VERSION ""

NS_ :

BS_:

BU_: SCCM RF_HUB PTS ORC OCM IC HCP HALF ETM ESM ESC EPS ECM EBCM DIAGNOST DASM CBC AirSusp TCM DTCM ELSDM

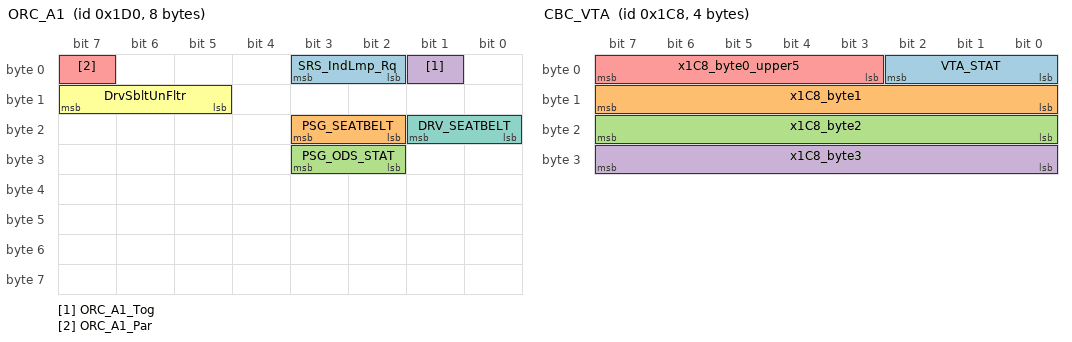
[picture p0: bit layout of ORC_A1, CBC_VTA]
BO_ 464 ORC_A1: 8 ORC
 SG_ SRS_IndLmp_Rq : 2|2@1+ (1,0) [0|0] ""  IC,ETM
 SG_ PSG_SEATBELT : 18|2@1+ (1,0) [0|0] ""  IC,ETM
 SG_ PSG_ODS_STAT : 26|2@1+ (1,0) [0|0] ""  IC
 SG_ ORC_A1_Tog : 1|1@1+ (1,0) [0|0] ""  DASM
 SG_ ORC_A1_Par : 7|1@1+ (1,0) [0|0] ""  DASM
 SG_ DrvSbltUnFltr : 13|3@1+ (1,0) [0|0] ""  ECM
 SG_ DRV_SEATBELT : 16|2@1+ (1,0) [0|0] ""  IC,ETM,ESC,DASM

BO_ 456 CBC_VTA: 4 CBC
 SG_ VTA_STAT : 0|3@1+ (1,0) [0|0] ""  ETM,RF_HUB
 SG_ x1C8_byte1 : 8|8@1+ (1,0) [0|255] "" Vector__XXX
 SG_ x1C8_byte2 : 16|8@1+ (1,0) [0|255] "" Vector__XXX
 SG_ x1C8_byte3 : 24|8@1+ (1,0) [0|255] "" Vector__XXX
 SG_ x1C8_byte0_upper5 : 3|5@1+ (1,0) [0|31] "" Vector__XXX

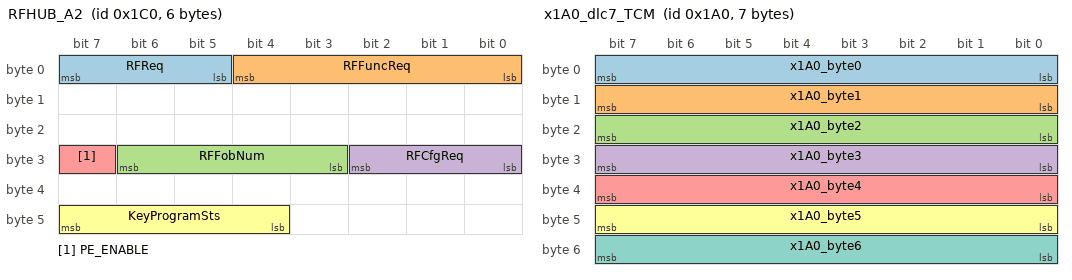
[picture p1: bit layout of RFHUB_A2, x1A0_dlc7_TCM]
BO_ 448 RFHUB_A2: 6 RF_HUB
 SG_ RFReq : 5|3@1+ (1,0) [0|0] ""  IC,CBC
 SG_ RFFuncReq : 0|5@1+ (1,0) [0|0] ""  IC,CBC
 SG_ RFFobNum : 27|4@1+ (1,0) [0|0] ""  CBC
 SG_ RFCfgReq : 24|3@1+ (1,0) [0|0] ""  CBC
 SG_ PE_ENABLE : 31|1@1+ (1,0) [0|0] ""  CBC
 SG_ KeyProgramSts : 44|4@1+ (1,0) [0|0] ""  IC

BO_ 416 x1A0_dlc7_TCM: 7 TCM
 SG_ x1A0_byte0 : 0|8@1+ (1,0) [0|255] "" Vector__XXX
 SG_ x1A0_byte1 : 8|8@1+ (1,0) [0|255] "" Vector__XXX
 SG_ x1A0_byte2 : 16|8@1+ (1,0) [0|255] "" Vector__XXX
 SG_ x1A0_byte3 : 24|8@1+ (1,0) [0|255] "" Vector__XXX
 SG_ x1A0_byte4 : 32|8@1+ (1,0) [0|255] "" Vector__XXX
 SG_ x1A0_byte5 : 40|8@1+ (1,0) [0|255] "" Vector__XXX
 SG_ x1A0_byte6 : 48|8@1+ (1,0) [0|255] "" Vector__XXX

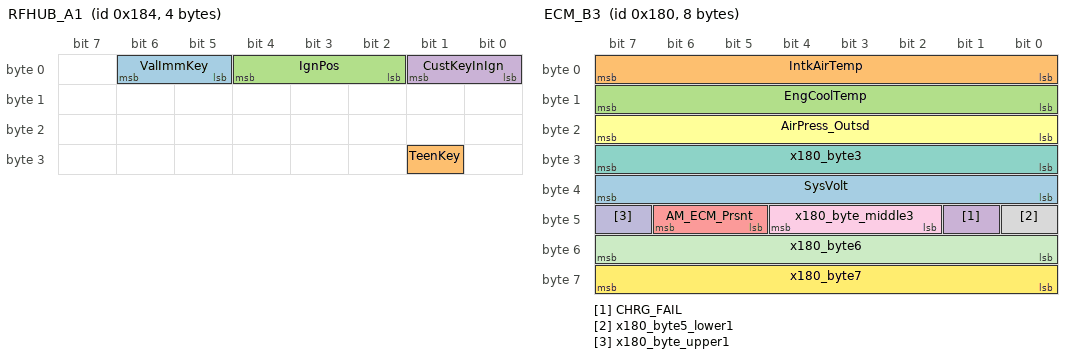
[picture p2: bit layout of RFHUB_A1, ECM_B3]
BO_ 388 RFHUB_A1: 4 RF_HUB
 SG_ ValImmKey : 5|2@1+ (1,0) [0|0] ""  CBC
 SG_ TeenKey : 25|1@1+ (1,0) [0|0] ""  CBC
 SG_ IgnPos : 2|3@1+ (1,0) [0|0] ""  CBC
 SG_ CustKeyInIgn : 0|2@1+ (1,0) [0|0] ""  CBC

BO_ 384 ECM_B3: 8 ECM
 SG_ SysVolt : 32|8@1+ (0.0618,0) [0|15.6972] "Volts"  HCP
 SG_ IntkAirTemp : 0|8@1+ (1,-40) [-40|214] "°C" Vector__XXX
 SG_ EngCoolTemp : 8|8@1+ (1,-40) [-40|214] "°C"  IC,ETM,ESC,CBC
 SG_ CHRG_FAIL : 41|1@1+ (1,0) [0|0] ""  IC,ETM
 SG_ AM_ECM_Prsnt : 45|2@1+ (1,0) [0|0] ""  CBC
 SG_ AirPress_Outsd : 16|8@1+ (1,0) [0|254] "kPaA"  RF_HUB,DASM
 SG_ x180_byte3 : 24|8@1+ (1,0) [0|0] "" Vector__XXX
 SG_ x180_byte5_lower1 : 40|1@1+ (1,0) [0|0] "" Vector__XXX
 SG_ x180_byte_middle3 : 42|3@1+ (1,0) [0|0] "" Vector__XXX
 SG_ x180_byte_upper1 : 47|1@1+ (1,0) [0|0] "" Vector__XXX
 SG_ x180_byte6 : 48|8@1+ (1,0) [0|0] "" Vector__XXX
 SG_ x180_byte7 : 56|8@1+ (1,0) [0|0] "" Vector__XXX

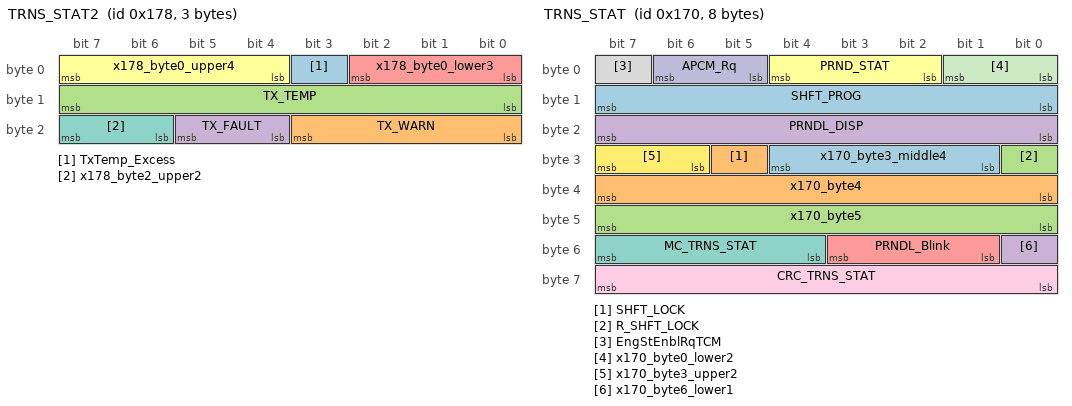
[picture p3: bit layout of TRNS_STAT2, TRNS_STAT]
BO_ 376 TRNS_STAT2: 3 TCM
 SG_ TxTemp_Excess : 3|1@1+ (1,0) [0|0] ""  IC,ETM
 SG_ TX_WARN : 16|4@1+ (1,0) [0|0] ""  IC
 SG_ TX_TEMP : 8|8@1+ (1,-50) [-50|204] "°C"  IC,HCP
 SG_ TX_FAULT : 20|2@1+ (1,0) [0|0] ""  RF_HUB,ECM
 SG_ x178_byte0_lower3 : 0|3@1+ (1,0) [0|7] "" Vector__XXX
 SG_ x178_byte0_upper4 : 4|4@1+ (1,0) [0|15] "" Vector__XXX
 SG_ x178_byte2_upper2 : 22|2@1+ (1,0) [0|3] "" Vector__XXX

BO_ 368 TRNS_STAT: 8 TCM
 SG_ SHFT_PROG : 8|8@1+ (1,0) [0|0] ""  ESC,ECM
 SG_ SHFT_LOCK : 29|1@1+ (1,0) [0|0] ""  ESM
 SG_ R_SHFT_LOCK : 24|1@1+ (1,0) [0|0] ""  ESM
 SG_ PRNDL_DISP : 16|8@1+ (1,0) [0|0] ""  ORC,IC,ESM,ESC,ECM,CBC
 SG_ PRNDL_Blink : 49|3@1+ (1,0) [0|0] ""  IC,ESM
 SG_ PRND_STAT : 2|3@1+ (1,0) [0|0] ""  PTS,ORC,IC,ESC,EPS,ECM,DASM,CBC
 SG_ MC_TRNS_STAT : 52|4@1+ (1,0) [0|15] ""  PTS,ESM,ESC,ECM,DASM
 SG_ EngStEnblRqTCM : 7|1@1+ (1,0) [0|0] "" Vector__XXX
 SG_ CRC_TRNS_STAT : 56|8@1+ (1,0) [0|0] ""  PTS,ESM,ESC,ECM,DASM
 SG_ APCM_Rq : 5|2@1+ (1,0) [0|0] ""  ESM
 SG_ x170_byte0_lower2 : 0|2@1+ (1,0) [0|0] "" Vector__XXX
 SG_ x170_byte3_upper2 : 30|2@1+ (1,0) [0|3] "" Vector__XXX
 SG_ x170_byte3_middle4 : 25|4@1+ (1,0) [0|15] "" Vector__XXX
 SG_ x170_byte4 : 32|8@1+ (1,0) [0|255] "" Vector__XXX
 SG_ x170_byte5 : 40|8@1+ (1,0) [0|255] "" Vector__XXX
 SG_ x170_byte6_lower1 : 48|1@1+ (1,0) [0|1] "" Vector__XXX

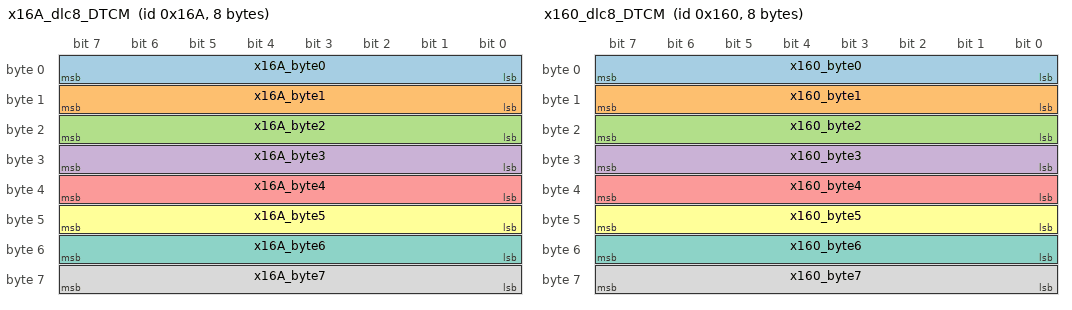
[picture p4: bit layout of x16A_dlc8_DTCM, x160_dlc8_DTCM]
BO_ 362 x16A_dlc8_DTCM: 8 DTCM
 SG_ x16A_byte0 : 0|8@1+ (1,0) [0|255] "" Vector__XXX
 SG_ x16A_byte1 : 8|8@1+ (1,0) [0|255] "" Vector__XXX
 SG_ x16A_byte2 : 16|8@1+ (1,0) [0|255] "" Vector__XXX
 SG_ x16A_byte3 : 24|8@1+ (1,0) [0|255] "" Vector__XXX
 SG_ x16A_byte4 : 32|8@1+ (1,0) [0|255] "" Vector__XXX
 SG_ x16A_byte5 : 40|8@1+ (1,0) [0|255] "" Vector__XXX
 SG_ x16A_byte6 : 48|8@1+ (1,0) [0|255] "" Vector__XXX
 SG_ x16A_byte7 : 56|8@1+ (1,0) [0|255] "" Vector__XXX

BO_ 352 x160_dlc8_DTCM: 8 DTCM
 SG_ x160_byte0 : 0|8@1+ (1,0) [0|255] "" Vector__XXX
 SG_ x160_byte1 : 8|8@1+ (1,0) [0|255] "" Vector__XXX
 SG_ x160_byte2 : 16|8@1+ (1,0) [0|255] "" Vector__XXX
 SG_ x160_byte3 : 24|8@1+ (1,0) [0|255] "" Vector__XXX
 SG_ x160_byte4 : 32|8@1+ (1,0) [0|255] "" Vector__XXX
 SG_ x160_byte5 : 40|8@1+ (1,0) [0|255] "" Vector__XXX
 SG_ x160_byte6 : 48|8@1+ (1,0) [0|255] "" Vector__XXX
 SG_ x160_byte7 : 56|8@1+ (1,0) [0|255] "" Vector__XXX

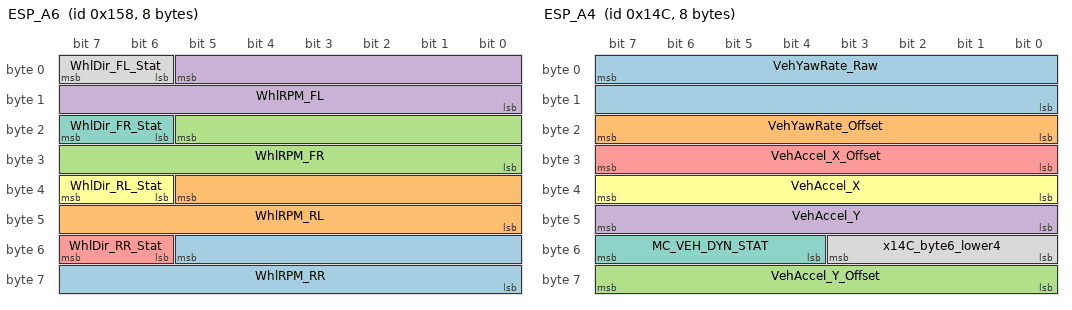
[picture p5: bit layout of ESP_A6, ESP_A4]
BO_ 344 ESP_A6: 8 ESC
 SG_ WhlRPM_RR : 53|14@0+ (0.5,0) [0|8191] "rpm"  PTS,ORC,HCP,DASM
 SG_ WhlRPM_RL : 37|14@0+ (0.5,0) [0|8191] "rpm"  PTS,ORC,HCP,DASM
 SG_ WhlRPM_FR : 21|14@0+ (0.5,0) [0|8191] "rpm"  PTS,ORC,HCP,DASM
 SG_ WhlRPM_FL : 5|14@0+ (0.5,0) [0|8191] "rpm"  PTS,ORC,HCP,DASM
 SG_ WhlDir_RR_Stat : 54|2@1+ (1,0) [0|0] ""  PTS,ORC,HCP,EPS,DASM
 SG_ WhlDir_RL_Stat : 38|2@1+ (1,0) [0|0] ""  PTS,ORC,HCP,EPS,DASM
 SG_ WhlDir_FR_Stat : 22|2@1+ (1,0) [0|0] ""  HCP,DASM
 SG_ WhlDir_FL_Stat : 6|2@1+ (1,0) [0|0] ""  HCP,DASM

BO_ 332 ESP_A4: 8 ESC
 SG_ VehYawRate_Raw : 7|16@0+ (0.01,-327.68) [-327.68|327.66] "°/s"  PTS,HALF,ETM,DASM,CBC
 SG_ VehYawRate_Offset : 16|8@1+ (0.08,-10.24) [-6.96|6.96] ""  ORC,HALF,DASM
 SG_ VehAccel_Y_Offset : 56|8@1+ (0.02,-2.56) [-2.56|2.52] "m/s²"  HALF,ETM,ECM,DASM
 SG_ VehAccel_Y : 40|8@1+ (0.08,-10.24) [-10.24|10.08] "m/s²"  HALF,EPS,ECM,DASM
 SG_ VehAccel_X_Offset : 24|8@1+ (0.02,-2.56) [-2.56|2.52] "m/s²"  PTS,HCP,HALF,ETM,ECM,DASM
 SG_ VehAccel_X : 32|8@1+ (0.08,-10.24) [-10.24|10.08] "m/s²"  PTS,HCP,HALF,EPS,ECM,DASM,CBC
 SG_ MC_VEH_DYN_STAT : 52|4@1+ (1,0) [0|15] ""  PTS,ORC,HALF,ETM,ECM,DASM
 SG_ x14C_byte6_lower4 : 48|4@1+ (1,0) [0|15] "" Vector__XXX

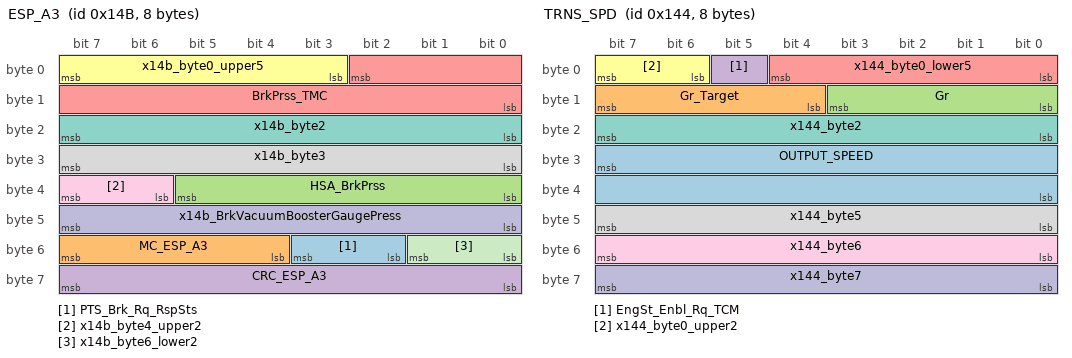
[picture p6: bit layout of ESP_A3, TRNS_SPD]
BO_ 331 ESP_A3: 8 ESC
 SG_ PTS_Brk_Rq_RspSts : 50|2@1+ (1,0) [0|0] ""  PTS,IC
 SG_ MC_ESP_A3 : 52|4@1+ (1,0) [0|15] ""  PTS,ORC,HCP,ECM
 SG_ HSA_BrkPrss : 32|6@1+ (1,0) [0|50] "bar"  ORC,ETM,ECM
 SG_ CRC_ESP_A3 : 56|8@1+ (1,0) [0|0] ""  PTS,ORC,HCP,ECM
 SG_ BrkPrss_TMC : 2|11@0+ (0.1,0) [0|200] "bar"  ORC,HCP,HALF,ETM,ECM
 SG_ x14b_byte0_upper5 : 3|5@1+ (1,0) [0|31] "" Vector__XXX
 SG_ x14b_byte2 : 16|8@1+ (1,0) [0|255] "" Vector__XXX
 SG_ x14b_byte3 : 24|8@1+ (1,0) [0|255] "" Vector__XXX
 SG_ x14b_byte4_upper2 : 38|2@1+ (1,0) [0|3] "" Vector__XXX
 SG_ x14b_BrkVacuumBoosterGaugePress : 40|8@1+ (-0.8,20.8) [-100|0] "kPa_gauge" Vector__XXX
 SG_ x14b_byte6_lower2 : 48|2@1+ (1,0) [0|3] "" Vector__XXX

BO_ 324 TRNS_SPD: 8 TCM
 SG_ OUTPUT_SPEED : 31|16@0+ (1,0) [0|65534] "rpm"  ECM
 SG_ Gr_Target : 12|4@1+ (1,0) [0|0] ""  ESC,ECM,CBC
 SG_ Gr : 8|4@1+ (1,0) [0|0] ""  RF_HUB,ORC,IC,HALF,ESC,EPS,ECM,CBC
 SG_ EngSt_Enbl_Rq_TCM : 5|1@1+ (1,0) [0|0] ""  RF_HUB,ECM
 SG_ x144_byte0_lower5 : 0|5@1+ (1,0) [0|31] "" Vector__XXX
 SG_ x144_byte0_upper2 : 6|2@1+ (1,0) [0|3] "" Vector__XXX
 SG_ x144_byte2 : 16|8@1+ (1,0) [0|255] "" Vector__XXX
 SG_ x144_byte5 : 40|8@1+ (1,0) [0|255] "" Vector__XXX
 SG_ x144_byte6 : 48|8@1+ (1,0) [0|255] "" Vector__XXX
 SG_ x144_byte7 : 56|8@1+ (1,0) [0|255] "" Vector__XXX

BO_ 320 ESP_A1: 8 ESC
 SG_ SPCR_AS_Off_Rq : 38|2@1+ (1,0) [0|0] ""  ECM,DASM
 SG_ RollTestMd_Actv : 30|2@1+ (1,0) [0|0] ""  DASM
 SG_ REF_VEH_SPEED : 33|10@0+ (0.5,0) [0|511] "km/h"  ORC,HCP
 SG_ MC_Brk_Stat : 52|4@1+ (1,0) [0|15] ""  PTS,ORC,IC,HCP,HALF,ECM,DASM
 SG_ FullBrk_Actv : 9|1@1+ (1,0) [0|0] ""  ORC
 SG_ ESP_Sys_Stat : 10|2@1+ (1,0) [0|0] ""  PTS,HALF,ETM,ECM,DASM
 SG_ EmgBrk_Actv : 8|1@1+ (1,0) [0|0] ""  ORC
 SG_ DTR_CC_Engaged : 15|1@1+ (1,0) [0|0] ""  HCP,ECM,CBC
 SG_ DTR_CC_Enabled : 23|1@1+ (1,0) [0|0] ""  ECM
 SG_ CRC_Brk_Stat : 56|8@1+ (1,0) [0|0] ""  PTS,ORC,IC,HCP,HALF,ECM,DASM
 SG_ BrkPdl_Stat : 2|2@1+ (1,0) [0|0] ""  RF_HUB,ORC,HCP,HALF,ECM,DASM,CBC
 SG_ BrkPdl_Flt : 4|1@1+ (1,0) [0|0] ""  HALF,ECM,DASM
 SG_ BrkIntrvntn_Enbl : 7|1@1+ (1,0) [0|0] ""  ORC,ECM
 SG_ BrkIntrvntn_Actv_ESP : 5|1@1+ (1,0) [0|0] ""  PTS,ORC,HALF,ETM
 SG_ BrkIntrvntn_Actv_AS : 6|1@1+ (1,0) [0|0] ""  ETM,DASM
 SG_ Brk_Thermdl : 25|1@1+ (1,0) [0|0] ""  DASM
 SG_ Brk_Stat : 0|2@1+ (1,0) [0|0] ""  PTS,HALF,ECM,DASM,CBC
 SG_ ABS_BrkEvt : 14|1@1+ (1,0) [0|0] ""  PTS,ORC,HALF,DASM
 SG_ x140_byte1_middle2 : 12|2@1+ (1,0) [0|3] "" Vector__XXX
 SG_ x140_byte2_lower7 : 16|7@1+ (1,0) [0|127] "" Vector__XXX
 SG_ x140_byte3_lower1 : 24|1@1+ (1,0) [0|1] "" Vector__XXX
 SG_ x140_byte3_middle4 : 26|4@1+ (1,0) [0|15] "" Vector__XXX
 SG_ x140_byte4_middle4 : 34|4@1+ (1,0) [0|15] "" Vector__XXX
 SG_ x140_byte6_lower4 : 48|4@1+ (1,0) [0|15] "" Vector__XXX

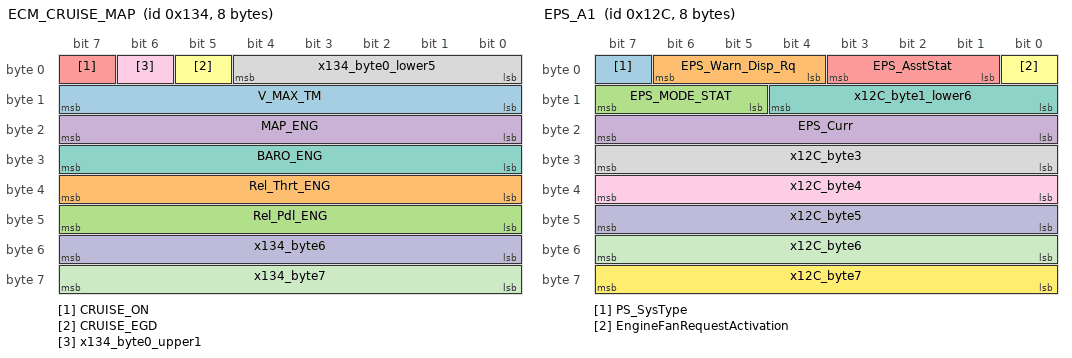
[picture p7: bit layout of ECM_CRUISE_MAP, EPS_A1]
BO_ 308 ECM_CRUISE_MAP: 8 ECM
 SG_ V_MAX_TM : 8|8@1+ (1,0) [0|250] "km/h(mph)"  HCP
 SG_ Rel_Thrt_ENG : 32|8@1+ (0.019607843,0) [0|4.98] "Volts"  ESC
 SG_ Rel_Pdl_ENG : 40|8@1+ (0.019607843,0) [0|4.98] "Volts"  ESC
 SG_ MAP_ENG : 16|8@1+ (0.8,0) [0|203.2] "kPa"  ETM,ESC
 SG_ CRUISE_ON : 7|1@1+ (1,0) [0|0] ""  ORC,IC,ESC
 SG_ CRUISE_EGD : 5|1@1+ (1,0) [0|0] ""  ORC,IC,HCP,ESC,CBC
 SG_ BARO_ENG : 24|8@1+ (1,0) [0|254] "kPaA"  ESC
 SG_ x134_byte0_lower5 : 0|5@1+ (1,0) [0|0] "" Vector__XXX
 SG_ x134_byte0_upper1 : 6|1@1+ (1,0) [0|0] "" Vector__XXX
 SG_ x134_byte6 : 48|8@1+ (1,0) [0|0] "" Vector__XXX
 SG_ x134_byte7 : 56|8@1+ (1,0) [0|0] "" Vector__XXX

BO_ 300 EPS_A1: 8 EPS
 SG_ PS_SysType : 7|1@1+ (1,0) [0|0] ""  ESC,CBC
 SG_ EPS_Warn_Disp_Rq : 4|3@1+ (1,0) [0|0] ""  ORC,IC,ETM,CBC
 SG_ EPS_MODE_STAT : 13|3@1+ (1,0) [0|0] ""  ORC,HALF,CBC
 SG_ EPS_Curr : 16|8@1+ (1,-50) [-50|204] "Amp" Vector__XXX
 SG_ EPS_AsstStat : 1|3@1+ (1,0) [0|0] ""  ESC
 SG_ EngineFanRequestActivation : 0|1@1+ (1,0) [0|0] ""  ECM
 SG_ x12C_byte1_lower6 : 8|5@1+ (1,0) [0|31] "" Vector__XXX
 SG_ x12C_byte3 : 24|8@1+ (1,0) [0|255] "" Vector__XXX
 SG_ x12C_byte4 : 32|8@1+ (1,0) [0|255] "" Vector__XXX
 SG_ x12C_byte5 : 40|8@1+ (1,0) [0|255] "" Vector__XXX
 SG_ x12C_byte6 : 48|8@1+ (1,0) [0|255] "" Vector__XXX
 SG_ x12C_byte7 : 56|8@1+ (1,0) [0|255] "" Vector__XXX

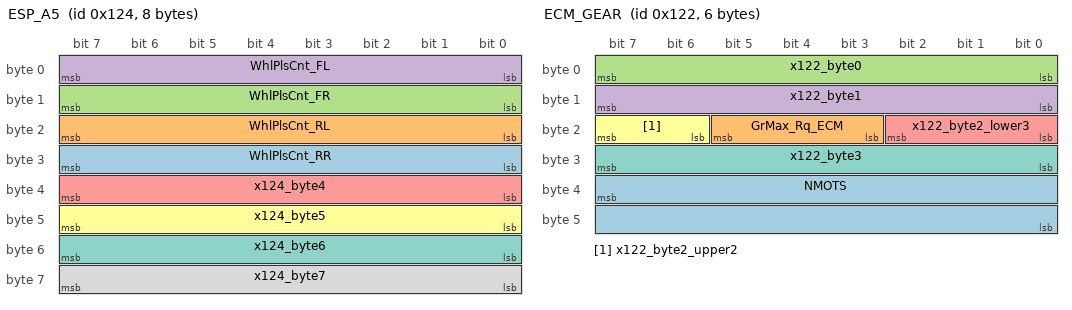
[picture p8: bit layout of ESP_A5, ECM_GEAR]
BO_ 292 ESP_A5: 8 ESC
 SG_ WhlPlsCnt_RR : 24|8@1+ (1,0) [0|254] "Impulse"  RF_HUB,PTS,EPS,DASM,CBC
 SG_ WhlPlsCnt_RL : 16|8@1+ (1,0) [0|254] "Impulse"  RF_HUB,PTS,EPS,DASM,CBC
 SG_ WhlPlsCnt_FR : 8|8@1+ (1,0) [0|254] "Impulse"  RF_HUB,PTS,DASM,CBC
 SG_ WhlPlsCnt_FL : 0|8@1+ (1,0) [0|254] "Impulse"  RF_HUB,PTS,DASM,CBC
 SG_ x124_byte4 : 32|8@1+ (1,0) [0|255] "" Vector__XXX
 SG_ x124_byte5 : 40|8@1+ (1,0) [0|255] "" Vector__XXX
 SG_ x124_byte6 : 48|8@1+ (1,0) [0|255] "" Vector__XXX
 SG_ x124_byte7 : 56|8@1+ (1,0) [0|255] "" Vector__XXX

BO_ 290 ECM_GEAR: 6 ECM
 SG_ NMOTS : 39|16@0+ (1,0) [0|65534] "rpm"  ESC
 SG_ GrMax_Rq_ECM : 19|3@1+ (1,0) [0|0] "" Vector__XXX
 SG_ x122_byte0 : 0|8@1+ (1,0) [0|0] "" Vector__XXX
 SG_ x122_byte1 : 8|8@1+ (1,0) [0|0] "" Vector__XXX
 SG_ x122_byte2_lower3 : 16|3@1+ (1,0) [0|0] "" Vector__XXX
 SG_ x122_byte2_upper2 : 22|2@1+ (1,0) [0|0] "" Vector__XXX
 SG_ x122_byte3 : 24|8@1+ (1,0) [0|0] "" Vector__XXX

BO_ 288 ECM_A2: 7 ECM
 SG_ RPMOverRev : 42|1@1+ (1,0) [0|0] "" Vector__XXX
 SG_ MC_ECM_A2 : 44|4@1+ (1,0) [0|15] ""  HALF,DASM,ESC
 SG_ LV12PwrFreeRq : 43|1@1+ (1,0) [0|0] ""  DASM,ESC
 SG_ ESS_RqShftPark : 41|1@1+ (1,0) [0|0] ""  ORC
 SG_ EngTrq_Enbl_Rq_ESC : 6|1@1+ (1,0) [0|0] ""  DASM,ESC
 SG_ EngTrq_Enbl_Rq_AS : 5|1@1+ (1,0) [0|0] ""  ESC,DASM
 SG_ ECM_LHOM : 29|1@1+ (1,0) [0|0] ""  DASM
 SG_ CRUISE_OVERRIDE : 31|1@1+ (1,0) [0|0] ""  ORC,HCP,ESC,DASM
 SG_ CRC_ECM_A2 : 48|8@1+ (1,0) [0|0] ""  HALF,DASM,ESC
 SG_ AccelPdlPosnSens_Flt : 30|1@1+ (1,0) [0|0] ""  HALF,DASM,ESC,CBC
 SG_ AccelPdlPosn : 16|8@1+ (0.4,0) [0|100] "%"  HALF,ESC,CBC
 SG_ x120_byte0_lower5 : 0|5@1+ (1,0) [0|0] "" Vector__XXX
 SG_ x120_byte0_upper1 : 7|1@1+ (1,0) [0|0] "" Vector__XXX
 SG_ x120_byte1 : 8|8@1+ (1,0) [0|0] "" Vector__XXX
 SG_ x120_byte3_lower5 : 24|5@1+ (1,0) [0|0] "" Vector__XXX
 SG_ x120_byte4 : 32|8@1+ (1,0) [0|0] "" Vector__XXX
 SG_ x120_byte5_lowre1 : 40|1@1+ (1,0) [0|0] "" Vector__XXX

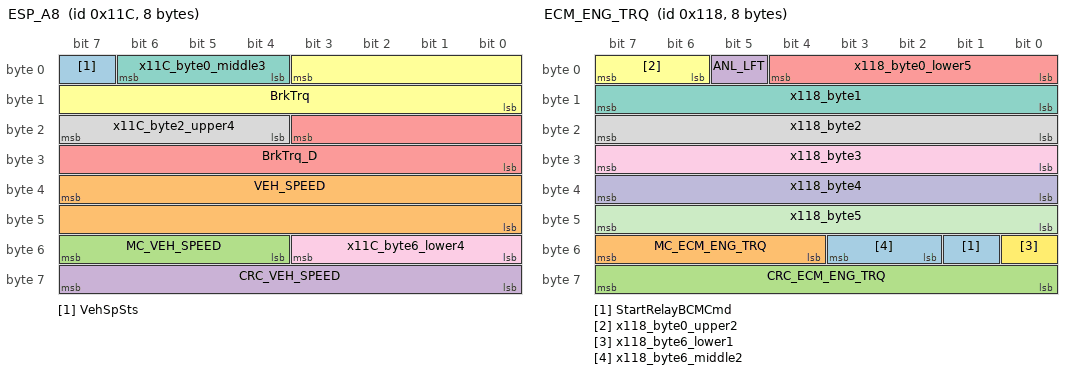
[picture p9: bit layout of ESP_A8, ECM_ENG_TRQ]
BO_ 284 ESP_A8: 8 ESC
 SG_ VehSpSts : 7|1@1+ (1,0) [0|0] ""  DASM
 SG_ VEH_SPEED : 39|16@0+ (0.0078125,0) [0|511.984375] "km/h"  RF_HUB,PTS,ORC,IC,HCP,HALF,EPS,ECM,EBCM,DASM,CBC
 SG_ MC_VEH_SPEED : 52|4@1+ (1,0) [0|15] ""  PTS,ORC,IC,HCP,HALF,ESM,EPS,ECM,DASM
 SG_ CRC_VEH_SPEED : 56|8@1+ (1,0) [0|0] ""  PTS,ORC,IC,HCP,HALF,ESM,EPS,ECM,DASM
 SG_ BrkTrq_D : 19|12@0+ (3,0) [0|12282] "Nm"  DASM
 SG_ BrkTrq : 3|12@0+ (3,0) [0|12282] "Nm"  ORC,DASM
 SG_ x11C_byte0_middle3 : 4|3@1+ (1,0) [0|7] "" Vector__XXX
 SG_ x11C_byte2_upper4 : 20|4@1+ (1,0) [0|15] "" Vector__XXX
 SG_ x11C_byte6_lower4 : 48|4@1+ (1,0) [0|15] "" Vector__XXX

BO_ 280 ECM_ENG_TRQ: 8 ECM
 SG_ StartRelayBCMCmd : 49|1@1+ (1,0) [0|0] ""  CBC
 SG_ MC_ECM_ENG_TRQ : 52|4@1+ (1,0) [0|15] ""  ESC
 SG_ CRC_ECM_ENG_TRQ : 56|8@1+ (1,0) [0|0] ""  DASM,ESC
 SG_ ANL_LFT : 5|1@1+ (1,0) [0|0] ""  CBC
 SG_ x118_byte0_lower5 : 0|5@1+ (1,0) [0|0] "" Vector__XXX
 SG_ x118_byte0_upper2 : 6|2@1+ (1,0) [0|0] "" Vector__XXX
 SG_ x118_byte1 : 8|8@1+ (1,0) [0|0] "" Vector__XXX
 SG_ x118_byte2 : 16|8@1+ (1,0) [0|0] "" Vector__XXX
 SG_ x118_byte3 : 24|8@1+ (1,0) [0|0] "" Vector__XXX
 SG_ x118_byte4 : 32|8@1+ (1,0) [0|0] "" Vector__XXX
 SG_ x118_byte5 : 40|8@1+ (1,0) [0|0] "" Vector__XXX
 SG_ x118_byte6_lower1 : 48|1@1+ (1,0) [0|0] "" Vector__XXX
 SG_ x118_byte6_middle2 : 50|2@1+ (1,0) [0|0] "" Vector__XXX

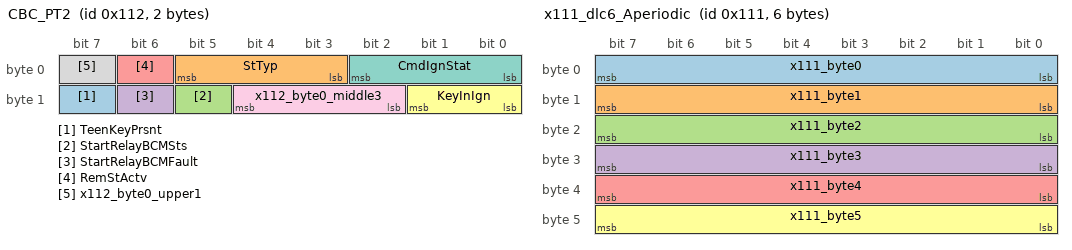
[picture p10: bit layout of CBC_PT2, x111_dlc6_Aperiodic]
BO_ 274 CBC_PT2: 2 CBC
 SG_ TeenKeyPrsnt : 15|1@1+ (1,0) [0|0] ""  PTS,ORC,IC,ECM,DASM
 SG_ StTyp : 3|3@1+ (1,0) [0|0] ""  RF_HUB
 SG_ StartRelayBCMSts : 13|1@1+ (1,0) [0|0] ""  ECM
 SG_ StartRelayBCMFault : 14|1@1+ (1,0) [0|0] ""  ECM
 SG_ RemStActv : 6|1@1+ (1,0) [0|0] ""  RF_HUB,IC,HCP,ESM,ECM
 SG_ KeyInIgn : 8|2@1+ (1,0) [0|0] ""  RF_HUB,IC,HCP,ESM
 SG_ CmdIgnStat : 0|3@1+ (1,0) [0|0] ""  SCCM,RF_HUB,PTS,ORC,OCM,IC,HCP,HALF,ESM,ESC,EPS,ECM,EBCM,DASM
 SG_ x112_byte0_upper1 : 7|1@1+ (1,0) [0|1] "" Vector__XXX
 SG_ x112_byte0_middle3 : 10|3@1+ (1,0) [0|7] "" Vector__XXX

BO_ 273 x111_dlc6_Aperiodic: 6 Vector__XXX
 SG_ x111_byte0 : 0|8@1+ (1,0) [0|255] "" Vector__XXX
 SG_ x111_byte1 : 8|8@1+ (1,0) [0|255] "" Vector__XXX
 SG_ x111_byte2 : 16|8@1+ (1,0) [0|255] "" Vector__XXX
 SG_ x111_byte3 : 24|8@1+ (1,0) [0|255] "" Vector__XXX
 SG_ x111_byte4 : 32|8@1+ (1,0) [0|255] "" Vector__XXX
 SG_ x111_byte5 : 40|8@1+ (1,0) [0|255] "" Vector__XXX

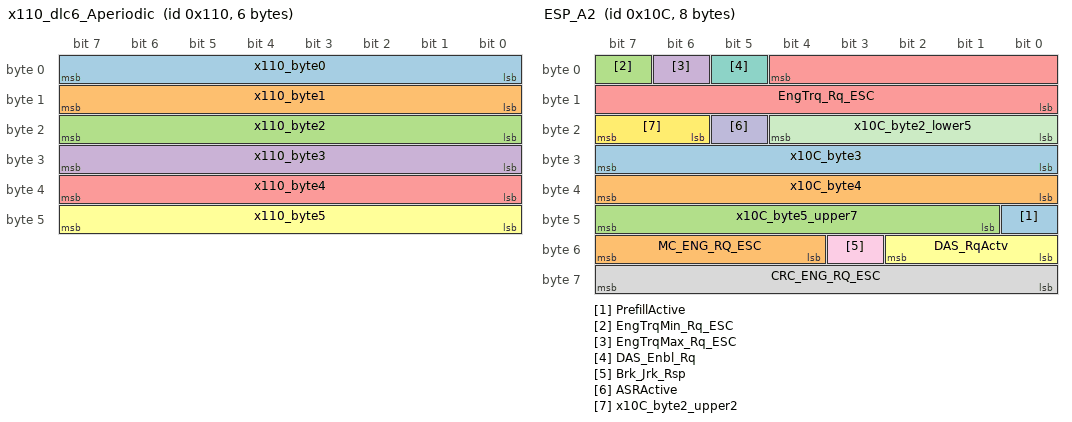
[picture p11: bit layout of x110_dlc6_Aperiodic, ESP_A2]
BO_ 272 x110_dlc6_Aperiodic: 6 Vector__XXX
 SG_ x110_byte0 : 0|8@1+ (1,0) [0|255] "" Vector__XXX
 SG_ x110_byte1 : 8|8@1+ (1,0) [0|255] "" Vector__XXX
 SG_ x110_byte2 : 16|8@1+ (1,0) [0|255] "" Vector__XXX
 SG_ x110_byte3 : 24|8@1+ (1,0) [0|255] "" Vector__XXX
 SG_ x110_byte4 : 32|8@1+ (1,0) [0|255] "" Vector__XXX
 SG_ x110_byte5 : 40|8@1+ (1,0) [0|255] "" Vector__XXX

BO_ 268 ESP_A2: 8 ESC
 SG_ PrefillActive : 40|1@1+ (1,0) [0|0] ""  DASM
 SG_ MC_ENG_RQ_ESC : 52|4@1+ (1,0) [0|15] ""  ECM,DASM
 SG_ EngTrqMin_Rq_ESC : 7|1@1+ (1,0) [0|0] "" Vector__XXX
 SG_ EngTrqMax_Rq_ESC : 6|1@1+ (1,0) [0|0] "" Vector__XXX
 SG_ EngTrq_Rq_ESC : 4|13@0+ (0.25,-500) [-500|1547.5] "Nm"  ETM
 SG_ DAS_RqActv : 48|3@1+ (1,0) [0|0] ""  ORC,HALF,DASM
 SG_ DAS_Enbl_Rq : 5|1@1+ (1,0) [0|0] ""  ECM,DASM
 SG_ CRC_ENG_RQ_ESC : 56|8@1+ (1,0) [0|0] ""  ECM,DASM
 SG_ Brk_Jrk_Rsp : 51|1@1+ (1,0) [0|0] ""  ORC,DASM
 SG_ ASRActive : 21|1@1+ (1,0) [0|0] ""  ORC,DASM
 SG_ x10C_byte2_lower5 : 16|5@1+ (1,0) [0|31] "" Vector__XXX
 SG_ x10C_byte2_upper2 : 22|2@1+ (1,0) [0|3] "" Vector__XXX
 SG_ x10C_byte3 : 24|8@1+ (1,0) [0|255] "" Vector__XXX
 SG_ x10C_byte4 : 32|8@1+ (1,0) [0|255] "" Vector__XXX
 SG_ x10C_byte5_upper7 : 41|7@1+ (1,0) [0|127] "" Vector__XXX

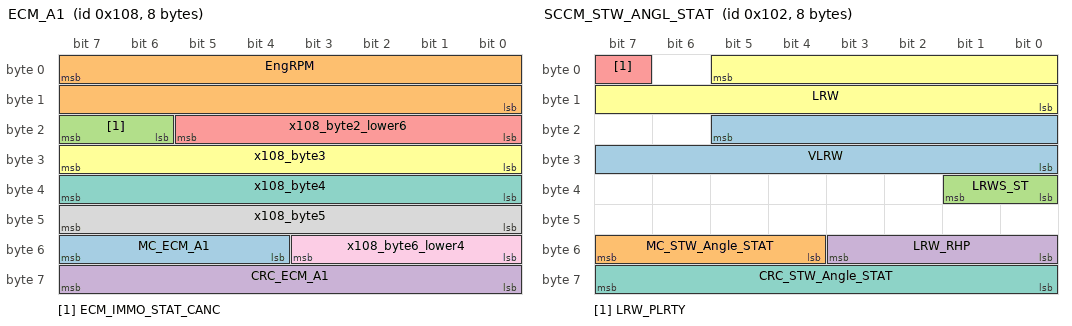
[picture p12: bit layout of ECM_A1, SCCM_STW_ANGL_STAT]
BO_ 264 ECM_A1: 8 ECM
 SG_ MC_ECM_A1 : 52|4@1+ (1,0) [0|15] ""  HALF,DASM,ESC
 SG_ EngRPM : 7|16@0+ (1,0) [0|65534] "rpm"  RF_HUB,ORC,IC,HALF,ESC,EPS,EBCM,CBC
 SG_ ECM_IMMO_STAT_CANC : 22|2@1+ (1,0) [0|0] ""  HCP,CBC
 SG_ CRC_ECM_A1 : 56|8@1+ (1,0) [0|0] ""  HALF,DASM,ESC
 SG_ x108_byte2_lower6 : 16|6@1+ (1,0) [0|63] "" Vector__XXX
 SG_ x108_byte3 : 24|8@1+ (1,0) [0|255] "" Vector__XXX
 SG_ x108_byte4 : 32|8@1+ (1,0) [0|255] "" Vector__XXX
 SG_ x108_byte5 : 40|8@1+ (1,0) [0|255] "" Vector__XXX
 SG_ x108_byte6_lower4 : 48|4@1+ (1,0) [0|15] "" Vector__XXX

BO_ 258 SCCM_STW_ANGL_STAT: 8 SCCM
 SG_ VLRW : 21|14@0+ (0.5,-2048) [-2048|2047] "°/s"  HALF,ESC,EPS,ECM,DASM
 SG_ MC_STW_Angle_STAT : 52|4@1+ (1,0) [0|15] ""  PTS,ORC,ETM,ESC,ECM,DASM
 SG_ LRWS_ST : 32|2@1+ (1,0) [0|0] ""  PTS,ORC,HALF,ESC,EPS,DASM,CBC
 SG_ LRW_RHP : 48|4@1+ (0.1,-0.4) [-0.4|0.4] "Degrees"  PTS,HALF,EPS
 SG_ LRW_PLRTY : 7|1@1+ (1,0) [0|0] ""  PTS,ORC,HALF,ESC,EPS,DASM
 SG_ LRW : 5|14@0+ (0.5,-2048) [-2048|2047] "Degrees"  PTS,ORC,HALF,ESC,EPS,ECM,DASM,CBC
 SG_ CRC_STW_Angle_STAT : 56|8@1+ (1,0) [0|0] ""  PTS,ORC,ETM,ESC,ECM,DASM

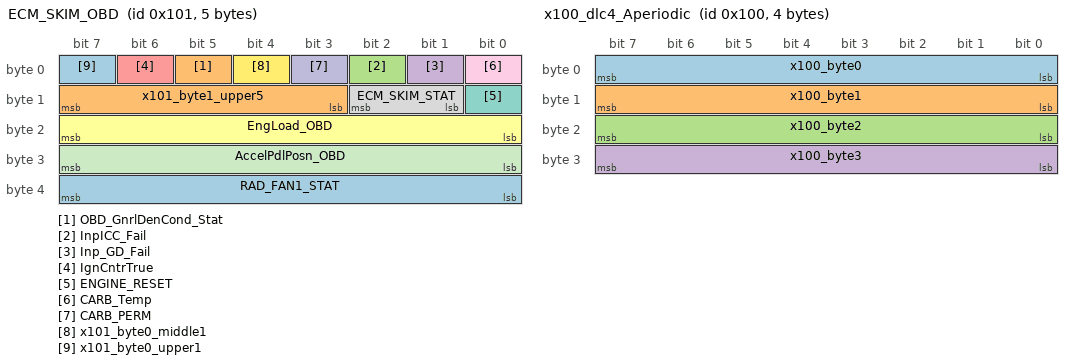
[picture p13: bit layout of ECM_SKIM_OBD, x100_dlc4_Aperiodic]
BO_ 257 ECM_SKIM_OBD: 5 ECM
 SG_ RAD_FAN1_STAT : 32|8@1+ (1,0) [0|100] "%"  ETM
 SG_ OBD_GnrlDenCond_Stat : 5|1@1+ (1,0) [0|0] "" Vector__XXX
 SG_ InpICC_Fail : 2|1@1+ (1,0) [0|0] "" Vector__XXX
 SG_ Inp_GD_Fail : 1|1@1+ (1,0) [0|0] "" Vector__XXX
 SG_ IgnCntrTrue : 6|1@1+ (1,0) [0|0] "" Vector__XXX
 SG_ EngLoad_OBD : 16|8@1+ (0.3922,0) [0|100] "%"  ETM,ESC,EBCM
 SG_ ENGINE_RESET : 8|1@1+ (1,0) [0|0] ""  HCP
 SG_ ECM_SKIM_STAT : 9|2@1+ (1,0) [0|0] "" Vector__XXX
 SG_ CARB_Temp : 0|1@1+ (1,0) [0|0] "" Vector__XXX
 SG_ CARB_PERM : 3|1@1+ (1,0) [0|0] "" Vector__XXX
 SG_ AccelPdlPosn_OBD : 24|8@1+ (0.3922,0) [0|100] "%"  ETM,ESC,EBCM
 SG_ x101_byte0_middle1 : 4|1@1+ (1,0) [0|1] "" Vector__XXX
 SG_ x101_byte0_upper1 : 7|1@1+ (1,0) [0|1] "" Vector__XXX
 SG_ x101_byte1_upper5 : 11|5@1+ (1,0) [0|31] "" Vector__XXX

BO_ 256 x100_dlc4_Aperiodic: 4 Vector__XXX
 SG_ x100_byte0 : 0|8@1+ (1,0) [0|255] "" Vector__XXX
 SG_ x100_byte1 : 8|8@1+ (1,0) [0|255] "" Vector__XXX
 SG_ x100_byte2 : 16|8@1+ (1,0) [0|255] "" Vector__XXX
 SG_ x100_byte3 : 24|8@1+ (1,0) [0|255] "" Vector__XXX

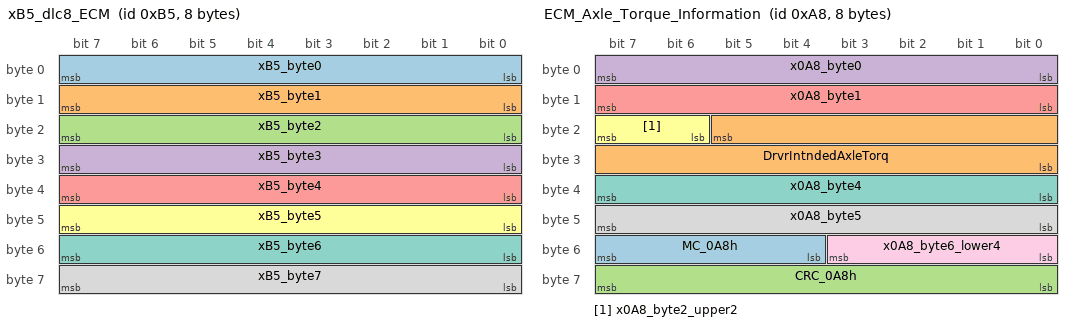
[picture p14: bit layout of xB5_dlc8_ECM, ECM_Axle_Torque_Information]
BO_ 181 xB5_dlc8_ECM: 8 ECM
 SG_ xB5_byte0 : 0|8@1+ (1,0) [0|255] "" Vector__XXX
 SG_ xB5_byte1 : 8|8@1+ (1,0) [0|255] "" Vector__XXX
 SG_ xB5_byte2 : 16|8@1+ (1,0) [0|255] "" Vector__XXX
 SG_ xB5_byte3 : 24|8@1+ (1,0) [0|255] "" Vector__XXX
 SG_ xB5_byte4 : 32|8@1+ (1,0) [0|255] "" Vector__XXX
 SG_ xB5_byte5 : 40|8@1+ (1,0) [0|255] "" Vector__XXX
 SG_ xB5_byte6 : 48|8@1+ (1,0) [0|255] "" Vector__XXX
 SG_ xB5_byte7 : 56|8@1+ (1,0) [0|255] "" Vector__XXX

BO_ 168 ECM_Axle_Torque_Information: 8 ECM
 SG_ MC_0A8h : 52|4@1+ (1,0) [0|15] ""  ESC,DASM
 SG_ DrvrIntndedAxleTorq : 21|14@0+ (1.5625,-4604.688) [-4604.688|20970.3125] "Nm"  ORC,ESC,DASM
 SG_ CRC_0A8h : 56|8@1+ (1,0) [0|0] ""  ESC,DASM
 SG_ x0A8_byte0 : 0|8@1+ (1,0) [0|0] "" Vector__XXX
 SG_ x0A8_byte1 : 8|8@1+ (1,0) [0|0] "" Vector__XXX
 SG_ x0A8_byte2_upper2 : 22|2@1+ (1,0) [0|0] "" Vector__XXX
 SG_ x0A8_byte4 : 32|8@1+ (1,0) [0|0] "" Vector__XXX
 SG_ x0A8_byte5 : 40|8@1+ (1,0) [0|0] "" Vector__XXX
 SG_ x0A8_byte6_lower4 : 48|4@1+ (1,0) [0|0] "" Vector__XXX

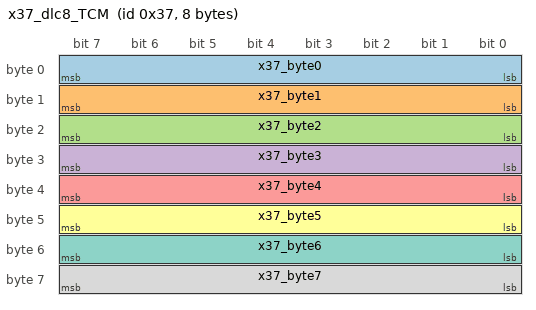
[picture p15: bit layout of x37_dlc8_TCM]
BO_ 55 x37_dlc8_TCM: 8 TCM
 SG_ x37_byte0 : 0|8@1+ (1,0) [0|255] "" Vector__XXX
 SG_ x37_byte1 : 8|8@1+ (1,0) [0|255] "" Vector__XXX
 SG_ x37_byte2 : 16|8@1+ (1,0) [0|255] "" Vector__XXX
 SG_ x37_byte3 : 24|8@1+ (1,0) [0|255] "" Vector__XXX
 SG_ x37_byte4 : 32|8@1+ (1,0) [0|255] "" Vector__XXX
 SG_ x37_byte5 : 40|8@1+ (1,0) [0|255] "" Vector__XXX
 SG_ x37_byte6 : 48|8@1+ (1,0) [0|255] "" Vector__XXX
 SG_ x37_byte7 : 56|8@1+ (1,0) [0|255] "" Vector__XXX

BO_ 2147484177 ESP_A3_NewEagle_A2D_Reads: 8 Vector__XXX
 SG_ NewEagle_BrakePosnSnsrA2d : 0|12@1+ (0.001221001221,0) [0|0] "V" Vector__XXX

BO_ 1083 NM_EBCM: 8 EBCM
 SG_ WakeupRsn_EBCM m2 : 32|8@1+ (1,0) [0|0] "" Vector__XXX
 SG_ WakeupCnt_EBCM m2 : 40|8@1+ (1,0) [0|254] "" Vector__XXX
 SG_ Nw_Id_EBCM : 56|8@1+ (1,0) [0|0] "" Vector__XXX
 SG_ NM_Ud_Srv_EBCM M : 24|8@1+ (1,0) [0|0] "" Vector__XXX
 SG_ NM_Ud_Launch_EBCM : 16|6@1+ (1,0) [0|0] "" Vector__XXX
 SG_ NM_Successor_EBCM : 8|8@1+ (1,0) [0|63] "" Vector__XXX
 SG_ NM_Sleep_Ind_EBCM : 23|1@1+ (1,0) [0|0] "" Vector__XXX
 SG_ NM_Sleep_Ack_EBCM : 22|1@1+ (1,0) [0|0] "" Vector__XXX
 SG_ NM_Mode_EBCM : 0|8@1+ (1,0) [0|0] "" Vector__XXX
 SG_ Awake_NwSt_EBCM m15 : 32|1@1+ (1,0) [0|0] "" Vector__XXX
 SG_ Awake_Diag_Actv_EBCM m15 : 33|1@1+ (1,0) [0|0] "" Vector__XXX

CM_ SG_ 464 SRS_IndLmp_Rq "SRS indication lamp request";
CM_ SG_ 464 PSG_SEATBELT "Passengers seat belt status";
CM_ SG_ 464 PSG_ODS_STAT "Passenger Occupant Detection Sensor Status";
CM_ SG_ 464 ORC_A1_Tog "ORC_A1 toggle bit";
CM_ SG_ 464 ORC_A1_Par "ORC_A1 even parity bit";
CM_ SG_ 464 DrvSbltUnFltr "Drivers seat belt fault status - unfiltered";
CM_ SG_ 464 DRV_SEATBELT "Drivers seat belt status";
CM_ SG_ 456 VTA_STAT "VTA status";
CM_ SG_ 448 RFReq "Who's asking for the request";
CM_ SG_ 448 RFFuncReq "Basic request (RKE, PE, Remstart)";
CM_ SG_ 448 RFFobNum "FOB number making the request";
CM_ SG_ 448 RFCfgReq "Change customer programmable items by RKE";
CM_ SG_ 448 PE_ENABLE "Passive entry feature enabled; [1] = True";
CM_ SG_ 448 KeyProgramSts "Key programming status";
CM_ BO_ 416 "Tx Rate: 20ms, Std Dev: 0.5ms";
CM_ SG_ 388 ValImmKey "Drivers request, immobilizer results";
CM_ SG_ 388 TeenKey "Teen key present; Present = [1]";
CM_ SG_ 388 IgnPos "Drivers request, ignition position";
CM_ SG_ 388 CustKeyInIgn "Driver's request, key-in-ignition";
CM_ SG_ 384 SysVolt "Engine system voltage";
CM_ SG_ 384 IntkAirTemp "Engine Intake Air Temperature";
CM_ SG_ 384 EngCoolTemp "Engine coolant temperature";
CM_ SG_ 384 CHRG_FAIL "Charging system Failure (battery indicator request)";
CM_ SG_ 384 AM_ECM_Prsnt "Aftermarket ECM present";
CM_ SG_ 384 AirPress_Outsd "Ambient air pressure (barometric pressure)";
CM_ SG_ 376 TxTemp_Excess "Excessive transmission temperature";
CM_ SG_ 376 TX_WARN "Transmission warning";
CM_ SG_ 376 TX_TEMP "Transmission fluid temperature";
CM_ SG_ 376 TX_FAULT "Transmission fault";
CM_ SG_ 368 SHFT_PROG "Driving program display code";
CM_ SG_ 368 SHFT_LOCK "Shiftlock state locked; false = [1]";
CM_ SG_ 368 R_SHFT_LOCK "Shiftlock for reverse; locked = [1]";
CM_ SG_ 368 PRNDL_DISP "PRNDL display request";
CM_ SG_ 368 PRNDL_Blink "Request gear shift display indicator blink";
CM_ SG_ 368 PRND_STAT "PRND Status";
CM_ SG_ 368 MC_TRNS_STAT "Message counter";
CM_ SG_ 368 EngStEnblRqTCM "Engine start enable request from the transmission";
CM_ SG_ 368 CRC_TRNS_STAT "CRC-checksum byte 1 to 7 according to SAE J1850";
CM_ SG_ 368 APCM_Rq "Auto position correction mode request";
CM_ SG_ 368 x170_byte0_lower2 "added by New Eagle to ensure checksums arent messed up if FCA adds a new signal";
CM_ SG_ 368 x170_byte3_upper2 "added by New Eagle to ensure checksums arent messed up if FCA adds a new signal";
CM_ SG_ 368 x170_byte3_middle4 "added by New Eagle to ensure checksums arent messed up if FCA adds a new signal";
CM_ SG_ 368 x170_byte4 "added by New Eagle to ensure checksums arent messed up if FCA adds a new signal";
CM_ SG_ 368 x170_byte5 "added by New Eagle to ensure checksums arent messed up if FCA adds a new signal";
CM_ SG_ 368 x170_byte6_lower1 "added by New Eagle to ensure checksums arent messed up if FCA adds a new signal";
CM_ BO_ 362 "Tx Rate: 20ms, Std Dev: 0.5ms";
CM_ BO_ 352 "Tx Rate: 20ms, Std Dev: 0.5ms";
CM_ SG_ 344 WhlRPM_RR "Wheel rpm rear right";
CM_ SG_ 344 WhlRPM_RL "Wheel rpm rear left";
CM_ SG_ 344 WhlRPM_FR "Wheel rpm front right";
CM_ SG_ 344 WhlRPM_FL "Wheel rpm front left";
CM_ SG_ 344 WhlDir_RR_Stat "Direction of rotation of rear right wheel";
CM_ SG_ 344 WhlDir_RL_Stat "Direction of rotation of rear left wheel";
CM_ SG_ 344 WhlDir_FR_Stat "Direction of rotation of front right wheel";
CM_ SG_ 344 WhlDir_FL_Stat "Direction of rotation of front left wheel";
CM_ SG_ 332 VehYawRate_Raw "Vehicle yaw rate unfiltered/unadjusted (+ means left)";
CM_ SG_ 332 VehYawRate_Offset "Offset of vehicle yaw rate unfiltered/unadjusted (+ means left)";
CM_ SG_ 332 VehAccel_Y_Offset "Offset of vehicle lateral acceleration (+ means left)";
CM_ SG_ 332 VehAccel_Y "Vehicle lateral acceleration (+ means left, specific to center of gravity, offset-corrected )";
CM_ SG_ 332 VehAccel_X_Offset "Offset of vehicle longitudinal acceleration (+ means forward)";
CM_ SG_ 332 VehAccel_X "Vehicle longitudinal acceleration (+ means forward)";
CM_ SG_ 332 MC_VEH_DYN_STAT "Message counter";
CM_ SG_ 331 PTS_Brk_Rq_RspSts "Brake request response status by ESC for park stop & release";
CM_ SG_ 331 MC_ESP_A3 "Message counter";
CM_ SG_ 331 HSA_BrkPrss "Hill start assist brake pressure";
CM_ SG_ 331 CRC_ESP_A3 "CRC-checksum byte 1 to 7 according to SAE J1850";
CM_ SG_ 331 BrkPrss_TMC "Master cylinder pressure";
CM_ SG_ 331 x14b_BrkVacuumBoosterGaugePress "Vacuum Sensor reading from brake module. will be negative because its relative to baro. Obviously we disconnected it from the booster but the sensor still reads a value nonetheless. Not sure if the sensor is gauge or absolute pressure (would need to test at altitude) but I would guess gauge.

26dec = 98.4 kPa on MAP Sensor @ 98.4 Baro (0 kPa vacuum)
110dec = 32kPa on MAP Sensor @ 98.4 Baro   (66.4kPa vacuum)
137dec when vacuum pump runs (unknown actual pressure) so its not a signed number
";
CM_ SG_ 324 OUTPUT_SPEED "Output Shaft Speed";
CM_ SG_ 324 Gr_Target "Target Gear";
CM_ SG_ 324 Gr "Current Gear";
CM_ SG_ 324 EngSt_Enbl_Rq_TCM "Enable engine start request";
CM_ SG_ 320 SPCR_AS_Off_Rq "Assistance system off request";
CM_ SG_ 320 RollTestMd_Actv "Roller test bench mode active";
CM_ SG_ 320 REF_VEH_SPEED "Reference vehicle actual speed";
CM_ SG_ 320 MC_Brk_Stat "Message counter";
CM_ SG_ 320 FullBrk_Actv "Maximum (hard) braking (ALS controls all wheels)";
CM_ SG_ 320 ESP_Sys_Stat "ESP system state";
CM_ SG_ 320 EmgBrk_Actv "Emergency braking";
CM_ SG_ 320 DTR_CC_Engaged "ACC is engaged; True = [1]";
CM_ SG_ 320 DTR_CC_Enabled "ACC is enabled; True = [1]";
CM_ SG_ 320 CRC_Brk_Stat "CRC-checksum byte 1 to 7 according to SAE J1850";
CM_ SG_ 320 BrkPdl_Stat "Brake pedal state";
CM_ SG_ 320 BrkPdl_Flt "Brake Pedal Fault is active, 1=Faulted";
CM_ SG_ 320 BrkIntrvntn_Enbl "Brake intervention enabled";
CM_ SG_ 320 BrkIntrvntn_Actv_ESP "Brake intervention by ESP active";
CM_ SG_ 320 BrkIntrvntn_Actv_AS "Brake intervention by assistance system active";
CM_ SG_ 320 Brk_Thermdl "Brake thermal over target";
CM_ SG_ 320 Brk_Stat "Brake state";
CM_ SG_ 320 ABS_BrkEvt "Any ABS brake event";
CM_ SG_ 320 x140_byte1_middle2 "added by New Eagle to ensure checksums arent messed up if FCA adds a new signal";
CM_ SG_ 320 x140_byte2_lower7 "added by New Eagle to ensure checksums arent messed up if FCA adds a new signal";
CM_ SG_ 320 x140_byte3_lower1 "added by New Eagle to ensure checksums arent messed up if FCA adds a new signal";
CM_ SG_ 320 x140_byte3_middle4 "added by New Eagle to ensure checksums arent messed up if FCA adds a new signal";
CM_ SG_ 320 x140_byte4_middle4 "added by New Eagle to ensure checksums arent messed up if FCA adds a new signal";
CM_ SG_ 320 x140_byte6_lower4 "added by New Eagle to ensure checksums arent messed up if FCA adds a new signal";
CM_ SG_ 308 V_MAX_TM "Max. or cruise control set speed";
CM_ SG_ 308 Rel_Thrt_ENG "Relative throttle value";
CM_ SG_ 308 Rel_Pdl_ENG "Relative pedal value";
CM_ SG_ 308 MAP_ENG "Intake manifold pressure, extended rangeEDR ONLY - Intake manifold pressure";
CM_ SG_ 308 CRUISE_ON "Cruise control system 'on'";
CM_ SG_ 308 CRUISE_EGD "Cruise system is controlling speed";
CM_ SG_ 308 BARO_ENG "Ambient air pressure (barometric pressure)";
CM_ SG_ 300 PS_SysType "Power steering system type; EHPS = [0]: EPS = [1]";
CM_ SG_ 300 EPS_Warn_Disp_Rq "Electric power steering warning display request";
CM_ SG_ 300 EPS_MODE_STAT "EPS mode personalization status";
CM_ SG_ 300 EPS_Curr "Electric power steering current";
CM_ SG_ 300 EPS_AsstStat "Electric Power Steering Assistance Status";
CM_ SG_ 300 EngineFanRequestActivation "Engine fan activation request for cooling; True = [1]";
CM_ SG_ 292 WhlPlsCnt_RR "Wheel pulse counter rear right (xx per rotation)";
CM_ SG_ 292 WhlPlsCnt_RL "doesn't work on grand cherokee";
CM_ SG_ 292 WhlPlsCnt_FR "doesn't work on grand cherokee";
CM_ SG_ 292 WhlPlsCnt_FL "doesn't work on grand cherokee";
CM_ SG_ 290 NMOTS "Target idle speed";
CM_ SG_ 290 GrMax_Rq_ECM "Target gear upper limit (ECM requested limit)";
CM_ SG_ 288 RPMOverRev "RPM Overrev condition has occurred";
CM_ SG_ 288 MC_ECM_A2 "Message counter";
CM_ SG_ 288 LV12PwrFreeRq "Level 1 or 2 power free request - engine controller has depowered the throttle body";
CM_ SG_ 288 ESS_RqShftPark "ESS Request shift to Park.  1 = True, 0 = False";
CM_ SG_ 288 EngTrq_Enbl_Rq_ESC "Allow ESC torque request";
CM_ SG_ 288 EngTrq_Enbl_Rq_AS "Allow LCM torque requests";
CM_ SG_ 288 ECM_LHOM "Engine in limp home mode";
CM_ SG_ 288 CRUISE_OVERRIDE "Driver is over-riding cruise set speed";
CM_ SG_ 288 CRC_ECM_A2 "CRC-checksum byte 1 to 6 according to SAE J1850";
CM_ SG_ 288 AccelPdlPosnSens_Flt "Accelerator pedal position sensor fault";
CM_ SG_ 288 AccelPdlPosn "Throttle Pedal Position (Calculated)";
CM_ SG_ 284 VehSpSts "Vehicle is stopped status signal";
CM_ SG_ 284 VEH_SPEED "Vehicle speed";
CM_ SG_ 284 MC_VEH_SPEED "Message counter";
CM_ SG_ 284 CRC_VEH_SPEED "CRC-checksum byte 1 to 7 according to SAE J1850";
CM_ SG_ 284 BrkTrq_D "Brake torque requested by driver";
CM_ SG_ 284 BrkTrq "Actual brake torque";
CM_ SG_ 284 x11C_byte0_middle3 "added by New Eagle to ensure checksums arent messed up if FCA adds a new signal";
CM_ SG_ 284 x11C_byte2_upper4 "added by New Eagle to ensure checksums arent messed up if FCA adds a new signal";
CM_ SG_ 284 x11C_byte6_lower4 "added by New Eagle to ensure checksums arent messed up if FCA adds a new signal";
CM_ SG_ 280 StartRelayBCMCmd "Engine restart request for StopStart function";
CM_ SG_ 280 MC_ECM_ENG_TRQ "Message counter";
CM_ SG_ 280 CRC_ECM_ENG_TRQ "CRC-checksum byte 1 to 7 according to SAE J1850";
CM_ SG_ 280 ANL_LFT "Starter motor running (Cranking)";
CM_ SG_ 274 TeenKeyPrsnt "Teen key present; Present = [1]";
CM_ SG_ 274 StTyp "Type of start being requested";
CM_ SG_ 274 StartRelayBCMSts "CBC starter relay status; [1] = ON";
CM_ SG_ 274 StartRelayBCMFault "CBC starter relay fault detected";
CM_ SG_ 274 RemStActv "Ignition run active for remote start (0=not active, 1=active)";
CM_ SG_ 274 KeyInIgn "Key in ignition status";
CM_ SG_ 274 CmdIgnStat "Commanded ignition switch status";
CM_ BO_ 273 "Tx Rate: NaNms, Std Dev: NaNms";
CM_ BO_ 272 "Tx Rate: NaNms, Std Dev: NaNms";
CM_ SG_ 268 PrefillActive "Brake prefill is active - True = [1]";
CM_ SG_ 268 MC_ENG_RQ_ESC "Message counter";
CM_ SG_ 268 EngTrqMin_Rq_ESC "Engine torque request minimum";
CM_ SG_ 268 EngTrqMax_Rq_ESC "Engine torque request maximum";
CM_ SG_ 268 EngTrq_Rq_ESC "Engine torque request";
CM_ SG_ 268 DAS_RqActv "DAS request active";
CM_ SG_ 268 DAS_Enbl_Rq "Enable DAS request; True = [1]";
CM_ SG_ 268 CRC_ENG_RQ_ESC "CRC-checksum byte 1 to 7 according to SAE J1850";
CM_ SG_ 268 Brk_Jrk_Rsp "Brake jerk response; True = [1]";
CM_ SG_ 268 ASRActive "Traction control is active";
CM_ SG_ 268 x10C_byte2_lower5 "added by New Eagle to ensure checksums arent messed up if FCA adds a new signal";
CM_ SG_ 268 x10C_byte2_upper2 "added by New Eagle to ensure checksums arent messed up if FCA adds a new signal";
CM_ SG_ 268 x10C_byte3 "added by New Eagle to ensure checksums arent messed up if FCA adds a new signal";
CM_ SG_ 268 x10C_byte4 "looks like booster vacuum pressure";
CM_ SG_ 268 x10C_byte5_upper7 "added by New Eagle to ensure checksums arent messed up if FCA adds a new signal";
CM_ SG_ 264 MC_ECM_A1 "Message counter";
CM_ SG_ 264 EngRPM "Engine revolutions per minute";
CM_ SG_ 264 ECM_IMMO_STAT_CANC "ECM immobilizer status";
CM_ SG_ 264 CRC_ECM_A1 "CRC-checksum byte 1 to 7 according to SAE J1850";
CM_ SG_ 258 VLRW "Delta steering wheel angle";
CM_ SG_ 258 MC_STW_Angle_STAT "Message counter";
CM_ SG_ 258 LRWS_ST "Steering wheel angle sensor status";
CM_ SG_ 258 LRW_RHP "Steering wheel angle remainder high precision";
CM_ SG_ 258 LRW_PLRTY "Steering angle polarity (0=ISO 8855 Polarity and CCW = Positive)";
CM_ SG_ 258 LRW "Steering wheel angle";
CM_ SG_ 258 CRC_STW_Angle_STAT "CRC-checksum byte 1 to 7 according to SAE J1850";
CM_ SG_ 257 RAD_FAN1_STAT "Low speed or single radiator fan requested duty cycle";
CM_ SG_ 257 OBD_GnrlDenCond_Stat "General denominator conditions are met [1].";
CM_ SG_ 257 InpICC_Fail "Inputs to the Ign Cycle Cntr are in a Pend or MIL cond.";
CM_ SG_ 257 Inp_GD_Fail "Inputs to the general denominator are in a pend or MIL fault.";
CM_ SG_ 257 IgnCntrTrue "Ignition cycle counter is true [1]";
CM_ SG_ 257 EngLoad_OBD "Load value for OBD (ISO 15031-5.4 PID 4)";
CM_ SG_ 257 ENGINE_RESET "ECM Reset Notification";
CM_ SG_ 257 ECM_SKIM_STAT "ECM Skim Status";
CM_ SG_ 257 CARB_Temp "CARB warmup criteria is true [1]";
CM_ SG_ 257 CARB_PERM "CARB permanent fault code drive cycle";
CM_ SG_ 257 AccelPdlPosn_OBD "Pedal value for OBD (ISO 15031-5.4 PID 49)";
CM_ BO_ 256 "Tx Rate: NaNms, Std Dev: NaNms";
CM_ BO_ 181 "Tx Rate: 20ms, Std Dev: 0.5ms";
CM_ SG_ 181 xB5_byte3 "looks like an LSB of something";
CM_ SG_ 168 MC_0A8h "Message counter   0A8h";
CM_ SG_ 168 DrvrIntndedAxleTorq "Driver Intended Axle Torque";
CM_ SG_ 168 CRC_0A8h "CRC-Checksum Byte 1 - 7 according to SAE J1850";
CM_ BO_ 55 "Tx Rate: 10ms, Std Dev: 0.2ms";
CM_ BO_ 2147484177 "injected by new eagle to get analog voltages into can logs";
CM_ SG_ 1083 WakeupRsn_EBCM "Wakeup reason EBCM";
CM_ SG_ 1083 WakeupCnt_EBCM "Counter for module wakeup states during network sleep";
CM_ SG_ 1083 Nw_Id_EBCM "Network identification no.";
CM_ SG_ 1083 NM_Ud_Srv_EBCM "Network management userdata service no.";
CM_ SG_ 1083 NM_Ud_Launch_EBCM "Network management userdata launch type";
CM_ SG_ 1083 NM_Successor_EBCM "Network management logical successor";
CM_ SG_ 1083 NM_Sleep_Ind_EBCM "Network management sleep indication; True = [1]";
CM_ SG_ 1083 NM_Sleep_Ack_EBCM "Network management sleep acknowledge; True = [1]";
CM_ SG_ 1083 NM_Mode_EBCM "Network management mode";
CM_ SG_ 1083 Awake_NwSt_EBCM "Stay awake for network startup; True = [1]";
CM_ SG_ 1083 Awake_Diag_Actv_EBCM "Stay awake for diagnostics active; True = [1]";
BA_DEF_ SG_  "GenSigTimeout_CBC" INT 0 65535;
BA_DEF_ SG_  "GenSigTimeout_EPS" INT 0 65535;
BA_DEF_ SG_  "GenSigTimeout_ESM" INT 0 65535;
BA_DEF_ SG_  "GenSigTimeout_ETM" INT 0 65535;
BA_DEF_ SG_  "GenSigTimeout_HaLF" INT 0 65535;
BA_DEF_ SG_  "GenSigTimeout_IC" INT 0 65535;
BA_DEF_ SG_  "GenSigTimeout_OCM" INT 0 65535;
BA_DEF_ SG_  "GenSigTimeout_ORC" INT 0 65535;
BA_DEF_ SG_  "GenSigTimeout_PTS" INT 0 65535;
BA_DEF_ SG_  "GenSigTimeout_RF_HUB" INT 0 65535;
BA_DEF_ SG_  "GenSigTimeout_SCCM" INT 0 65535;
BA_DEF_ BO_  "GenMsgStartValue" STRING ;
BA_DEF_ SG_  "GenSigSNA" STRING ;
BA_DEF_ SG_  "RID" STRING ;
BA_DEF_ SG_  "FlexKomIsMotorola" ENUM  "nein","ja";
BA_DEF_ SG_  "FlexKomSigLaenge" INT 0 64;
BA_DEF_ SG_  "FlexKomSigStartPos" INT 0 63;
BA_DEF_ SG_  "FlexKomComment" STRING ;
BA_DEF_ SG_  "FlexKomSigName" STRING ;
BA_DEF_ SG_  "FlexKomSID" INT 0 2147483647;
BA_DEF_ SG_  "GenSigStartValue" HEX 0 -1;
BA_DEF_ SG_  "FlexKomSigStartValue" STRING ;
BA_DEF_ SG_  "GenSigCycleTime" INT 0 65535;
BA_DEF_ SG_  "GenSigSendType" ENUM  "cyclicX","spontanX","cyclicIfActiveX","spontanWithDelay","cyclicAndSpontanX","cyclicAndSpontanWithDelay","spontanWithRepitition","cyclicIfActiveAndSpontanWD","cyclicIfActiveFast","cyclicWithRepeatOnDemand","none";
BA_DEF_ BO_  "GenMsgNrOfRepetitions" INT 0 65535;
BA_DEF_ BO_  "GenMsgDelayTime" INT 0 65535;
BA_DEF_ BO_  "GenMsgStartDelayTime" INT 0 65535;
BA_DEF_ BO_  "GenMsgCycleTime" INT 0 65535;
BA_DEF_ BO_  "GenMsgSendType" ENUM  "cyclicX","spontanX","cyclicIfActiveX","spontanWithDelay","cyclicAndSpontanX","cyclicAndSpontanWithDelay","spontanWithRepitition","cyclicIfActiveAndSpontanWD","cyclicIfActiveFast","cyclicWithRepeatOnDemand","none";
BA_DEF_ BO_  "DiagResponse" ENUM  "nein","ja";
BA_DEF_ BO_  "DiagRequest" ENUM  "nein","ja";
BA_DEF_ BO_  "DiagState" ENUM  "nein","ja";
BA_DEF_ BO_  "App-Botschaft" ENUM  "nein","ja";
BA_DEF_ BO_  "NWM-Botschaft" ENUM  "nein","ja";
BA_DEF_DEF_  "GenSigTimeout_CBC" 0;
BA_DEF_DEF_  "GenSigTimeout_EPS" 0;
BA_DEF_DEF_  "GenSigTimeout_ESM" 0;
BA_DEF_DEF_  "GenSigTimeout_ETM" 0;
BA_DEF_DEF_  "GenSigTimeout_HaLF" 0;
BA_DEF_DEF_  "GenSigTimeout_IC" 0;
BA_DEF_DEF_  "GenSigTimeout_OCM" 0;
BA_DEF_DEF_  "GenSigTimeout_ORC" 0;
BA_DEF_DEF_  "GenSigTimeout_PTS" 0;
BA_DEF_DEF_  "GenSigTimeout_RF_HUB" 0;
BA_DEF_DEF_  "GenSigTimeout_SCCM" 0;
BA_DEF_DEF_  "GenMsgStartValue" "";
BA_DEF_DEF_  "GenSigSNA" "";
BA_DEF_DEF_  "RID" "";
BA_DEF_DEF_  "FlexKomIsMotorola" "nein";
BA_DEF_DEF_  "FlexKomSigLaenge" 0;
BA_DEF_DEF_  "FlexKomSigStartPos" 0;
BA_DEF_DEF_  "FlexKomComment" "";
BA_DEF_DEF_  "FlexKomSigName" "";
BA_DEF_DEF_  "FlexKomSID" 0;
BA_DEF_DEF_  "GenSigStartValue" 0;
BA_DEF_DEF_  "FlexKomSigStartValue" "";
BA_DEF_DEF_  "GenSigCycleTime" 0;
BA_DEF_DEF_  "GenSigSendType" "cyclicX";
BA_DEF_DEF_  "GenMsgNrOfRepetitions" 0;
BA_DEF_DEF_  "GenMsgDelayTime" 0;
BA_DEF_DEF_  "GenMsgStartDelayTime" 0;
BA_DEF_DEF_  "GenMsgCycleTime" 0;
BA_DEF_DEF_  "GenMsgSendType" "cyclicX";
BA_DEF_DEF_  "DiagResponse" "nein";
BA_DEF_DEF_  "DiagRequest" "nein";
BA_DEF_DEF_  "DiagState" "nein";
BA_DEF_DEF_  "App-Botschaft" "nein";
BA_DEF_DEF_  "NWM-Botschaft" "nein";
BA_ "GenMsgStartValue" BO_ 464 "48E70F0F00070000h";
BA_ "GenMsgNrOfRepetitions" BO_ 464 2;
BA_ "GenMsgDelayTime" BO_ 464 20;
BA_ "GenMsgCycleTime" BO_ 464 1000;
BA_ "GenMsgSendType" BO_ 464 5;
BA_ "GenSigSNA" SG_ 464 SRS_IndLmp_Rq "3h";
BA_ "FlexKomIsMotorola" SG_ 464 SRS_IndLmp_Rq 1;
BA_ "FlexKomComment" SG_ 464 SRS_IndLmp_Rq "SRS indication lamp request";
BA_ "FlexKomSigName" SG_ 464 SRS_IndLmp_Rq "SRS_IndLmp_Rq";
BA_ "FlexKomSigLaenge" SG_ 464 SRS_IndLmp_Rq 2;
BA_ "FlexKomSigStartPos" SG_ 464 SRS_IndLmp_Rq 3;
BA_ "FlexKomSID" SG_ 464 SRS_IndLmp_Rq 329;
BA_ "GenSigTimeout_ETM" SG_ 464 SRS_IndLmp_Rq 10500;
BA_ "GenSigTimeout_IC" SG_ 464 SRS_IndLmp_Rq 10500;
BA_ "GenSigTimeout_CBC" SG_ 464 SRS_IndLmp_Rq 5500;
BA_ "GenSigStartValue" SG_ 464 SRS_IndLmp_Rq 2;
BA_ "FlexKomSigStartValue" SG_ 464 SRS_IndLmp_Rq "02h";
BA_ "GenSigCycleTime" SG_ 464 SRS_IndLmp_Rq 1000;
BA_ "GenSigSendType" SG_ 464 SRS_IndLmp_Rq 5;
BA_ "GenSigSNA" SG_ 464 PSG_SEATBELT "3h";
BA_ "FlexKomIsMotorola" SG_ 464 PSG_SEATBELT 1;
BA_ "FlexKomComment" SG_ 464 PSG_SEATBELT "Passengers seat belt status";
BA_ "FlexKomSigName" SG_ 464 PSG_SEATBELT "PSG_SEATBELT";
BA_ "FlexKomSigLaenge" SG_ 464 PSG_SEATBELT 2;
BA_ "FlexKomSigStartPos" SG_ 464 PSG_SEATBELT 19;
BA_ "FlexKomSID" SG_ 464 PSG_SEATBELT 331;
BA_ "GenSigTimeout_ETM" SG_ 464 PSG_SEATBELT 10500;
BA_ "GenSigTimeout_IC" SG_ 464 PSG_SEATBELT 10500;
BA_ "GenSigTimeout_CBC" SG_ 464 PSG_SEATBELT 10500;
BA_ "GenSigStartValue" SG_ 464 PSG_SEATBELT 3;
BA_ "FlexKomSigStartValue" SG_ 464 PSG_SEATBELT "03h";
BA_ "GenSigCycleTime" SG_ 464 PSG_SEATBELT 1000;
BA_ "GenSigSendType" SG_ 464 PSG_SEATBELT 5;
BA_ "GenSigSNA" SG_ 464 PSG_ODS_STAT "3h";
BA_ "FlexKomIsMotorola" SG_ 464 PSG_ODS_STAT 1;
BA_ "FlexKomComment" SG_ 464 PSG_ODS_STAT "Passenger Occupant Detection Sensor Status";
BA_ "FlexKomSigName" SG_ 464 PSG_ODS_STAT "PSG_ODS_STAT";
BA_ "FlexKomSigLaenge" SG_ 464 PSG_ODS_STAT 2;
BA_ "FlexKomSigStartPos" SG_ 464 PSG_ODS_STAT 27;
BA_ "FlexKomSID" SG_ 464 PSG_ODS_STAT 426;
BA_ "GenSigTimeout_ETM" SG_ 464 PSG_ODS_STAT 10500;
BA_ "GenSigTimeout_IC" SG_ 464 PSG_ODS_STAT 10500;
BA_ "GenSigTimeout_CBC" SG_ 464 PSG_ODS_STAT 10500;
BA_ "GenSigStartValue" SG_ 464 PSG_ODS_STAT 3;
BA_ "FlexKomSigStartValue" SG_ 464 PSG_ODS_STAT "03h";
BA_ "GenSigCycleTime" SG_ 464 PSG_ODS_STAT 1000;
BA_ "GenSigSendType" SG_ 464 PSG_ODS_STAT 5;
BA_ "GenSigSNA" SG_ 464 ORC_A1_Tog "0h";
BA_ "FlexKomIsMotorola" SG_ 464 ORC_A1_Tog 1;
BA_ "FlexKomComment" SG_ 464 ORC_A1_Tog "ORC_A1 toggle bit";
BA_ "FlexKomSigName" SG_ 464 ORC_A1_Tog "ORC_A1_Tog";
BA_ "FlexKomSigLaenge" SG_ 464 ORC_A1_Tog 1;
BA_ "FlexKomSigStartPos" SG_ 464 ORC_A1_Tog 1;
BA_ "FlexKomSID" SG_ 464 ORC_A1_Tog 1902;
BA_ "FlexKomSigStartValue" SG_ 464 ORC_A1_Tog "00h";
BA_ "GenSigCycleTime" SG_ 464 ORC_A1_Tog 1000;
BA_ "GenSigSendType" SG_ 464 ORC_A1_Tog 5;
BA_ "GenSigSNA" SG_ 464 ORC_A1_Par "0h";
BA_ "FlexKomIsMotorola" SG_ 464 ORC_A1_Par 1;
BA_ "FlexKomComment" SG_ 464 ORC_A1_Par "ORC_A1 even parity bit";
BA_ "FlexKomSigName" SG_ 464 ORC_A1_Par "ORC_A1_Par";
BA_ "FlexKomSigLaenge" SG_ 464 ORC_A1_Par 1;
BA_ "FlexKomSigStartPos" SG_ 464 ORC_A1_Par 7;
BA_ "FlexKomSID" SG_ 464 ORC_A1_Par 1903;
BA_ "FlexKomSigStartValue" SG_ 464 ORC_A1_Par "00h";
BA_ "GenSigCycleTime" SG_ 464 ORC_A1_Par 1000;
BA_ "GenSigSendType" SG_ 464 ORC_A1_Par 5;
BA_ "GenSigSNA" SG_ 464 DrvSbltUnFltr "7h";
BA_ "FlexKomIsMotorola" SG_ 464 DrvSbltUnFltr 1;
BA_ "FlexKomComment" SG_ 464 DrvSbltUnFltr "Drivers seat belt fault status - unfiltered";
BA_ "FlexKomSigName" SG_ 464 DrvSbltUnFltr "DrvSbltUnFltr";
BA_ "FlexKomSigLaenge" SG_ 464 DrvSbltUnFltr 3;
BA_ "FlexKomSigStartPos" SG_ 464 DrvSbltUnFltr 15;
BA_ "FlexKomSID" SG_ 464 DrvSbltUnFltr 1814;
BA_ "GenSigStartValue" SG_ 464 DrvSbltUnFltr 7;
BA_ "FlexKomSigStartValue" SG_ 464 DrvSbltUnFltr "07h";
BA_ "GenSigCycleTime" SG_ 464 DrvSbltUnFltr 1000;
BA_ "GenSigSendType" SG_ 464 DrvSbltUnFltr 5;
BA_ "GenSigSNA" SG_ 464 DRV_SEATBELT "3h";
BA_ "FlexKomIsMotorola" SG_ 464 DRV_SEATBELT 1;
BA_ "FlexKomComment" SG_ 464 DRV_SEATBELT "Drivers seat belt status";
BA_ "FlexKomSigName" SG_ 464 DRV_SEATBELT "DRV_SEATBELT";
BA_ "FlexKomSigLaenge" SG_ 464 DRV_SEATBELT 2;
BA_ "FlexKomSigStartPos" SG_ 464 DRV_SEATBELT 17;
BA_ "FlexKomSID" SG_ 464 DRV_SEATBELT 330;
BA_ "GenSigTimeout_ETM" SG_ 464 DRV_SEATBELT 10500;
BA_ "GenSigTimeout_PTS" SG_ 464 DRV_SEATBELT 10500;
BA_ "GenSigTimeout_IC" SG_ 464 DRV_SEATBELT 10500;
BA_ "GenSigTimeout_CBC" SG_ 464 DRV_SEATBELT 10500;
BA_ "GenSigStartValue" SG_ 464 DRV_SEATBELT 3;
BA_ "FlexKomSigStartValue" SG_ 464 DRV_SEATBELT "03h";
BA_ "GenSigCycleTime" SG_ 464 DRV_SEATBELT 1000;
BA_ "GenSigSendType" SG_ 464 DRV_SEATBELT 5;
BA_ "GenMsgStartDelayTime" BO_ 456 30;
BA_ "GenMsgStartValue" BO_ 456 "00000000h";
BA_ "GenMsgNrOfRepetitions" BO_ 456 2;
BA_ "GenMsgDelayTime" BO_ 456 20;
BA_ "GenMsgCycleTime" BO_ 456 500;
BA_ "GenMsgSendType" BO_ 456 5;
BA_ "GenSigSNA" SG_ 456 VTA_STAT "7h";
BA_ "FlexKomIsMotorola" SG_ 456 VTA_STAT 1;
BA_ "FlexKomComment" SG_ 456 VTA_STAT "Vehicle theft alarm packet";
BA_ "FlexKomSigName" SG_ 456 VTA_STAT "VTA_PKT";
BA_ "FlexKomSigLaenge" SG_ 456 VTA_STAT 32;
BA_ "FlexKomSigStartPos" SG_ 456 VTA_STAT 7;
BA_ "FlexKomSID" SG_ 456 VTA_STAT 1207;
BA_ "FlexKomSigStartValue" SG_ 456 VTA_STAT "00000000h";
BA_ "GenSigCycleTime" SG_ 456 VTA_STAT 500;
BA_ "GenSigSendType" SG_ 456 VTA_STAT 5;
BA_ "GenMsgStartValue" BO_ 448 "000000000000h";
BA_ "GenMsgNrOfRepetitions" BO_ 448 2;
BA_ "GenMsgDelayTime" BO_ 448 20;
BA_ "GenMsgCycleTime" BO_ 448 200;
BA_ "GenMsgSendType" BO_ 448 5;
BA_ "GenSigSNA" SG_ 448 RFReq "7h";
BA_ "FlexKomIsMotorola" SG_ 448 RFReq 1;
BA_ "FlexKomComment" SG_ 448 RFReq "RFHUB_A2_Pkt";
BA_ "FlexKomSigName" SG_ 448 RFReq "RFHUB_A2_Pkt";
BA_ "FlexKomSigLaenge" SG_ 448 RFReq 48;
BA_ "FlexKomSigStartPos" SG_ 448 RFReq 7;
BA_ "FlexKomSID" SG_ 448 RFReq 1037;
BA_ "FlexKomSigStartValue" SG_ 448 RFReq "000000000000h";
BA_ "GenSigCycleTime" SG_ 448 RFReq 200;
BA_ "GenSigSendType" SG_ 448 RFReq 5;
BA_ "GenSigTimeout_IC" SG_ 448 RFFuncReq 2100;
BA_ "GenSigSNA" SG_ 448 RFFuncReq "1Fh";
BA_ "FlexKomIsMotorola" SG_ 448 RFFuncReq 1;
BA_ "FlexKomComment" SG_ 448 RFFuncReq "RFHUB_A2_Pkt";
BA_ "FlexKomSigName" SG_ 448 RFFuncReq "RFHUB_A2_Pkt";
BA_ "FlexKomSigLaenge" SG_ 448 RFFuncReq 48;
BA_ "FlexKomSigStartPos" SG_ 448 RFFuncReq 7;
BA_ "FlexKomSID" SG_ 448 RFFuncReq 1037;
BA_ "FlexKomSigStartValue" SG_ 448 RFFuncReq "000000000000h";
BA_ "GenSigCycleTime" SG_ 448 RFFuncReq 200;
BA_ "GenSigSendType" SG_ 448 RFFuncReq 5;
BA_ "GenSigSNA" SG_ 448 RFFobNum "Fh";
BA_ "FlexKomIsMotorola" SG_ 448 RFFobNum 1;
BA_ "FlexKomComment" SG_ 448 RFFobNum "RFHUB_A2_Pkt";
BA_ "FlexKomSigName" SG_ 448 RFFobNum "RFHUB_A2_Pkt";
BA_ "FlexKomSigLaenge" SG_ 448 RFFobNum 48;
BA_ "FlexKomSigStartPos" SG_ 448 RFFobNum 7;
BA_ "FlexKomSID" SG_ 448 RFFobNum 1037;
BA_ "FlexKomSigStartValue" SG_ 448 RFFobNum "000000000000h";
BA_ "GenSigCycleTime" SG_ 448 RFFobNum 200;
BA_ "GenSigSendType" SG_ 448 RFFobNum 5;
BA_ "GenSigSNA" SG_ 448 RFCfgReq "7h";
BA_ "FlexKomIsMotorola" SG_ 448 RFCfgReq 1;
BA_ "FlexKomComment" SG_ 448 RFCfgReq "RFHUB_A2_Pkt";
BA_ "FlexKomSigName" SG_ 448 RFCfgReq "RFHUB_A2_Pkt";
BA_ "FlexKomSigLaenge" SG_ 448 RFCfgReq 48;
BA_ "FlexKomSigStartPos" SG_ 448 RFCfgReq 7;
BA_ "FlexKomSID" SG_ 448 RFCfgReq 1037;
BA_ "FlexKomSigStartValue" SG_ 448 RFCfgReq "000000000000h";
BA_ "GenSigCycleTime" SG_ 448 RFCfgReq 200;
BA_ "GenSigSendType" SG_ 448 RFCfgReq 5;
BA_ "GenSigSNA" SG_ 448 PE_ENABLE "0h";
BA_ "FlexKomIsMotorola" SG_ 448 PE_ENABLE 1;
BA_ "FlexKomComment" SG_ 448 PE_ENABLE "RFHUB_A2_Pkt";
BA_ "FlexKomSigName" SG_ 448 PE_ENABLE "RFHUB_A2_Pkt";
BA_ "FlexKomSigLaenge" SG_ 448 PE_ENABLE 48;
BA_ "FlexKomSigStartPos" SG_ 448 PE_ENABLE 7;
BA_ "FlexKomSID" SG_ 448 PE_ENABLE 1037;
BA_ "GenSigTimeout_IC" SG_ 448 PE_ENABLE 2100;
BA_ "FlexKomSigStartValue" SG_ 448 PE_ENABLE "000000000000h";
BA_ "GenSigCycleTime" SG_ 448 PE_ENABLE 200;
BA_ "GenSigSendType" SG_ 448 PE_ENABLE 5;
BA_ "GenSigSNA" SG_ 448 KeyProgramSts "Fh";
BA_ "FlexKomIsMotorola" SG_ 448 KeyProgramSts 1;
BA_ "FlexKomComment" SG_ 448 KeyProgramSts "RFHUB_A2_Pkt";
BA_ "FlexKomSigName" SG_ 448 KeyProgramSts "RFHUB_A2_Pkt";
BA_ "FlexKomSigLaenge" SG_ 448 KeyProgramSts 48;
BA_ "FlexKomSigStartPos" SG_ 448 KeyProgramSts 7;
BA_ "FlexKomSID" SG_ 448 KeyProgramSts 1037;
BA_ "GenSigTimeout_IC" SG_ 448 KeyProgramSts 2100;
BA_ "FlexKomSigStartValue" SG_ 448 KeyProgramSts "000000000000h";
BA_ "GenSigCycleTime" SG_ 448 KeyProgramSts 200;
BA_ "GenSigSendType" SG_ 448 KeyProgramSts 5;
BA_ "GenMsgStartValue" BO_ 388 "1C000000h";
BA_ "GenMsgNrOfRepetitions" BO_ 388 2;
BA_ "GenMsgDelayTime" BO_ 388 20;
BA_ "GenMsgCycleTime" BO_ 388 100;
BA_ "GenMsgSendType" BO_ 388 5;
BA_ "GenSigSNA" SG_ 388 ValImmKey "3h";
BA_ "FlexKomIsMotorola" SG_ 388 ValImmKey 1;
BA_ "FlexKomComment" SG_ 388 ValImmKey "Customer ignition packet";
BA_ "FlexKomSigName" SG_ 388 ValImmKey "CustIgnPkt";
BA_ "FlexKomSigLaenge" SG_ 388 ValImmKey 32;
BA_ "FlexKomSigStartPos" SG_ 388 ValImmKey 7;
BA_ "FlexKomSID" SG_ 388 ValImmKey 1034;
BA_ "FlexKomSigStartValue" SG_ 388 ValImmKey "1C000000h";
BA_ "GenSigCycleTime" SG_ 388 ValImmKey 100;
BA_ "GenSigSendType" SG_ 388 ValImmKey 5;
BA_ "GenSigSNA" SG_ 388 TeenKey "0h";
BA_ "FlexKomIsMotorola" SG_ 388 TeenKey 1;
BA_ "FlexKomComment" SG_ 388 TeenKey "Customer ignition packet";
BA_ "FlexKomSigName" SG_ 388 TeenKey "CustIgnPkt";
BA_ "FlexKomSigLaenge" SG_ 388 TeenKey 32;
BA_ "FlexKomSigStartPos" SG_ 388 TeenKey 7;
BA_ "FlexKomSID" SG_ 388 TeenKey 1034;
BA_ "FlexKomSigStartValue" SG_ 388 TeenKey "1C000000h";
BA_ "GenSigCycleTime" SG_ 388 TeenKey 100;
BA_ "GenSigSendType" SG_ 388 TeenKey 5;
BA_ "GenSigSNA" SG_ 388 IgnPos "7h";
BA_ "FlexKomIsMotorola" SG_ 388 IgnPos 1;
BA_ "FlexKomComment" SG_ 388 IgnPos "Customer ignition packet";
BA_ "FlexKomSigName" SG_ 388 IgnPos "CustIgnPkt";
BA_ "FlexKomSigLaenge" SG_ 388 IgnPos 32;
BA_ "FlexKomSigStartPos" SG_ 388 IgnPos 7;
BA_ "FlexKomSID" SG_ 388 IgnPos 1034;
BA_ "GenSigTimeout_CBC" SG_ 388 IgnPos 1050;
BA_ "GenSigStartValue" SG_ 388 IgnPos 7;
BA_ "FlexKomSigStartValue" SG_ 388 IgnPos "1C000000h";
BA_ "GenSigCycleTime" SG_ 388 IgnPos 100;
BA_ "GenSigSendType" SG_ 388 IgnPos 5;
BA_ "GenSigSNA" SG_ 388 CustKeyInIgn "3h";
BA_ "FlexKomIsMotorola" SG_ 388 CustKeyInIgn 1;
BA_ "FlexKomComment" SG_ 388 CustKeyInIgn "Customer ignition packet";
BA_ "FlexKomSigName" SG_ 388 CustKeyInIgn "CustIgnPkt";
BA_ "FlexKomSigLaenge" SG_ 388 CustKeyInIgn 32;
BA_ "FlexKomSigStartPos" SG_ 388 CustKeyInIgn 7;
BA_ "FlexKomSID" SG_ 388 CustKeyInIgn 1034;
BA_ "FlexKomSigStartValue" SG_ 388 CustKeyInIgn "1C000000h";
BA_ "GenSigCycleTime" SG_ 388 CustKeyInIgn 100;
BA_ "GenSigSendType" SG_ 388 CustKeyInIgn 5;
BA_ "GenMsgStartValue" BO_ 384 "00FFFF000001FFFFh";
BA_ "GenMsgNrOfRepetitions" BO_ 384 2;
BA_ "GenMsgDelayTime" BO_ 384 20;
BA_ "GenMsgCycleTime" BO_ 384 100;
BA_ "GenSigSNA" SG_ 384 SysVolt "FFh";
BA_ "FlexKomIsMotorola" SG_ 384 SysVolt 1;
BA_ "FlexKomComment" SG_ 384 SysVolt "Engine voltage packet";
BA_ "FlexKomSigName" SG_ 384 SysVolt "EngVoltPkt";
BA_ "FlexKomSigLaenge" SG_ 384 SysVolt 16;
BA_ "FlexKomSigStartPos" SG_ 384 SysVolt 31;
BA_ "FlexKomSID" SG_ 384 SysVolt 437;
BA_ "FlexKomSigStartValue" SG_ 384 SysVolt "0000h";
BA_ "GenSigCycleTime" SG_ 384 SysVolt 100;
BA_ "GenSigSNA" SG_ 384 IntkAirTemp "FFh";
BA_ "FlexKomIsMotorola" SG_ 384 IntkAirTemp 1;
BA_ "FlexKomComment" SG_ 384 IntkAirTemp "Engine Intake Air Temperature";
BA_ "FlexKomSigName" SG_ 384 IntkAirTemp "IntkAirTemp";
BA_ "FlexKomSigLaenge" SG_ 384 IntkAirTemp 8;
BA_ "FlexKomSigStartPos" SG_ 384 IntkAirTemp 7;
BA_ "FlexKomSID" SG_ 384 IntkAirTemp 441;
BA_ "GenSigTimeout_ETM" SG_ 384 IntkAirTemp 1050;
BA_ "GenSigTimeout_IC" SG_ 384 IntkAirTemp 1050;
BA_ "FlexKomSigStartValue" SG_ 384 IntkAirTemp "00h";
BA_ "GenSigCycleTime" SG_ 384 IntkAirTemp 100;
BA_ "GenSigSNA" SG_ 384 EngCoolTemp "FFh";
BA_ "FlexKomIsMotorola" SG_ 384 EngCoolTemp 1;
BA_ "FlexKomComment" SG_ 384 EngCoolTemp "Engine coolant temperature";
BA_ "FlexKomSigName" SG_ 384 EngCoolTemp "EngCoolTemp";
BA_ "FlexKomSigLaenge" SG_ 384 EngCoolTemp 8;
BA_ "FlexKomSigStartPos" SG_ 384 EngCoolTemp 15;
BA_ "FlexKomSID" SG_ 384 EngCoolTemp 711;
BA_ "GenSigTimeout_IC" SG_ 384 EngCoolTemp 1050;
BA_ "GenSigTimeout_CBC" SG_ 384 EngCoolTemp 1050;
BA_ "GenSigStartValue" SG_ 384 EngCoolTemp 255;
BA_ "FlexKomSigStartValue" SG_ 384 EngCoolTemp "FFh";
BA_ "GenSigCycleTime" SG_ 384 EngCoolTemp 100;
BA_ "GenSigSNA" SG_ 384 CHRG_FAIL "1h";
BA_ "FlexKomIsMotorola" SG_ 384 CHRG_FAIL 1;
BA_ "FlexKomComment" SG_ 384 CHRG_FAIL "Charging system Failure (battery indicator request";
BA_ "FlexKomSigName" SG_ 384 CHRG_FAIL "CHRG_FAIL";
BA_ "FlexKomSigLaenge" SG_ 384 CHRG_FAIL 1;
BA_ "FlexKomSigStartPos" SG_ 384 CHRG_FAIL 41;
BA_ "FlexKomSID" SG_ 384 CHRG_FAIL 1085;
BA_ "GenSigTimeout_ORC" SG_ 384 CHRG_FAIL 350;
BA_ "GenSigTimeout_IC" SG_ 384 CHRG_FAIL 1050;
BA_ "FlexKomSigStartValue" SG_ 384 CHRG_FAIL "00h";
BA_ "GenSigCycleTime" SG_ 384 CHRG_FAIL 100;
BA_ "GenSigSNA" SG_ 384 AM_ECM_Prsnt "3h";
BA_ "FlexKomIsMotorola" SG_ 384 AM_ECM_Prsnt 1;
BA_ "FlexKomComment" SG_ 384 AM_ECM_Prsnt "Aftermarket ECM present";
BA_ "FlexKomSigName" SG_ 384 AM_ECM_Prsnt "AM_ECM_Prsnt";
BA_ "FlexKomSigLaenge" SG_ 384 AM_ECM_Prsnt 2;
BA_ "FlexKomSigStartPos" SG_ 384 AM_ECM_Prsnt 46;
BA_ "FlexKomSID" SG_ 384 AM_ECM_Prsnt 1941;
BA_ "GenSigTimeout_CBC" SG_ 384 AM_ECM_Prsnt 1050;
BA_ "FlexKomSigStartValue" SG_ 384 AM_ECM_Prsnt "00h";
BA_ "GenSigCycleTime" SG_ 384 AM_ECM_Prsnt 100;
BA_ "GenSigSNA" SG_ 384 AirPress_Outsd "FFh";
BA_ "FlexKomIsMotorola" SG_ 384 AirPress_Outsd 1;
BA_ "FlexKomComment" SG_ 384 AirPress_Outsd "Ambient air pressure (barometric pressure)";
BA_ "FlexKomSigName" SG_ 384 AirPress_Outsd "AirPress_Outsd";
BA_ "FlexKomSigLaenge" SG_ 384 AirPress_Outsd 8;
BA_ "FlexKomSigStartPos" SG_ 384 AirPress_Outsd 23;
BA_ "FlexKomSID" SG_ 384 AirPress_Outsd 1084;
BA_ "GenSigTimeout_ETM" SG_ 384 AirPress_Outsd 1050;
BA_ "GenSigTimeout_IC" SG_ 384 AirPress_Outsd 1050;
BA_ "GenSigTimeout_RF_HUB" SG_ 384 AirPress_Outsd 1050;
BA_ "GenSigStartValue" SG_ 384 AirPress_Outsd 255;
BA_ "FlexKomSigStartValue" SG_ 384 AirPress_Outsd "FFh";
BA_ "GenSigCycleTime" SG_ 384 AirPress_Outsd 100;
BA_ "GenMsgStartValue" BO_ 376 "F0FF80h";
BA_ "GenMsgNrOfRepetitions" BO_ 376 2;
BA_ "GenMsgDelayTime" BO_ 376 20;
BA_ "GenMsgCycleTime" BO_ 376 100;
BA_ "GenSigSNA" SG_ 376 TxTemp_Excess "0h";
BA_ "FlexKomIsMotorola" SG_ 376 TxTemp_Excess 1;
BA_ "FlexKomComment" SG_ 376 TxTemp_Excess "Excessive transmission temperature";
BA_ "FlexKomSigName" SG_ 376 TxTemp_Excess "TxTemp_Excess";
BA_ "FlexKomSigLaenge" SG_ 376 TxTemp_Excess 1;
BA_ "FlexKomSigStartPos" SG_ 376 TxTemp_Excess 3;
BA_ "FlexKomSID" SG_ 376 TxTemp_Excess 1144;
BA_ "GenSigTimeout_ETM" SG_ 376 TxTemp_Excess 1050;
BA_ "GenSigTimeout_IC" SG_ 376 TxTemp_Excess 1050;
BA_ "FlexKomSigStartValue" SG_ 376 TxTemp_Excess "00h";
BA_ "GenSigCycleTime" SG_ 376 TxTemp_Excess 100;
BA_ "GenSigSNA" SG_ 376 TX_WARN "Fh";
BA_ "FlexKomIsMotorola" SG_ 376 TX_WARN 1;
BA_ "FlexKomComment" SG_ 376 TX_WARN "Transmission warning";
BA_ "FlexKomSigName" SG_ 376 TX_WARN "TX_WARN";
BA_ "FlexKomSigLaenge" SG_ 376 TX_WARN 4;
BA_ "FlexKomSigStartPos" SG_ 376 TX_WARN 19;
BA_ "FlexKomSID" SG_ 376 TX_WARN 1365;
BA_ "GenSigTimeout_IC" SG_ 376 TX_WARN 1050;
BA_ "FlexKomSigStartValue" SG_ 376 TX_WARN "00h";
BA_ "GenSigCycleTime" SG_ 376 TX_WARN 100;
BA_ "GenSigSNA" SG_ 376 TX_TEMP "FFh";
BA_ "FlexKomIsMotorola" SG_ 376 TX_TEMP 1;
BA_ "FlexKomComment" SG_ 376 TX_TEMP "Transmission fluid temperature";
BA_ "FlexKomSigName" SG_ 376 TX_TEMP "TX_TEMP";
BA_ "FlexKomSigLaenge" SG_ 376 TX_TEMP 8;
BA_ "FlexKomSigStartPos" SG_ 376 TX_TEMP 15;
BA_ "FlexKomSID" SG_ 376 TX_TEMP 1146;
BA_ "GenSigTimeout_ETM" SG_ 376 TX_TEMP 1050;
BA_ "GenSigTimeout_IC" SG_ 376 TX_TEMP 1050;
BA_ "GenSigTimeout_CBC" SG_ 376 TX_TEMP 1050;
BA_ "GenSigStartValue" SG_ 376 TX_TEMP 255;
BA_ "FlexKomSigStartValue" SG_ 376 TX_TEMP "FFh";
BA_ "GenSigCycleTime" SG_ 376 TX_TEMP 100;
BA_ "GenSigSNA" SG_ 376 TX_FAULT "3h";
BA_ "FlexKomIsMotorola" SG_ 376 TX_FAULT 1;
BA_ "FlexKomComment" SG_ 376 TX_FAULT "Transmission fault";
BA_ "FlexKomSigName" SG_ 376 TX_FAULT "TX_FAULT";
BA_ "FlexKomSigLaenge" SG_ 376 TX_FAULT 2;
BA_ "FlexKomSigStartPos" SG_ 376 TX_FAULT 21;
BA_ "FlexKomSID" SG_ 376 TX_FAULT 1364;
BA_ "GenSigTimeout_ESM" SG_ 376 TX_FAULT 1050;
BA_ "FlexKomSigStartValue" SG_ 376 TX_FAULT "00h";
BA_ "GenSigCycleTime" SG_ 376 TX_FAULT 100;
BA_ "GenMsgStartValue" BO_ 368 "1CFFFF00000000FFh";
BA_ "GenMsgNrOfRepetitions" BO_ 368 2;
BA_ "GenMsgDelayTime" BO_ 368 20;
BA_ "GenMsgCycleTime" BO_ 368 20;
BA_ "GenSigSNA" SG_ 368 SHFT_PROG "FFh";
BA_ "FlexKomIsMotorola" SG_ 368 SHFT_PROG 1;
BA_ "FlexKomComment" SG_ 368 SHFT_PROG "TRNS_STAT message packet";
BA_ "FlexKomSigName" SG_ 368 SHFT_PROG "TRNS_STAT_PKT";
BA_ "FlexKomSigLaenge" SG_ 368 SHFT_PROG 64;
BA_ "FlexKomSigStartPos" SG_ 368 SHFT_PROG 7;
BA_ "FlexKomSID" SG_ 368 SHFT_PROG 1366;
BA_ "GenSigTimeout_IC" SG_ 368 SHFT_PROG 210;
BA_ "GenSigTimeout_CBC" SG_ 368 SHFT_PROG 210;
BA_ "GenSigStartValue" SG_ 368 SHFT_PROG 255;
BA_ "FlexKomSigStartValue" SG_ 368 SHFT_PROG "1CFFFF00000000FFh";
BA_ "GenSigCycleTime" SG_ 368 SHFT_PROG 20;
BA_ "GenSigSNA" SG_ 368 SHFT_LOCK "0h";
BA_ "FlexKomIsMotorola" SG_ 368 SHFT_LOCK 1;
BA_ "FlexKomComment" SG_ 368 SHFT_LOCK "TRNS_STAT message packet";
BA_ "FlexKomSigName" SG_ 368 SHFT_LOCK "TRNS_STAT_PKT";
BA_ "FlexKomSigLaenge" SG_ 368 SHFT_LOCK 64;
BA_ "FlexKomSigStartPos" SG_ 368 SHFT_LOCK 7;
BA_ "FlexKomSID" SG_ 368 SHFT_LOCK 1366;
BA_ "GenSigTimeout_ESM" SG_ 368 SHFT_LOCK 210;
BA_ "FlexKomSigStartValue" SG_ 368 SHFT_LOCK "1CFFFF00000000FFh";
BA_ "GenSigCycleTime" SG_ 368 SHFT_LOCK 20;
BA_ "GenSigSNA" SG_ 368 R_SHFT_LOCK "0h";
BA_ "FlexKomIsMotorola" SG_ 368 R_SHFT_LOCK 1;
BA_ "FlexKomComment" SG_ 368 R_SHFT_LOCK "TRNS_STAT message packet";
BA_ "FlexKomSigName" SG_ 368 R_SHFT_LOCK "TRNS_STAT_PKT";
BA_ "FlexKomSigLaenge" SG_ 368 R_SHFT_LOCK 64;
BA_ "FlexKomSigStartPos" SG_ 368 R_SHFT_LOCK 7;
BA_ "FlexKomSID" SG_ 368 R_SHFT_LOCK 1366;
BA_ "FlexKomSigStartValue" SG_ 368 R_SHFT_LOCK "1CFFFF00000000FFh";
BA_ "GenSigCycleTime" SG_ 368 R_SHFT_LOCK 20;
BA_ "GenSigSNA" SG_ 368 PRNDL_DISP "FFh";
BA_ "FlexKomIsMotorola" SG_ 368 PRNDL_DISP 1;
BA_ "FlexKomComment" SG_ 368 PRNDL_DISP "TRNS_STAT message packet";
BA_ "FlexKomSigName" SG_ 368 PRNDL_DISP "TRNS_STAT_PKT";
BA_ "FlexKomSigLaenge" SG_ 368 PRNDL_DISP 64;
BA_ "FlexKomSigStartPos" SG_ 368 PRNDL_DISP 7;
BA_ "FlexKomSID" SG_ 368 PRNDL_DISP 1366;
BA_ "GenSigTimeout_ESM" SG_ 368 PRNDL_DISP 210;
BA_ "GenSigTimeout_IC" SG_ 368 PRNDL_DISP 210;
BA_ "GenSigTimeout_CBC" SG_ 368 PRNDL_DISP 210;
BA_ "GenSigStartValue" SG_ 368 PRNDL_DISP 255;
BA_ "FlexKomSigStartValue" SG_ 368 PRNDL_DISP "1CFFFF00000000FFh";
BA_ "GenSigCycleTime" SG_ 368 PRNDL_DISP 20;
BA_ "GenSigSNA" SG_ 368 PRNDL_Blink "0h";
BA_ "FlexKomIsMotorola" SG_ 368 PRNDL_Blink 1;
BA_ "FlexKomComment" SG_ 368 PRNDL_Blink "TRNS_STAT message packet";
BA_ "FlexKomSigName" SG_ 368 PRNDL_Blink "TRNS_STAT_PKT";
BA_ "FlexKomSigLaenge" SG_ 368 PRNDL_Blink 64;
BA_ "FlexKomSigStartPos" SG_ 368 PRNDL_Blink 7;
BA_ "FlexKomSID" SG_ 368 PRNDL_Blink 1366;
BA_ "GenSigTimeout_ESM" SG_ 368 PRNDL_Blink 210;
BA_ "GenSigTimeout_IC" SG_ 368 PRNDL_Blink 210;
BA_ "FlexKomSigStartValue" SG_ 368 PRNDL_Blink "1CFFFF00000000FFh";
BA_ "GenSigCycleTime" SG_ 368 PRNDL_Blink 20;
BA_ "GenSigSNA" SG_ 368 PRND_STAT "7h";
BA_ "FlexKomIsMotorola" SG_ 368 PRND_STAT 1;
BA_ "FlexKomComment" SG_ 368 PRND_STAT "TRNS_STAT message packet";
BA_ "FlexKomSigName" SG_ 368 PRND_STAT "TRNS_STAT_PKT";
BA_ "FlexKomSigLaenge" SG_ 368 PRND_STAT 64;
BA_ "FlexKomSigStartPos" SG_ 368 PRND_STAT 7;
BA_ "FlexKomSID" SG_ 368 PRND_STAT 1366;
BA_ "GenSigTimeout_ORC" SG_ 368 PRND_STAT 70;
BA_ "GenSigTimeout_ESM" SG_ 368 PRND_STAT 210;
BA_ "GenSigTimeout_PTS" SG_ 368 PRND_STAT 210;
BA_ "GenSigTimeout_IC" SG_ 368 PRND_STAT 210;
BA_ "GenSigTimeout_CBC" SG_ 368 PRND_STAT 510;
BA_ "GenSigTimeout_RF_HUB" SG_ 368 PRND_STAT 210;
BA_ "GenSigStartValue" SG_ 368 PRND_STAT 7;
BA_ "FlexKomSigStartValue" SG_ 368 PRND_STAT "1CFFFF00000000FFh";
BA_ "GenSigCycleTime" SG_ 368 PRND_STAT 20;
BA_ "GenSigSNA" SG_ 368 MC_TRNS_STAT "0h";
BA_ "FlexKomIsMotorola" SG_ 368 MC_TRNS_STAT 1;
BA_ "FlexKomComment" SG_ 368 MC_TRNS_STAT "TRNS_STAT message packet";
BA_ "FlexKomSigName" SG_ 368 MC_TRNS_STAT "TRNS_STAT_PKT";
BA_ "FlexKomSigLaenge" SG_ 368 MC_TRNS_STAT 64;
BA_ "FlexKomSigStartPos" SG_ 368 MC_TRNS_STAT 7;
BA_ "FlexKomSID" SG_ 368 MC_TRNS_STAT 1366;
BA_ "GenSigTimeout_ORC" SG_ 368 MC_TRNS_STAT 70;
BA_ "GenSigTimeout_ESM" SG_ 368 MC_TRNS_STAT 210;
BA_ "FlexKomSigStartValue" SG_ 368 MC_TRNS_STAT "1CFFFF00000000FFh";
BA_ "GenSigCycleTime" SG_ 368 MC_TRNS_STAT 20;
BA_ "GenSigSNA" SG_ 368 EngStEnblRqTCM "0h";
BA_ "FlexKomIsMotorola" SG_ 368 EngStEnblRqTCM 1;
BA_ "FlexKomComment" SG_ 368 EngStEnblRqTCM "TRNS_STAT message packet";
BA_ "FlexKomSigName" SG_ 368 EngStEnblRqTCM "TRNS_STAT_PKT";
BA_ "FlexKomSigLaenge" SG_ 368 EngStEnblRqTCM 64;
BA_ "FlexKomSigStartPos" SG_ 368 EngStEnblRqTCM 7;
BA_ "FlexKomSID" SG_ 368 EngStEnblRqTCM 1366;
BA_ "FlexKomSigStartValue" SG_ 368 EngStEnblRqTCM "1CFFFF00000000FFh";
BA_ "GenSigCycleTime" SG_ 368 EngStEnblRqTCM 20;
BA_ "GenSigSNA" SG_ 368 CRC_TRNS_STAT "FFh";
BA_ "FlexKomIsMotorola" SG_ 368 CRC_TRNS_STAT 1;
BA_ "FlexKomComment" SG_ 368 CRC_TRNS_STAT "TRNS_STAT message packet";
BA_ "FlexKomSigName" SG_ 368 CRC_TRNS_STAT "TRNS_STAT_PKT";
BA_ "FlexKomSigLaenge" SG_ 368 CRC_TRNS_STAT 64;
BA_ "FlexKomSigStartPos" SG_ 368 CRC_TRNS_STAT 7;
BA_ "FlexKomSID" SG_ 368 CRC_TRNS_STAT 1366;
BA_ "GenSigTimeout_ORC" SG_ 368 CRC_TRNS_STAT 70;
BA_ "GenSigTimeout_ESM" SG_ 368 CRC_TRNS_STAT 210;
BA_ "GenSigStartValue" SG_ 368 CRC_TRNS_STAT 255;
BA_ "FlexKomSigStartValue" SG_ 368 CRC_TRNS_STAT "1CFFFF00000000FFh";
BA_ "GenSigCycleTime" SG_ 368 CRC_TRNS_STAT 20;
BA_ "GenSigSNA" SG_ 368 APCM_Rq "3h";
BA_ "FlexKomIsMotorola" SG_ 368 APCM_Rq 1;
BA_ "FlexKomComment" SG_ 368 APCM_Rq "TRNS_STAT message packet";
BA_ "FlexKomSigName" SG_ 368 APCM_Rq "TRNS_STAT_PKT";
BA_ "FlexKomSigLaenge" SG_ 368 APCM_Rq 64;
BA_ "FlexKomSigStartPos" SG_ 368 APCM_Rq 7;
BA_ "FlexKomSID" SG_ 368 APCM_Rq 1366;
BA_ "GenSigTimeout_ESM" SG_ 368 APCM_Rq 210;
BA_ "GenSigTimeout_IC" SG_ 368 APCM_Rq 210;
BA_ "FlexKomSigStartValue" SG_ 368 APCM_Rq "1CFFFF00000000FFh";
BA_ "GenSigCycleTime" SG_ 368 APCM_Rq 20;
BA_ "GenMsgStartValue" BO_ 344 "FFFFFFFFFFFFFFFFh";
BA_ "GenMsgNrOfRepetitions" BO_ 344 2;
BA_ "GenMsgDelayTime" BO_ 344 20;
BA_ "GenMsgCycleTime" BO_ 344 20;
BA_ "GenSigSNA" SG_ 344 WhlRPM_RR "3FFFh";
BA_ "FlexKomIsMotorola" SG_ 344 WhlRPM_RR 1;
BA_ "FlexKomComment" SG_ 344 WhlRPM_RR "ESP Wheel Speed";
BA_ "FlexKomSigName" SG_ 344 WhlRPM_RR "WHEEL_SPEED";
BA_ "FlexKomSigLaenge" SG_ 344 WhlRPM_RR 64;
BA_ "FlexKomSigStartPos" SG_ 344 WhlRPM_RR 7;
BA_ "FlexKomSID" SG_ 344 WhlRPM_RR 64;
BA_ "GenSigTimeout_ORC" SG_ 344 WhlRPM_RR 70;
BA_ "GenSigTimeout_CBC" SG_ 344 WhlRPM_RR 110;
BA_ "GenSigStartValue" SG_ 344 WhlRPM_RR 16383;
BA_ "FlexKomSigStartValue" SG_ 344 WhlRPM_RR "FFFFFFFFFFFFFFFFh";
BA_ "GenSigCycleTime" SG_ 344 WhlRPM_RR 20;
BA_ "GenSigSNA" SG_ 344 WhlRPM_RL "3FFFh";
BA_ "FlexKomIsMotorola" SG_ 344 WhlRPM_RL 1;
BA_ "FlexKomComment" SG_ 344 WhlRPM_RL "ESP Wheel Speed";
BA_ "FlexKomSigName" SG_ 344 WhlRPM_RL "WHEEL_SPEED";
BA_ "FlexKomSigLaenge" SG_ 344 WhlRPM_RL 64;
BA_ "FlexKomSigStartPos" SG_ 344 WhlRPM_RL 7;
BA_ "FlexKomSID" SG_ 344 WhlRPM_RL 64;
BA_ "GenSigTimeout_ORC" SG_ 344 WhlRPM_RL 70;
BA_ "GenSigTimeout_CBC" SG_ 344 WhlRPM_RL 110;
BA_ "GenSigStartValue" SG_ 344 WhlRPM_RL 16383;
BA_ "FlexKomSigStartValue" SG_ 344 WhlRPM_RL "FFFFFFFFFFFFFFFFh";
BA_ "GenSigCycleTime" SG_ 344 WhlRPM_RL 20;
BA_ "GenSigSNA" SG_ 344 WhlRPM_FR "3FFFh";
BA_ "FlexKomIsMotorola" SG_ 344 WhlRPM_FR 1;
BA_ "FlexKomComment" SG_ 344 WhlRPM_FR "ESP Wheel Speed";
BA_ "FlexKomSigName" SG_ 344 WhlRPM_FR "WHEEL_SPEED";
BA_ "FlexKomSigLaenge" SG_ 344 WhlRPM_FR 64;
BA_ "FlexKomSigStartPos" SG_ 344 WhlRPM_FR 7;
BA_ "FlexKomSID" SG_ 344 WhlRPM_FR 64;
BA_ "GenSigTimeout_ORC" SG_ 344 WhlRPM_FR 70;
BA_ "GenSigStartValue" SG_ 344 WhlRPM_FR 16383;
BA_ "FlexKomSigStartValue" SG_ 344 WhlRPM_FR "FFFFFFFFFFFFFFFFh";
BA_ "GenSigCycleTime" SG_ 344 WhlRPM_FR 20;
BA_ "GenSigSNA" SG_ 344 WhlRPM_FL "3FFFh";
BA_ "FlexKomIsMotorola" SG_ 344 WhlRPM_FL 1;
BA_ "FlexKomComment" SG_ 344 WhlRPM_FL "ESP Wheel Speed";
BA_ "FlexKomSigName" SG_ 344 WhlRPM_FL "WHEEL_SPEED";
BA_ "FlexKomSigLaenge" SG_ 344 WhlRPM_FL 64;
BA_ "FlexKomSigStartPos" SG_ 344 WhlRPM_FL 7;
BA_ "FlexKomSID" SG_ 344 WhlRPM_FL 64;
BA_ "GenSigTimeout_ORC" SG_ 344 WhlRPM_FL 70;
BA_ "GenSigStartValue" SG_ 344 WhlRPM_FL 16383;
BA_ "FlexKomSigStartValue" SG_ 344 WhlRPM_FL "FFFFFFFFFFFFFFFFh";
BA_ "GenSigCycleTime" SG_ 344 WhlRPM_FL 20;
BA_ "GenSigSNA" SG_ 344 WhlDir_RR_Stat "3h";
BA_ "FlexKomIsMotorola" SG_ 344 WhlDir_RR_Stat 1;
BA_ "FlexKomComment" SG_ 344 WhlDir_RR_Stat "ESP Wheel Speed";
BA_ "FlexKomSigName" SG_ 344 WhlDir_RR_Stat "WHEEL_SPEED";
BA_ "FlexKomSigLaenge" SG_ 344 WhlDir_RR_Stat 64;
BA_ "FlexKomSigStartPos" SG_ 344 WhlDir_RR_Stat 7;
BA_ "FlexKomSID" SG_ 344 WhlDir_RR_Stat 64;
BA_ "GenSigTimeout_ORC" SG_ 344 WhlDir_RR_Stat 70;
BA_ "GenSigStartValue" SG_ 344 WhlDir_RR_Stat 3;
BA_ "FlexKomSigStartValue" SG_ 344 WhlDir_RR_Stat "FFFFFFFFFFFFFFFFh";
BA_ "GenSigCycleTime" SG_ 344 WhlDir_RR_Stat 20;
BA_ "GenSigSNA" SG_ 344 WhlDir_RL_Stat "3h";
BA_ "FlexKomIsMotorola" SG_ 344 WhlDir_RL_Stat 1;
BA_ "FlexKomComment" SG_ 344 WhlDir_RL_Stat "ESP Wheel Speed";
BA_ "FlexKomSigName" SG_ 344 WhlDir_RL_Stat "WHEEL_SPEED";
BA_ "FlexKomSigLaenge" SG_ 344 WhlDir_RL_Stat 64;
BA_ "FlexKomSigStartPos" SG_ 344 WhlDir_RL_Stat 7;
BA_ "FlexKomSID" SG_ 344 WhlDir_RL_Stat 64;
BA_ "GenSigTimeout_ORC" SG_ 344 WhlDir_RL_Stat 70;
BA_ "GenSigStartValue" SG_ 344 WhlDir_RL_Stat 3;
BA_ "FlexKomSigStartValue" SG_ 344 WhlDir_RL_Stat "FFFFFFFFFFFFFFFFh";
BA_ "GenSigCycleTime" SG_ 344 WhlDir_RL_Stat 20;
BA_ "GenSigSNA" SG_ 344 WhlDir_FR_Stat "3h";
BA_ "FlexKomIsMotorola" SG_ 344 WhlDir_FR_Stat 1;
BA_ "FlexKomComment" SG_ 344 WhlDir_FR_Stat "ESP Wheel Speed";
BA_ "FlexKomSigName" SG_ 344 WhlDir_FR_Stat "WHEEL_SPEED";
BA_ "FlexKomSigLaenge" SG_ 344 WhlDir_FR_Stat 64;
BA_ "FlexKomSigStartPos" SG_ 344 WhlDir_FR_Stat 7;
BA_ "FlexKomSID" SG_ 344 WhlDir_FR_Stat 64;
BA_ "GenSigTimeout_ORC" SG_ 344 WhlDir_FR_Stat 70;
BA_ "GenSigStartValue" SG_ 344 WhlDir_FR_Stat 3;
BA_ "FlexKomSigStartValue" SG_ 344 WhlDir_FR_Stat "FFFFFFFFFFFFFFFFh";
BA_ "GenSigCycleTime" SG_ 344 WhlDir_FR_Stat 20;
BA_ "GenSigSNA" SG_ 344 WhlDir_FL_Stat "3h";
BA_ "FlexKomIsMotorola" SG_ 344 WhlDir_FL_Stat 1;
BA_ "FlexKomComment" SG_ 344 WhlDir_FL_Stat "ESP Wheel Speed";
BA_ "FlexKomSigName" SG_ 344 WhlDir_FL_Stat "WHEEL_SPEED";
BA_ "FlexKomSigLaenge" SG_ 344 WhlDir_FL_Stat 64;
BA_ "FlexKomSigStartPos" SG_ 344 WhlDir_FL_Stat 7;
BA_ "FlexKomSID" SG_ 344 WhlDir_FL_Stat 64;
BA_ "GenSigTimeout_ORC" SG_ 344 WhlDir_FL_Stat 70;
BA_ "GenSigStartValue" SG_ 344 WhlDir_FL_Stat 3;
BA_ "FlexKomSigStartValue" SG_ 344 WhlDir_FL_Stat "FFFFFFFFFFFFFFFFh";
BA_ "GenSigCycleTime" SG_ 344 WhlDir_FL_Stat 20;
BA_ "GenMsgStartValue" BO_ 332 "FFFFFFFFFFFF00FFh";
BA_ "GenMsgNrOfRepetitions" BO_ 332 2;
BA_ "GenMsgDelayTime" BO_ 332 20;
BA_ "GenMsgCycleTime" BO_ 332 20;
BA_ "GenSigSNA" SG_ 332 VehYawRate_Raw "FFFFh";
BA_ "FlexKomIsMotorola" SG_ 332 VehYawRate_Raw 1;
BA_ "FlexKomComment" SG_ 332 VehYawRate_Raw "Vehicle yaw rate unfiltered/unadjusted (+ means le";
BA_ "FlexKomSigName" SG_ 332 VehYawRate_Raw "VehYawRate_Raw";
BA_ "FlexKomSigLaenge" SG_ 332 VehYawRate_Raw 16;
BA_ "FlexKomSigStartPos" SG_ 332 VehYawRate_Raw 7;
BA_ "FlexKomSID" SG_ 332 VehYawRate_Raw 1262;
BA_ "GenSigTimeout_ORC" SG_ 332 VehYawRate_Raw 70;
BA_ "GenSigTimeout_CBC" SG_ 332 VehYawRate_Raw 210;
BA_ "GenSigStartValue" SG_ 332 VehYawRate_Raw 65535;
BA_ "FlexKomSigStartValue" SG_ 332 VehYawRate_Raw "FFFFh";
BA_ "GenSigCycleTime" SG_ 332 VehYawRate_Raw 20;
BA_ "GenSigSNA" SG_ 332 VehYawRate_Offset "FFh";
BA_ "FlexKomIsMotorola" SG_ 332 VehYawRate_Offset 1;
BA_ "FlexKomComment" SG_ 332 VehYawRate_Offset "Offset of vehicle yaw rate unfiltered/unadjusted (";
BA_ "FlexKomSigName" SG_ 332 VehYawRate_Offset "VehYawRate_Offset";
BA_ "FlexKomSigLaenge" SG_ 332 VehYawRate_Offset 8;
BA_ "FlexKomSigStartPos" SG_ 332 VehYawRate_Offset 23;
BA_ "FlexKomSID" SG_ 332 VehYawRate_Offset 1263;
BA_ "GenSigTimeout_ETM" SG_ 332 VehYawRate_Offset 210;
BA_ "GenSigTimeout_ORC" SG_ 332 VehYawRate_Offset 70;
BA_ "GenSigTimeout_CBC" SG_ 332 VehYawRate_Offset 210;
BA_ "GenSigStartValue" SG_ 332 VehYawRate_Offset 255;
BA_ "FlexKomSigStartValue" SG_ 332 VehYawRate_Offset "FFh";
BA_ "GenSigCycleTime" SG_ 332 VehYawRate_Offset 20;
BA_ "GenSigSNA" SG_ 332 VehAccel_Y_Offset "FFh";
BA_ "FlexKomIsMotorola" SG_ 332 VehAccel_Y_Offset 1;
BA_ "FlexKomComment" SG_ 332 VehAccel_Y_Offset "Offset of vehicle lateral acceleration (+ means le";
BA_ "FlexKomSigName" SG_ 332 VehAccel_Y_Offset "VehAccel_Y_Offset";
BA_ "FlexKomSigLaenge" SG_ 332 VehAccel_Y_Offset 8;
BA_ "FlexKomSigStartPos" SG_ 332 VehAccel_Y_Offset 63;
BA_ "FlexKomSID" SG_ 332 VehAccel_Y_Offset 1268;
BA_ "GenSigTimeout_ETM" SG_ 332 VehAccel_Y_Offset 210;
BA_ "GenSigTimeout_ORC" SG_ 332 VehAccel_Y_Offset 70;
BA_ "GenSigStartValue" SG_ 332 VehAccel_Y_Offset 255;
BA_ "FlexKomSigStartValue" SG_ 332 VehAccel_Y_Offset "FFh";
BA_ "GenSigCycleTime" SG_ 332 VehAccel_Y_Offset 20;
BA_ "GenSigSNA" SG_ 332 VehAccel_Y "FFh";
BA_ "FlexKomIsMotorola" SG_ 332 VehAccel_Y 1;
BA_ "FlexKomComment" SG_ 332 VehAccel_Y "Vehicle lateral acceleration (+ means left, specif";
BA_ "FlexKomSigName" SG_ 332 VehAccel_Y "VehAccel_Y";
BA_ "FlexKomSigLaenge" SG_ 332 VehAccel_Y 8;
BA_ "FlexKomSigStartPos" SG_ 332 VehAccel_Y 47;
BA_ "FlexKomSID" SG_ 332 VehAccel_Y 1266;
BA_ "GenSigTimeout_ORC" SG_ 332 VehAccel_Y 70;
BA_ "GenSigTimeout_IC" SG_ 332 VehAccel_Y 210;
BA_ "GenSigTimeout_CBC" SG_ 332 VehAccel_Y 210;
BA_ "GenSigStartValue" SG_ 332 VehAccel_Y 255;
BA_ "FlexKomSigStartValue" SG_ 332 VehAccel_Y "FFh";
BA_ "GenSigCycleTime" SG_ 332 VehAccel_Y 20;
BA_ "GenSigSNA" SG_ 332 VehAccel_X_Offset "FFh";
BA_ "FlexKomIsMotorola" SG_ 332 VehAccel_X_Offset 1;
BA_ "FlexKomComment" SG_ 332 VehAccel_X_Offset "Offset of vehicle longitudinal acceleration (+ mea";
BA_ "FlexKomSigName" SG_ 332 VehAccel_X_Offset "VehAccel_X_Offset";
BA_ "FlexKomSigLaenge" SG_ 332 VehAccel_X_Offset 8;
BA_ "FlexKomSigStartPos" SG_ 332 VehAccel_X_Offset 31;
BA_ "FlexKomSID" SG_ 332 VehAccel_X_Offset 1264;
BA_ "GenSigTimeout_ETM" SG_ 332 VehAccel_X_Offset 210;
BA_ "GenSigTimeout_ORC" SG_ 332 VehAccel_X_Offset 70;
BA_ "GenSigStartValue" SG_ 332 VehAccel_X_Offset 255;
BA_ "FlexKomSigStartValue" SG_ 332 VehAccel_X_Offset "FFh";
BA_ "GenSigCycleTime" SG_ 332 VehAccel_X_Offset 20;
BA_ "GenSigSNA" SG_ 332 VehAccel_X "FFh";
BA_ "FlexKomIsMotorola" SG_ 332 VehAccel_X 1;
BA_ "FlexKomComment" SG_ 332 VehAccel_X "Vehicle longitudinal acceleration (+ means forward";
BA_ "FlexKomSigName" SG_ 332 VehAccel_X "VehAccel_X";
BA_ "FlexKomSigLaenge" SG_ 332 VehAccel_X 8;
BA_ "FlexKomSigStartPos" SG_ 332 VehAccel_X 39;
BA_ "FlexKomSID" SG_ 332 VehAccel_X 1265;
BA_ "GenSigTimeout_ORC" SG_ 332 VehAccel_X 70;
BA_ "GenSigTimeout_IC" SG_ 332 VehAccel_X 210;
BA_ "GenSigTimeout_CBC" SG_ 332 VehAccel_X 210;
BA_ "GenSigStartValue" SG_ 332 VehAccel_X 255;
BA_ "FlexKomSigStartValue" SG_ 332 VehAccel_X "FFh";
BA_ "GenSigCycleTime" SG_ 332 VehAccel_X 20;
BA_ "GenSigSNA" SG_ 332 MC_VEH_DYN_STAT "0h";
BA_ "FlexKomIsMotorola" SG_ 332 MC_VEH_DYN_STAT 1;
BA_ "FlexKomComment" SG_ 332 MC_VEH_DYN_STAT "Message counter";
BA_ "FlexKomSigName" SG_ 332 MC_VEH_DYN_STAT "MC_VEH_DYN_STAT";
BA_ "FlexKomSigLaenge" SG_ 332 MC_VEH_DYN_STAT 4;
BA_ "FlexKomSigStartPos" SG_ 332 MC_VEH_DYN_STAT 55;
BA_ "FlexKomSID" SG_ 332 MC_VEH_DYN_STAT 1267;
BA_ "GenSigTimeout_ETM" SG_ 332 MC_VEH_DYN_STAT 210;
BA_ "GenSigTimeout_ORC" SG_ 332 MC_VEH_DYN_STAT 70;
BA_ "FlexKomSigStartValue" SG_ 332 MC_VEH_DYN_STAT "00h";
BA_ "GenSigCycleTime" SG_ 332 MC_VEH_DYN_STAT 20;
BA_ "GenMsgStartValue" BO_ 331 "0000FFFF00FF00FFh";
BA_ "GenMsgNrOfRepetitions" BO_ 331 2;
BA_ "GenMsgDelayTime" BO_ 331 20;
BA_ "GenMsgCycleTime" BO_ 331 20;
BA_ "GenSigSNA" SG_ 331 PTS_Brk_Rq_RspSts "3h";
BA_ "FlexKomIsMotorola" SG_ 331 PTS_Brk_Rq_RspSts 1;
BA_ "FlexKomComment" SG_ 331 PTS_Brk_Rq_RspSts "ESC data";
BA_ "FlexKomSigName" SG_ 331 PTS_Brk_Rq_RspSts "ESC_data";
BA_ "FlexKomSigLaenge" SG_ 331 PTS_Brk_Rq_RspSts 64;
BA_ "FlexKomSigStartPos" SG_ 331 PTS_Brk_Rq_RspSts 7;
BA_ "FlexKomSID" SG_ 331 PTS_Brk_Rq_RspSts 1416;
BA_ "GenSigTimeout_PTS" SG_ 331 PTS_Brk_Rq_RspSts 210;
BA_ "GenSigTimeout_IC" SG_ 331 PTS_Brk_Rq_RspSts 210;
BA_ "FlexKomSigStartValue" SG_ 331 PTS_Brk_Rq_RspSts "0000FFFF00FF00FFh";
BA_ "GenSigCycleTime" SG_ 331 PTS_Brk_Rq_RspSts 20;
BA_ "GenSigSNA" SG_ 331 MC_ESP_A3 "0h";
BA_ "FlexKomIsMotorola" SG_ 331 MC_ESP_A3 1;
BA_ "FlexKomComment" SG_ 331 MC_ESP_A3 "ESC data";
BA_ "FlexKomSigName" SG_ 331 MC_ESP_A3 "ESC_data";
BA_ "FlexKomSigLaenge" SG_ 331 MC_ESP_A3 64;
BA_ "FlexKomSigStartPos" SG_ 331 MC_ESP_A3 7;
BA_ "FlexKomSID" SG_ 331 MC_ESP_A3 1416;
BA_ "GenSigTimeout_ORC" SG_ 331 MC_ESP_A3 70;
BA_ "FlexKomSigStartValue" SG_ 331 MC_ESP_A3 "0000FFFF00FF00FFh";
BA_ "GenSigCycleTime" SG_ 331 MC_ESP_A3 20;
BA_ "GenSigSNA" SG_ 331 HSA_BrkPrss "3Fh";
BA_ "FlexKomIsMotorola" SG_ 331 HSA_BrkPrss 1;
BA_ "FlexKomComment" SG_ 331 HSA_BrkPrss "ESC data";
BA_ "FlexKomSigName" SG_ 331 HSA_BrkPrss "ESC_data";
BA_ "FlexKomSigLaenge" SG_ 331 HSA_BrkPrss 64;
BA_ "FlexKomSigStartPos" SG_ 331 HSA_BrkPrss 7;
BA_ "FlexKomSID" SG_ 331 HSA_BrkPrss 1416;
BA_ "GenSigTimeout_ETM" SG_ 331 HSA_BrkPrss 210;
BA_ "GenSigTimeout_ORC" SG_ 331 HSA_BrkPrss 70;
BA_ "FlexKomSigStartValue" SG_ 331 HSA_BrkPrss "0000FFFF00FF00FFh";
BA_ "GenSigCycleTime" SG_ 331 HSA_BrkPrss 20;
BA_ "GenSigSNA" SG_ 331 CRC_ESP_A3 "FFh";
BA_ "FlexKomIsMotorola" SG_ 331 CRC_ESP_A3 1;
BA_ "FlexKomComment" SG_ 331 CRC_ESP_A3 "ESC data";
BA_ "FlexKomSigName" SG_ 331 CRC_ESP_A3 "ESC_data";
BA_ "FlexKomSigLaenge" SG_ 331 CRC_ESP_A3 64;
BA_ "FlexKomSigStartPos" SG_ 331 CRC_ESP_A3 7;
BA_ "FlexKomSID" SG_ 331 CRC_ESP_A3 1416;
BA_ "GenSigTimeout_ORC" SG_ 331 CRC_ESP_A3 70;
BA_ "GenSigStartValue" SG_ 331 CRC_ESP_A3 255;
BA_ "FlexKomSigStartValue" SG_ 331 CRC_ESP_A3 "0000FFFF00FF00FFh";
BA_ "GenSigCycleTime" SG_ 331 CRC_ESP_A3 20;
BA_ "GenSigSNA" SG_ 331 BrkPrss_TMC "7FFh";
BA_ "FlexKomIsMotorola" SG_ 331 BrkPrss_TMC 1;
BA_ "FlexKomComment" SG_ 331 BrkPrss_TMC "ESC data";
BA_ "FlexKomSigName" SG_ 331 BrkPrss_TMC "ESC_data";
BA_ "FlexKomSigLaenge" SG_ 331 BrkPrss_TMC 64;
BA_ "FlexKomSigStartPos" SG_ 331 BrkPrss_TMC 7;
BA_ "FlexKomSID" SG_ 331 BrkPrss_TMC 1416;
BA_ "GenSigTimeout_ETM" SG_ 331 BrkPrss_TMC 210;
BA_ "GenSigTimeout_ORC" SG_ 331 BrkPrss_TMC 70;
BA_ "FlexKomSigStartValue" SG_ 331 BrkPrss_TMC "0000FFFF00FF00FFh";
BA_ "GenSigCycleTime" SG_ 331 BrkPrss_TMC 20;
BA_ "GenMsgStartValue" BO_ 324 "00FF00FFFFFFFF00h";
BA_ "GenMsgNrOfRepetitions" BO_ 324 2;
BA_ "GenMsgDelayTime" BO_ 324 20;
BA_ "GenMsgCycleTime" BO_ 324 20;
BA_ "GenSigCycleTime" SG_ 324 OUTPUT_SPEED 20;
BA_ "FlexKomSigStartValue" SG_ 324 OUTPUT_SPEED "FFFF000000h";
BA_ "GenSigStartValue" SG_ 324 OUTPUT_SPEED 65535;
BA_ "FlexKomSID" SG_ 324 OUTPUT_SPEED 1605;
BA_ "FlexKomSigStartPos" SG_ 324 OUTPUT_SPEED 31;
BA_ "FlexKomSigLaenge" SG_ 324 OUTPUT_SPEED 40;
BA_ "FlexKomSigName" SG_ 324 OUTPUT_SPEED "OutputSpdPkt";
BA_ "FlexKomComment" SG_ 324 OUTPUT_SPEED "Output shaft speed packet";
BA_ "FlexKomIsMotorola" SG_ 324 OUTPUT_SPEED 1;
BA_ "GenSigSNA" SG_ 324 OUTPUT_SPEED "FFFFh";
BA_ "GenSigSNA" SG_ 324 Gr_Target "Fh";
BA_ "FlexKomIsMotorola" SG_ 324 Gr_Target 1;
BA_ "FlexKomComment" SG_ 324 Gr_Target "Current Gear/Target Gear";
BA_ "FlexKomSigName" SG_ 324 Gr_Target "Gear_Pkt";
BA_ "FlexKomSigLaenge" SG_ 324 Gr_Target 16;
BA_ "FlexKomSigStartPos" SG_ 324 Gr_Target 15;
BA_ "FlexKomSID" SG_ 324 Gr_Target 1128;
BA_ "GenSigTimeout_CBC" SG_ 324 Gr_Target 210;
BA_ "GenSigStartValue" SG_ 324 Gr_Target 15;
BA_ "FlexKomSigStartValue" SG_ 324 Gr_Target "FF00h";
BA_ "GenSigCycleTime" SG_ 324 Gr_Target 20;
BA_ "GenSigTimeout_RF_HUB" SG_ 324 Gr 210;
BA_ "GenSigSNA" SG_ 324 Gr "Fh";
BA_ "FlexKomIsMotorola" SG_ 324 Gr 1;
BA_ "FlexKomComment" SG_ 324 Gr "Current Gear/Target Gear";
BA_ "FlexKomSigName" SG_ 324 Gr "Gear_Pkt";
BA_ "FlexKomSigLaenge" SG_ 324 Gr 16;
BA_ "FlexKomSigStartPos" SG_ 324 Gr 15;
BA_ "FlexKomSID" SG_ 324 Gr 1128;
BA_ "GenSigTimeout_ORC" SG_ 324 Gr 70;
BA_ "GenSigTimeout_IC" SG_ 324 Gr 210;
BA_ "GenSigTimeout_CBC" SG_ 324 Gr 210;
BA_ "GenSigStartValue" SG_ 324 Gr 15;
BA_ "FlexKomSigStartValue" SG_ 324 Gr "FF00h";
BA_ "GenSigCycleTime" SG_ 324 Gr 20;
BA_ "GenSigSNA" SG_ 324 EngSt_Enbl_Rq_TCM "0h";
BA_ "FlexKomIsMotorola" SG_ 324 EngSt_Enbl_Rq_TCM 1;
BA_ "FlexKomComment" SG_ 324 EngSt_Enbl_Rq_TCM "Enable engine start request";
BA_ "FlexKomSigName" SG_ 324 EngSt_Enbl_Rq_TCM "EngSt_Enbl_Rq_TCM";
BA_ "FlexKomSigLaenge" SG_ 324 EngSt_Enbl_Rq_TCM 1;
BA_ "FlexKomSigStartPos" SG_ 324 EngSt_Enbl_Rq_TCM 5;
BA_ "FlexKomSID" SG_ 324 EngSt_Enbl_Rq_TCM 1125;
BA_ "FlexKomSigStartValue" SG_ 324 EngSt_Enbl_Rq_TCM "00h";
BA_ "GenSigCycleTime" SG_ 324 EngSt_Enbl_Rq_TCM 20;
BA_ "GenMsgStartValue" BO_ 320 "0F3400C003FF00FFh";
BA_ "GenMsgNrOfRepetitions" BO_ 320 2;
BA_ "GenMsgDelayTime" BO_ 320 20;
BA_ "GenMsgCycleTime" BO_ 320 20;
BA_ "GenSigSNA" SG_ 320 SPCR_AS_Off_Rq "0h";
BA_ "FlexKomIsMotorola" SG_ 320 SPCR_AS_Off_Rq 1;
BA_ "FlexKomComment" SG_ 320 SPCR_AS_Off_Rq "ESP Brake Status Information";
BA_ "FlexKomSigName" SG_ 320 SPCR_AS_Off_Rq "ESP_BRK_STAT";
BA_ "FlexKomSigLaenge" SG_ 320 SPCR_AS_Off_Rq 64;
BA_ "FlexKomSigStartPos" SG_ 320 SPCR_AS_Off_Rq 7;
BA_ "FlexKomSigStartValue" SG_ 320 SPCR_AS_Off_Rq "0F3400C003FF00FFh";
BA_ "GenSigCycleTime" SG_ 320 SPCR_AS_Off_Rq 20;
BA_ "GenSigSNA" SG_ 320 RollTestMd_Actv "3h";
BA_ "FlexKomIsMotorola" SG_ 320 RollTestMd_Actv 1;
BA_ "FlexKomComment" SG_ 320 RollTestMd_Actv "ESP Brake Status Information";
BA_ "FlexKomSigName" SG_ 320 RollTestMd_Actv "ESP_BRK_STAT";
BA_ "FlexKomSigLaenge" SG_ 320 RollTestMd_Actv 64;
BA_ "FlexKomSigStartPos" SG_ 320 RollTestMd_Actv 7;
BA_ "GenSigStartValue" SG_ 320 RollTestMd_Actv 3;
BA_ "FlexKomSigStartValue" SG_ 320 RollTestMd_Actv "0F3400C003FF00FFh";
BA_ "GenSigCycleTime" SG_ 320 RollTestMd_Actv 20;
BA_ "GenSigSNA" SG_ 320 REF_VEH_SPEED "3FFh";
BA_ "FlexKomIsMotorola" SG_ 320 REF_VEH_SPEED 1;
BA_ "FlexKomComment" SG_ 320 REF_VEH_SPEED "ESP Brake Status Information";
BA_ "FlexKomSigName" SG_ 320 REF_VEH_SPEED "ESP_BRK_STAT";
BA_ "FlexKomSigLaenge" SG_ 320 REF_VEH_SPEED 64;
BA_ "FlexKomSigStartPos" SG_ 320 REF_VEH_SPEED 7;
BA_ "GenSigTimeout_ORC" SG_ 320 REF_VEH_SPEED 70;
BA_ "GenSigTimeout_IC" SG_ 320 REF_VEH_SPEED 210;
BA_ "GenSigStartValue" SG_ 320 REF_VEH_SPEED 1023;
BA_ "FlexKomSigStartValue" SG_ 320 REF_VEH_SPEED "0F3400C003FF00FFh";
BA_ "GenSigCycleTime" SG_ 320 REF_VEH_SPEED 20;
BA_ "GenSigSNA" SG_ 320 MC_Brk_Stat "0h";
BA_ "FlexKomIsMotorola" SG_ 320 MC_Brk_Stat 1;
BA_ "FlexKomComment" SG_ 320 MC_Brk_Stat "ESP Brake Status Information";
BA_ "FlexKomSigName" SG_ 320 MC_Brk_Stat "ESP_BRK_STAT";
BA_ "FlexKomSigLaenge" SG_ 320 MC_Brk_Stat 64;
BA_ "FlexKomSigStartPos" SG_ 320 MC_Brk_Stat 7;
BA_ "GenSigTimeout_ORC" SG_ 320 MC_Brk_Stat 70;
BA_ "GenSigTimeout_IC" SG_ 320 MC_Brk_Stat 210;
BA_ "FlexKomSigStartValue" SG_ 320 MC_Brk_Stat "0F3400C003FF00FFh";
BA_ "GenSigCycleTime" SG_ 320 MC_Brk_Stat 20;
BA_ "GenSigSNA" SG_ 320 FullBrk_Actv "0h";
BA_ "FlexKomIsMotorola" SG_ 320 FullBrk_Actv 1;
BA_ "FlexKomComment" SG_ 320 FullBrk_Actv "ESP Brake Status Information";
BA_ "FlexKomSigName" SG_ 320 FullBrk_Actv "ESP_BRK_STAT";
BA_ "FlexKomSigLaenge" SG_ 320 FullBrk_Actv 64;
BA_ "FlexKomSigStartPos" SG_ 320 FullBrk_Actv 7;
BA_ "GenSigTimeout_ORC" SG_ 320 FullBrk_Actv 70;
BA_ "GenSigTimeout_IC" SG_ 320 FullBrk_Actv 210;
BA_ "GenSigTimeout_CBC" SG_ 320 FullBrk_Actv 210;
BA_ "FlexKomSigStartValue" SG_ 320 FullBrk_Actv "0F3400C003FF00FFh";
BA_ "GenSigCycleTime" SG_ 320 FullBrk_Actv 20;
BA_ "GenSigSNA" SG_ 320 ESP_Sys_Stat "1h";
BA_ "FlexKomIsMotorola" SG_ 320 ESP_Sys_Stat 1;
BA_ "FlexKomComment" SG_ 320 ESP_Sys_Stat "ESP Brake Status Information";
BA_ "FlexKomSigName" SG_ 320 ESP_Sys_Stat "ESP_BRK_STAT";
BA_ "FlexKomSigLaenge" SG_ 320 ESP_Sys_Stat 64;
BA_ "FlexKomSigStartPos" SG_ 320 ESP_Sys_Stat 7;
BA_ "GenSigTimeout_ORC" SG_ 320 ESP_Sys_Stat 70;
BA_ "GenSigTimeout_IC" SG_ 320 ESP_Sys_Stat 210;
BA_ "GenSigStartValue" SG_ 320 ESP_Sys_Stat 1;
BA_ "FlexKomSigStartValue" SG_ 320 ESP_Sys_Stat "0F3400C003FF00FFh";
BA_ "GenSigCycleTime" SG_ 320 ESP_Sys_Stat 20;
BA_ "GenSigSNA" SG_ 320 EmgBrk_Actv "0h";
BA_ "FlexKomIsMotorola" SG_ 320 EmgBrk_Actv 1;
BA_ "FlexKomComment" SG_ 320 EmgBrk_Actv "ESP Brake Status Information";
BA_ "FlexKomSigName" SG_ 320 EmgBrk_Actv "ESP_BRK_STAT";
BA_ "FlexKomSigLaenge" SG_ 320 EmgBrk_Actv 64;
BA_ "FlexKomSigStartPos" SG_ 320 EmgBrk_Actv 7;
BA_ "GenSigTimeout_ORC" SG_ 320 EmgBrk_Actv 70;
BA_ "FlexKomSigStartValue" SG_ 320 EmgBrk_Actv "0F3400C003FF00FFh";
BA_ "GenSigCycleTime" SG_ 320 EmgBrk_Actv 20;
BA_ "GenSigCycleTime" SG_ 320 DTR_CC_Engaged 20;
BA_ "FlexKomSigStartValue" SG_ 320 DTR_CC_Engaged "0F3400C003FF00FFh";
BA_ "GenSigTimeout_ORC" SG_ 320 DTR_CC_Engaged 70;
BA_ "FlexKomSigStartPos" SG_ 320 DTR_CC_Engaged 7;
BA_ "FlexKomSigLaenge" SG_ 320 DTR_CC_Engaged 64;
BA_ "FlexKomSigName" SG_ 320 DTR_CC_Engaged "ESP_BRK_STAT";
BA_ "FlexKomComment" SG_ 320 DTR_CC_Engaged "ESP Brake Status Information";
BA_ "FlexKomIsMotorola" SG_ 320 DTR_CC_Engaged 1;
BA_ "GenSigSNA" SG_ 320 DTR_CC_Engaged "0h";
BA_ "GenSigSNA" SG_ 320 DTR_CC_Enabled "0h";
BA_ "FlexKomIsMotorola" SG_ 320 DTR_CC_Enabled 1;
BA_ "FlexKomComment" SG_ 320 DTR_CC_Enabled "ESP Brake Status Information";
BA_ "FlexKomSigName" SG_ 320 DTR_CC_Enabled "ESP_BRK_STAT";
BA_ "FlexKomSigLaenge" SG_ 320 DTR_CC_Enabled 64;
BA_ "FlexKomSigStartPos" SG_ 320 DTR_CC_Enabled 7;
BA_ "FlexKomSigStartValue" SG_ 320 DTR_CC_Enabled "0F3400C003FF00FFh";
BA_ "GenSigCycleTime" SG_ 320 DTR_CC_Enabled 20;
BA_ "GenSigSNA" SG_ 320 CRC_Brk_Stat "FFh";
BA_ "FlexKomIsMotorola" SG_ 320 CRC_Brk_Stat 1;
BA_ "FlexKomComment" SG_ 320 CRC_Brk_Stat "ESP Brake Status Information";
BA_ "FlexKomSigName" SG_ 320 CRC_Brk_Stat "ESP_BRK_STAT";
BA_ "FlexKomSigLaenge" SG_ 320 CRC_Brk_Stat 64;
BA_ "FlexKomSigStartPos" SG_ 320 CRC_Brk_Stat 7;
BA_ "GenSigTimeout_ORC" SG_ 320 CRC_Brk_Stat 70;
BA_ "GenSigTimeout_IC" SG_ 320 CRC_Brk_Stat 210;
BA_ "GenSigStartValue" SG_ 320 CRC_Brk_Stat 255;
BA_ "FlexKomSigStartValue" SG_ 320 CRC_Brk_Stat "0F3400C003FF00FFh";
BA_ "GenSigCycleTime" SG_ 320 CRC_Brk_Stat 20;
BA_ "GenSigSNA" SG_ 320 BrkPdl_Stat "3h";
BA_ "FlexKomIsMotorola" SG_ 320 BrkPdl_Stat 1;
BA_ "FlexKomComment" SG_ 320 BrkPdl_Stat "ESP Brake Status Information";
BA_ "FlexKomSigName" SG_ 320 BrkPdl_Stat "ESP_BRK_STAT";
BA_ "FlexKomSigLaenge" SG_ 320 BrkPdl_Stat 64;
BA_ "FlexKomSigStartPos" SG_ 320 BrkPdl_Stat 7;
BA_ "GenSigTimeout_ETM" SG_ 320 BrkPdl_Stat 210;
BA_ "GenSigTimeout_ORC" SG_ 320 BrkPdl_Stat 70;
BA_ "GenSigTimeout_IC" SG_ 320 BrkPdl_Stat 210;
BA_ "GenSigTimeout_CBC" SG_ 320 BrkPdl_Stat 510;
BA_ "GenSigStartValue" SG_ 320 BrkPdl_Stat 3;
BA_ "FlexKomSigStartValue" SG_ 320 BrkPdl_Stat "0F3400C003FF00FFh";
BA_ "GenSigCycleTime" SG_ 320 BrkPdl_Stat 20;
BA_ "GenSigSNA" SG_ 320 BrkPdl_Flt "0h";
BA_ "FlexKomIsMotorola" SG_ 320 BrkPdl_Flt 1;
BA_ "FlexKomComment" SG_ 320 BrkPdl_Flt "ESP Brake Status Information";
BA_ "FlexKomSigName" SG_ 320 BrkPdl_Flt "ESP_BRK_STAT";
BA_ "FlexKomSigLaenge" SG_ 320 BrkPdl_Flt 64;
BA_ "FlexKomSigStartPos" SG_ 320 BrkPdl_Flt 7;
BA_ "FlexKomSigStartValue" SG_ 320 BrkPdl_Flt "0F3400C003FF00FFh";
BA_ "GenSigCycleTime" SG_ 320 BrkPdl_Flt 20;
BA_ "GenSigSNA" SG_ 320 BrkIntrvntn_Enbl "0h";
BA_ "FlexKomIsMotorola" SG_ 320 BrkIntrvntn_Enbl 1;
BA_ "FlexKomComment" SG_ 320 BrkIntrvntn_Enbl "ESP Brake Status Information";
BA_ "FlexKomSigName" SG_ 320 BrkIntrvntn_Enbl "ESP_BRK_STAT";
BA_ "FlexKomSigLaenge" SG_ 320 BrkIntrvntn_Enbl 64;
BA_ "FlexKomSigStartPos" SG_ 320 BrkIntrvntn_Enbl 7;
BA_ "GenSigTimeout_ORC" SG_ 320 BrkIntrvntn_Enbl 70;
BA_ "FlexKomSigStartValue" SG_ 320 BrkIntrvntn_Enbl "0F3400C003FF00FFh";
BA_ "GenSigCycleTime" SG_ 320 BrkIntrvntn_Enbl 20;
BA_ "GenSigSNA" SG_ 320 BrkIntrvntn_Actv_ESP "0h";
BA_ "FlexKomIsMotorola" SG_ 320 BrkIntrvntn_Actv_ESP 1;
BA_ "FlexKomComment" SG_ 320 BrkIntrvntn_Actv_ESP "ESP Brake Status Information";
BA_ "FlexKomSigName" SG_ 320 BrkIntrvntn_Actv_ESP "ESP_BRK_STAT";
BA_ "FlexKomSigLaenge" SG_ 320 BrkIntrvntn_Actv_ESP 64;
BA_ "FlexKomSigStartPos" SG_ 320 BrkIntrvntn_Actv_ESP 7;
BA_ "GenSigTimeout_ORC" SG_ 320 BrkIntrvntn_Actv_ESP 70;
BA_ "FlexKomSigStartValue" SG_ 320 BrkIntrvntn_Actv_ESP "0F3400C003FF00FFh";
BA_ "GenSigCycleTime" SG_ 320 BrkIntrvntn_Actv_ESP 20;
BA_ "GenSigSNA" SG_ 320 BrkIntrvntn_Actv_AS "0h";
BA_ "FlexKomIsMotorola" SG_ 320 BrkIntrvntn_Actv_AS 1;
BA_ "FlexKomComment" SG_ 320 BrkIntrvntn_Actv_AS "ESP Brake Status Information";
BA_ "FlexKomSigName" SG_ 320 BrkIntrvntn_Actv_AS "ESP_BRK_STAT";
BA_ "FlexKomSigLaenge" SG_ 320 BrkIntrvntn_Actv_AS 64;
BA_ "FlexKomSigStartPos" SG_ 320 BrkIntrvntn_Actv_AS 7;
BA_ "GenSigTimeout_ORC" SG_ 320 BrkIntrvntn_Actv_AS 70;
BA_ "FlexKomSigStartValue" SG_ 320 BrkIntrvntn_Actv_AS "0F3400C003FF00FFh";
BA_ "GenSigCycleTime" SG_ 320 BrkIntrvntn_Actv_AS 20;
BA_ "GenSigSNA" SG_ 320 Brk_Thermdl "0h";
BA_ "FlexKomIsMotorola" SG_ 320 Brk_Thermdl 1;
BA_ "FlexKomComment" SG_ 320 Brk_Thermdl "ESP Brake Status Information";
BA_ "FlexKomSigName" SG_ 320 Brk_Thermdl "ESP_BRK_STAT";
BA_ "FlexKomSigLaenge" SG_ 320 Brk_Thermdl 64;
BA_ "FlexKomSigStartPos" SG_ 320 Brk_Thermdl 7;
BA_ "FlexKomSigStartValue" SG_ 320 Brk_Thermdl "0F3400C003FF00FFh";
BA_ "GenSigCycleTime" SG_ 320 Brk_Thermdl 20;
BA_ "GenSigSNA" SG_ 320 Brk_Stat "3h";
BA_ "FlexKomIsMotorola" SG_ 320 Brk_Stat 1;
BA_ "FlexKomComment" SG_ 320 Brk_Stat "ESP Brake Status Information";
BA_ "FlexKomSigName" SG_ 320 Brk_Stat "ESP_BRK_STAT";
BA_ "FlexKomSigLaenge" SG_ 320 Brk_Stat 64;
BA_ "FlexKomSigStartPos" SG_ 320 Brk_Stat 7;
BA_ "GenSigTimeout_ORC" SG_ 320 Brk_Stat 70;
BA_ "GenSigTimeout_CBC" SG_ 320 Brk_Stat 210;
BA_ "GenSigStartValue" SG_ 320 Brk_Stat 3;
BA_ "FlexKomSigStartValue" SG_ 320 Brk_Stat "0F3400C003FF00FFh";
BA_ "GenSigCycleTime" SG_ 320 Brk_Stat 20;
BA_ "GenSigSNA" SG_ 320 ABS_BrkEvt "0h";
BA_ "FlexKomIsMotorola" SG_ 320 ABS_BrkEvt 1;
BA_ "FlexKomComment" SG_ 320 ABS_BrkEvt "ESP Brake Status Information";
BA_ "FlexKomSigName" SG_ 320 ABS_BrkEvt "ESP_BRK_STAT";
BA_ "FlexKomSigLaenge" SG_ 320 ABS_BrkEvt 64;
BA_ "FlexKomSigStartPos" SG_ 320 ABS_BrkEvt 7;
BA_ "GenSigTimeout_ETM" SG_ 320 ABS_BrkEvt 210;
BA_ "GenSigTimeout_ORC" SG_ 320 ABS_BrkEvt 70;
BA_ "FlexKomSigStartValue" SG_ 320 ABS_BrkEvt "0F3400C003FF00FFh";
BA_ "GenSigCycleTime" SG_ 320 ABS_BrkEvt 20;
BA_ "GenMsgStartValue" BO_ 308 "08FFFF00FFFF00FFh";
BA_ "GenMsgNrOfRepetitions" BO_ 308 2;
BA_ "GenMsgDelayTime" BO_ 308 20;
BA_ "GenMsgCycleTime" BO_ 308 20;
BA_ "GenSigSNA" SG_ 308 V_MAX_TM "FFh";
BA_ "FlexKomIsMotorola" SG_ 308 V_MAX_TM 1;
BA_ "FlexKomComment" SG_ 308 V_MAX_TM "Max. or cruise control set speed";
BA_ "FlexKomSigName" SG_ 308 V_MAX_TM "V_MAX_TM";
BA_ "FlexKomSigLaenge" SG_ 308 V_MAX_TM 8;
BA_ "FlexKomSigStartPos" SG_ 308 V_MAX_TM 15;
BA_ "FlexKomSID" SG_ 308 V_MAX_TM 1252;
BA_ "GenSigStartValue" SG_ 308 V_MAX_TM 255;
BA_ "FlexKomSigStartValue" SG_ 308 V_MAX_TM "FFh";
BA_ "GenSigCycleTime" SG_ 308 V_MAX_TM 20;
BA_ "GenSigSNA" SG_ 308 Rel_Thrt_ENG "FFh";
BA_ "FlexKomIsMotorola" SG_ 308 Rel_Thrt_ENG 1;
BA_ "FlexKomComment" SG_ 308 Rel_Thrt_ENG "General engine Data";
BA_ "FlexKomSigName" SG_ 308 Rel_Thrt_ENG "Engine_1_Pkt";
BA_ "FlexKomSigLaenge" SG_ 308 Rel_Thrt_ENG 48;
BA_ "FlexKomSigStartPos" SG_ 308 Rel_Thrt_ENG 23;
BA_ "FlexKomSID" SG_ 308 Rel_Thrt_ENG 1352;
BA_ "GenSigStartValue" SG_ 308 Rel_Thrt_ENG 255;
BA_ "FlexKomSigStartValue" SG_ 308 Rel_Thrt_ENG "FF00FFFF00FFh";
BA_ "GenSigCycleTime" SG_ 308 Rel_Thrt_ENG 20;
BA_ "GenSigSNA" SG_ 308 Rel_Pdl_ENG "FFh";
BA_ "FlexKomIsMotorola" SG_ 308 Rel_Pdl_ENG 1;
BA_ "FlexKomComment" SG_ 308 Rel_Pdl_ENG "General engine Data";
BA_ "FlexKomSigName" SG_ 308 Rel_Pdl_ENG "Engine_1_Pkt";
BA_ "FlexKomSigLaenge" SG_ 308 Rel_Pdl_ENG 48;
BA_ "FlexKomSigStartPos" SG_ 308 Rel_Pdl_ENG 23;
BA_ "FlexKomSID" SG_ 308 Rel_Pdl_ENG 1352;
BA_ "GenSigStartValue" SG_ 308 Rel_Pdl_ENG 255;
BA_ "FlexKomSigStartValue" SG_ 308 Rel_Pdl_ENG "FF00FFFF00FFh";
BA_ "GenSigCycleTime" SG_ 308 Rel_Pdl_ENG 20;
BA_ "GenSigSNA" SG_ 308 MAP_ENG "FFh";
BA_ "FlexKomIsMotorola" SG_ 308 MAP_ENG 1;
BA_ "FlexKomComment" SG_ 308 MAP_ENG "General engine Data";
BA_ "FlexKomSigName" SG_ 308 MAP_ENG "Engine_1_Pkt";
BA_ "FlexKomSigLaenge" SG_ 308 MAP_ENG 48;
BA_ "FlexKomSigStartPos" SG_ 308 MAP_ENG 23;
BA_ "FlexKomSID" SG_ 308 MAP_ENG 1352;
BA_ "GenSigTimeout_ETM" SG_ 308 MAP_ENG 1010;
BA_ "GenSigStartValue" SG_ 308 MAP_ENG 255;
BA_ "FlexKomSigStartValue" SG_ 308 MAP_ENG "FF00FFFF00FFh";
BA_ "GenSigCycleTime" SG_ 308 MAP_ENG 20;
BA_ "GenSigSNA" SG_ 308 CRUISE_ON "0h";
BA_ "FlexKomIsMotorola" SG_ 308 CRUISE_ON 1;
BA_ "FlexKomComment" SG_ 308 CRUISE_ON "Cruise control system 'on'";
BA_ "FlexKomSigName" SG_ 308 CRUISE_ON "CRUISE_ON";
BA_ "FlexKomSigLaenge" SG_ 308 CRUISE_ON 1;
BA_ "FlexKomSigStartPos" SG_ 308 CRUISE_ON 7;
BA_ "FlexKomSID" SG_ 308 CRUISE_ON 1250;
BA_ "GenSigTimeout_ORC" SG_ 308 CRUISE_ON 70;
BA_ "GenSigTimeout_SCCM" SG_ 308 CRUISE_ON 210;
BA_ "GenSigTimeout_IC" SG_ 308 CRUISE_ON 210;
BA_ "FlexKomSigStartValue" SG_ 308 CRUISE_ON "00h";
BA_ "GenSigCycleTime" SG_ 308 CRUISE_ON 20;
BA_ "GenSigSNA" SG_ 308 CRUISE_EGD "0h";
BA_ "FlexKomIsMotorola" SG_ 308 CRUISE_EGD 1;
BA_ "FlexKomComment" SG_ 308 CRUISE_EGD "Cruise system is controlling speed";
BA_ "FlexKomSigName" SG_ 308 CRUISE_EGD "CRUISE_EGD";
BA_ "FlexKomSigLaenge" SG_ 308 CRUISE_EGD 1;
BA_ "FlexKomSigStartPos" SG_ 308 CRUISE_EGD 5;
BA_ "FlexKomSID" SG_ 308 CRUISE_EGD 856;
BA_ "GenSigTimeout_ORC" SG_ 308 CRUISE_EGD 70;
BA_ "GenSigTimeout_IC" SG_ 308 CRUISE_EGD 210;
BA_ "GenSigTimeout_CBC" SG_ 308 CRUISE_EGD 210;
BA_ "FlexKomSigStartValue" SG_ 308 CRUISE_EGD "00h";
BA_ "GenSigCycleTime" SG_ 308 CRUISE_EGD 20;
BA_ "GenSigSNA" SG_ 308 BARO_ENG "FFh";
BA_ "FlexKomIsMotorola" SG_ 308 BARO_ENG 1;
BA_ "FlexKomComment" SG_ 308 BARO_ENG "General engine Data";
BA_ "FlexKomSigName" SG_ 308 BARO_ENG "Engine_1_Pkt";
BA_ "FlexKomSigLaenge" SG_ 308 BARO_ENG 48;
BA_ "FlexKomSigStartPos" SG_ 308 BARO_ENG 23;
BA_ "FlexKomSID" SG_ 308 BARO_ENG 1352;
BA_ "FlexKomSigStartValue" SG_ 308 BARO_ENG "FF00FFFF00FFh";
BA_ "GenSigCycleTime" SG_ 308 BARO_ENG 20;
BA_ "GenMsgStartValue" BO_ 300 "0200FF0000000000h";
BA_ "GenMsgNrOfRepetitions" BO_ 300 2;
BA_ "GenMsgDelayTime" BO_ 300 20;
BA_ "GenMsgCycleTime" BO_ 300 100;
BA_ "GenSigSNA" SG_ 300 PS_SysType "0h";
BA_ "FlexKomIsMotorola" SG_ 300 PS_SysType 1;
BA_ "FlexKomComment" SG_ 300 PS_SysType "EPS_A1_PKT";
BA_ "FlexKomSigName" SG_ 300 PS_SysType "EPS_A1_PKT";
BA_ "FlexKomSigLaenge" SG_ 300 PS_SysType 64;
BA_ "FlexKomSigStartPos" SG_ 300 PS_SysType 7;
BA_ "FlexKomSID" SG_ 300 PS_SysType 846;
BA_ "GenSigTimeout_IC" SG_ 300 PS_SysType 1050;
BA_ "FlexKomSigStartValue" SG_ 300 PS_SysType "0200FF0000000000h";
BA_ "GenSigCycleTime" SG_ 300 PS_SysType 100;
BA_ "GenSigSNA" SG_ 300 EPS_Warn_Disp_Rq "7h";
BA_ "FlexKomIsMotorola" SG_ 300 EPS_Warn_Disp_Rq 1;
BA_ "FlexKomComment" SG_ 300 EPS_Warn_Disp_Rq "EPS_A1_PKT";
BA_ "FlexKomSigName" SG_ 300 EPS_Warn_Disp_Rq "EPS_A1_PKT";
BA_ "FlexKomSigLaenge" SG_ 300 EPS_Warn_Disp_Rq 64;
BA_ "FlexKomSigStartPos" SG_ 300 EPS_Warn_Disp_Rq 7;
BA_ "FlexKomSID" SG_ 300 EPS_Warn_Disp_Rq 846;
BA_ "GenSigTimeout_ORC" SG_ 300 EPS_Warn_Disp_Rq 350;
BA_ "GenSigTimeout_IC" SG_ 300 EPS_Warn_Disp_Rq 1050;
BA_ "GenSigTimeout_CBC" SG_ 300 EPS_Warn_Disp_Rq 1050;
BA_ "FlexKomSigStartValue" SG_ 300 EPS_Warn_Disp_Rq "0200FF0000000000h";
BA_ "GenSigCycleTime" SG_ 300 EPS_Warn_Disp_Rq 100;
BA_ "GenSigSNA" SG_ 300 EPS_MODE_STAT "7h";
BA_ "FlexKomIsMotorola" SG_ 300 EPS_MODE_STAT 1;
BA_ "FlexKomComment" SG_ 300 EPS_MODE_STAT "EPS_A1_PKT";
BA_ "FlexKomSigName" SG_ 300 EPS_MODE_STAT "EPS_A1_PKT";
BA_ "FlexKomSigLaenge" SG_ 300 EPS_MODE_STAT 64;
BA_ "FlexKomSigStartPos" SG_ 300 EPS_MODE_STAT 7;
BA_ "FlexKomSID" SG_ 300 EPS_MODE_STAT 846;
BA_ "GenSigTimeout_CBC" SG_ 300 EPS_MODE_STAT 1050;
BA_ "FlexKomSigStartValue" SG_ 300 EPS_MODE_STAT "0200FF0000000000h";
BA_ "GenSigCycleTime" SG_ 300 EPS_MODE_STAT 100;
BA_ "GenSigSNA" SG_ 300 EPS_Curr "FFh";
BA_ "FlexKomIsMotorola" SG_ 300 EPS_Curr 1;
BA_ "FlexKomComment" SG_ 300 EPS_Curr "EPS_A1_PKT";
BA_ "FlexKomSigName" SG_ 300 EPS_Curr "EPS_A1_PKT";
BA_ "FlexKomSigLaenge" SG_ 300 EPS_Curr 64;
BA_ "FlexKomSigStartPos" SG_ 300 EPS_Curr 7;
BA_ "FlexKomSID" SG_ 300 EPS_Curr 846;
BA_ "GenSigStartValue" SG_ 300 EPS_Curr 255;
BA_ "FlexKomSigStartValue" SG_ 300 EPS_Curr "0200FF0000000000h";
BA_ "GenSigCycleTime" SG_ 300 EPS_Curr 100;
BA_ "GenSigSNA" SG_ 300 EPS_AsstStat "7h";
BA_ "FlexKomIsMotorola" SG_ 300 EPS_AsstStat 1;
BA_ "FlexKomComment" SG_ 300 EPS_AsstStat "EPS_A1_PKT";
BA_ "FlexKomSigName" SG_ 300 EPS_AsstStat "EPS_A1_PKT";
BA_ "FlexKomSigLaenge" SG_ 300 EPS_AsstStat 64;
BA_ "FlexKomSigStartPos" SG_ 300 EPS_AsstStat 7;
BA_ "FlexKomSID" SG_ 300 EPS_AsstStat 846;
BA_ "GenSigTimeout_ORC" SG_ 300 EPS_AsstStat 350;
BA_ "GenSigTimeout_IC" SG_ 300 EPS_AsstStat 1050;
BA_ "GenSigStartValue" SG_ 300 EPS_AsstStat 1;
BA_ "FlexKomSigStartValue" SG_ 300 EPS_AsstStat "0200FF0000000000h";
BA_ "GenSigCycleTime" SG_ 300 EPS_AsstStat 100;
BA_ "GenSigCycleTime" SG_ 300 EngineFanRequestActivation 100;
BA_ "FlexKomSigStartValue" SG_ 300 EngineFanRequestActivation "0200FF0000000000h";
BA_ "FlexKomSID" SG_ 300 EngineFanRequestActivation 846;
BA_ "FlexKomSigStartPos" SG_ 300 EngineFanRequestActivation 7;
BA_ "FlexKomSigLaenge" SG_ 300 EngineFanRequestActivation 64;
BA_ "FlexKomSigName" SG_ 300 EngineFanRequestActivation "EPS_A1_PKT";
BA_ "FlexKomComment" SG_ 300 EngineFanRequestActivation "EPS_A1_PKT";
BA_ "FlexKomIsMotorola" SG_ 300 EngineFanRequestActivation 1;
BA_ "GenSigSNA" SG_ 300 EngineFanRequestActivation "0h";
BA_ "GenMsgStartValue" BO_ 292 "0000000000FFFFFFh";
BA_ "GenMsgNrOfRepetitions" BO_ 292 2;
BA_ "GenMsgDelayTime" BO_ 292 20;
BA_ "GenMsgCycleTime" BO_ 292 20;
BA_ "GenSigSNA" SG_ 292 WhlPlsCnt_RR "FFh";
BA_ "FlexKomIsMotorola" SG_ 292 WhlPlsCnt_RR 1;
BA_ "FlexKomComment" SG_ 292 WhlPlsCnt_RR "ESP Wheel pulse counts";
BA_ "FlexKomSigName" SG_ 292 WhlPlsCnt_RR "ESP_WHL_PULS";
BA_ "FlexKomSigLaenge" SG_ 292 WhlPlsCnt_RR 32;
BA_ "FlexKomSigStartPos" SG_ 292 WhlPlsCnt_RR 7;
BA_ "FlexKomSID" SG_ 292 WhlPlsCnt_RR 65;
BA_ "GenSigTimeout_IC" SG_ 292 WhlPlsCnt_RR 210;
BA_ "GenSigTimeout_CBC" SG_ 292 WhlPlsCnt_RR 210;
BA_ "FlexKomSigStartValue" SG_ 292 WhlPlsCnt_RR "00000000h";
BA_ "GenSigCycleTime" SG_ 292 WhlPlsCnt_RR 20;
BA_ "GenSigSNA" SG_ 292 WhlPlsCnt_RL "FFh";
BA_ "FlexKomIsMotorola" SG_ 292 WhlPlsCnt_RL 1;
BA_ "FlexKomComment" SG_ 292 WhlPlsCnt_RL "ESP Wheel pulse counts";
BA_ "FlexKomSigName" SG_ 292 WhlPlsCnt_RL "ESP_WHL_PULS";
BA_ "FlexKomSigLaenge" SG_ 292 WhlPlsCnt_RL 32;
BA_ "FlexKomSigStartPos" SG_ 292 WhlPlsCnt_RL 7;
BA_ "FlexKomSID" SG_ 292 WhlPlsCnt_RL 65;
BA_ "GenSigTimeout_IC" SG_ 292 WhlPlsCnt_RL 210;
BA_ "GenSigTimeout_CBC" SG_ 292 WhlPlsCnt_RL 210;
BA_ "FlexKomSigStartValue" SG_ 292 WhlPlsCnt_RL "00000000h";
BA_ "GenSigCycleTime" SG_ 292 WhlPlsCnt_RL 20;
BA_ "GenSigSNA" SG_ 292 WhlPlsCnt_FR "FFh";
BA_ "FlexKomIsMotorola" SG_ 292 WhlPlsCnt_FR 1;
BA_ "FlexKomComment" SG_ 292 WhlPlsCnt_FR "ESP Wheel pulse counts";
BA_ "FlexKomSigName" SG_ 292 WhlPlsCnt_FR "ESP_WHL_PULS";
BA_ "FlexKomSigLaenge" SG_ 292 WhlPlsCnt_FR 32;
BA_ "FlexKomSigStartPos" SG_ 292 WhlPlsCnt_FR 7;
BA_ "FlexKomSID" SG_ 292 WhlPlsCnt_FR 65;
BA_ "GenSigTimeout_IC" SG_ 292 WhlPlsCnt_FR 210;
BA_ "GenSigTimeout_CBC" SG_ 292 WhlPlsCnt_FR 210;
BA_ "FlexKomSigStartValue" SG_ 292 WhlPlsCnt_FR "00000000h";
BA_ "GenSigCycleTime" SG_ 292 WhlPlsCnt_FR 20;
BA_ "GenSigSNA" SG_ 292 WhlPlsCnt_FL "FFh";
BA_ "FlexKomIsMotorola" SG_ 292 WhlPlsCnt_FL 1;
BA_ "FlexKomComment" SG_ 292 WhlPlsCnt_FL "ESP Wheel pulse counts";
BA_ "FlexKomSigName" SG_ 292 WhlPlsCnt_FL "ESP_WHL_PULS";
BA_ "FlexKomSigLaenge" SG_ 292 WhlPlsCnt_FL 32;
BA_ "FlexKomSigStartPos" SG_ 292 WhlPlsCnt_FL 7;
BA_ "FlexKomSID" SG_ 292 WhlPlsCnt_FL 65;
BA_ "GenSigTimeout_IC" SG_ 292 WhlPlsCnt_FL 210;
BA_ "GenSigTimeout_CBC" SG_ 292 WhlPlsCnt_FL 210;
BA_ "FlexKomSigStartValue" SG_ 292 WhlPlsCnt_FL "00000000h";
BA_ "GenSigCycleTime" SG_ 292 WhlPlsCnt_FL 20;
BA_ "GenMsgStartValue" BO_ 290 "00FF000FFFFFh";
BA_ "GenMsgNrOfRepetitions" BO_ 290 2;
BA_ "GenMsgDelayTime" BO_ 290 20;
BA_ "GenMsgCycleTime" BO_ 290 20;
BA_ "GenSigSNA" SG_ 290 NMOTS "FFFFh";
BA_ "FlexKomIsMotorola" SG_ 290 NMOTS 1;
BA_ "FlexKomComment" SG_ 290 NMOTS "Target idle speed";
BA_ "FlexKomSigName" SG_ 290 NMOTS "NMOTS";
BA_ "FlexKomSigLaenge" SG_ 290 NMOTS 16;
BA_ "FlexKomSigStartPos" SG_ 290 NMOTS 39;
BA_ "FlexKomSID" SG_ 290 NMOTS 1248;
BA_ "GenSigStartValue" SG_ 290 NMOTS 65535;
BA_ "FlexKomSigStartValue" SG_ 290 NMOTS "FFFFh";
BA_ "GenSigCycleTime" SG_ 290 NMOTS 20;
BA_ "GenSigSNA" SG_ 290 GrMax_Rq_ECM "0h";
BA_ "FlexKomIsMotorola" SG_ 290 GrMax_Rq_ECM 1;
BA_ "FlexKomComment" SG_ 290 GrMax_Rq_ECM "Target gear upper and lower limit";
BA_ "FlexKomSigName" SG_ 290 GrMax_Rq_ECM "ECM_Gear";
BA_ "FlexKomSigLaenge" SG_ 290 GrMax_Rq_ECM 6;
BA_ "FlexKomSigStartPos" SG_ 290 GrMax_Rq_ECM 21;
BA_ "FlexKomSID" SG_ 290 GrMax_Rq_ECM 1243;
BA_ "FlexKomSigStartValue" SG_ 290 GrMax_Rq_ECM "00h";
BA_ "GenSigCycleTime" SG_ 290 GrMax_Rq_ECM 20;
BA_ "GenMsgStartValue" BO_ 288 "1FFFFF1FFF00FFh";
BA_ "GenMsgNrOfRepetitions" BO_ 288 2;
BA_ "GenMsgDelayTime" BO_ 288 20;
BA_ "GenMsgCycleTime" BO_ 288 20;
BA_ "GenSigSNA" SG_ 288 RPMOverRev "0h";
BA_ "FlexKomIsMotorola" SG_ 288 RPMOverRev 1;
BA_ "FlexKomComment" SG_ 288 RPMOverRev "ECM_A2 Packet";
BA_ "FlexKomSigName" SG_ 288 RPMOverRev "ECM_A2_PKT";
BA_ "FlexKomSigLaenge" SG_ 288 RPMOverRev 56;
BA_ "FlexKomSigStartPos" SG_ 288 RPMOverRev 7;
BA_ "FlexKomSID" SG_ 288 RPMOverRev 455;
BA_ "FlexKomSigStartValue" SG_ 288 RPMOverRev "1FFFFF1FFF00FFh";
BA_ "GenSigCycleTime" SG_ 288 RPMOverRev 20;
BA_ "GenSigSNA" SG_ 288 MC_ECM_A2 "0h";
BA_ "FlexKomIsMotorola" SG_ 288 MC_ECM_A2 1;
BA_ "FlexKomComment" SG_ 288 MC_ECM_A2 "ECM_A2 Packet";
BA_ "FlexKomSigName" SG_ 288 MC_ECM_A2 "ECM_A2_PKT";
BA_ "FlexKomSigLaenge" SG_ 288 MC_ECM_A2 56;
BA_ "FlexKomSigStartPos" SG_ 288 MC_ECM_A2 7;
BA_ "FlexKomSID" SG_ 288 MC_ECM_A2 455;
BA_ "FlexKomSigStartValue" SG_ 288 MC_ECM_A2 "1FFFFF1FFF00FFh";
BA_ "GenSigCycleTime" SG_ 288 MC_ECM_A2 20;
BA_ "GenSigSNA" SG_ 288 LV12PwrFreeRq "0h";
BA_ "FlexKomIsMotorola" SG_ 288 LV12PwrFreeRq 1;
BA_ "FlexKomComment" SG_ 288 LV12PwrFreeRq "ECM_A2 Packet";
BA_ "FlexKomSigName" SG_ 288 LV12PwrFreeRq "ECM_A2_PKT";
BA_ "FlexKomSigLaenge" SG_ 288 LV12PwrFreeRq 56;
BA_ "FlexKomSigStartPos" SG_ 288 LV12PwrFreeRq 7;
BA_ "FlexKomSID" SG_ 288 LV12PwrFreeRq 455;
BA_ "FlexKomSigStartValue" SG_ 288 LV12PwrFreeRq "1FFFFF1FFF00FFh";
BA_ "GenSigCycleTime" SG_ 288 LV12PwrFreeRq 20;
BA_ "GenSigSNA" SG_ 288 ESS_RqShftPark "0h";
BA_ "FlexKomIsMotorola" SG_ 288 ESS_RqShftPark 1;
BA_ "FlexKomComment" SG_ 288 ESS_RqShftPark "ECM_A2 Packet";
BA_ "FlexKomSigName" SG_ 288 ESS_RqShftPark "ECM_A2_PKT";
BA_ "FlexKomSigLaenge" SG_ 288 ESS_RqShftPark 56;
BA_ "FlexKomSigStartPos" SG_ 288 ESS_RqShftPark 7;
BA_ "FlexKomSID" SG_ 288 ESS_RqShftPark 455;
BA_ "FlexKomSigStartValue" SG_ 288 ESS_RqShftPark "1FFFFF1FFF00FFh";
BA_ "GenSigCycleTime" SG_ 288 ESS_RqShftPark 20;
BA_ "GenSigSNA" SG_ 288 EngTrq_Enbl_Rq_ESC "0h";
BA_ "FlexKomIsMotorola" SG_ 288 EngTrq_Enbl_Rq_ESC 1;
BA_ "FlexKomComment" SG_ 288 EngTrq_Enbl_Rq_ESC "ECM_A2 Packet";
BA_ "FlexKomSigName" SG_ 288 EngTrq_Enbl_Rq_ESC "ECM_A2_PKT";
BA_ "FlexKomSigLaenge" SG_ 288 EngTrq_Enbl_Rq_ESC 56;
BA_ "FlexKomSigStartPos" SG_ 288 EngTrq_Enbl_Rq_ESC 7;
BA_ "FlexKomSID" SG_ 288 EngTrq_Enbl_Rq_ESC 455;
BA_ "FlexKomSigStartValue" SG_ 288 EngTrq_Enbl_Rq_ESC "1FFFFF1FFF00FFh";
BA_ "GenSigCycleTime" SG_ 288 EngTrq_Enbl_Rq_ESC 20;
BA_ "GenSigSNA" SG_ 288 EngTrq_Enbl_Rq_AS "0h";
BA_ "FlexKomIsMotorola" SG_ 288 EngTrq_Enbl_Rq_AS 1;
BA_ "FlexKomComment" SG_ 288 EngTrq_Enbl_Rq_AS "ECM_A2 Packet";
BA_ "FlexKomSigName" SG_ 288 EngTrq_Enbl_Rq_AS "ECM_A2_PKT";
BA_ "FlexKomSigLaenge" SG_ 288 EngTrq_Enbl_Rq_AS 56;
BA_ "FlexKomSigStartPos" SG_ 288 EngTrq_Enbl_Rq_AS 7;
BA_ "FlexKomSID" SG_ 288 EngTrq_Enbl_Rq_AS 455;
BA_ "FlexKomSigStartValue" SG_ 288 EngTrq_Enbl_Rq_AS "1FFFFF1FFF00FFh";
BA_ "GenSigCycleTime" SG_ 288 EngTrq_Enbl_Rq_AS 20;
BA_ "GenSigSNA" SG_ 288 ECM_LHOM "0h";
BA_ "FlexKomIsMotorola" SG_ 288 ECM_LHOM 1;
BA_ "FlexKomComment" SG_ 288 ECM_LHOM "ECM_A2 Packet";
BA_ "FlexKomSigName" SG_ 288 ECM_LHOM "ECM_A2_PKT";
BA_ "FlexKomSigLaenge" SG_ 288 ECM_LHOM 56;
BA_ "FlexKomSigStartPos" SG_ 288 ECM_LHOM 7;
BA_ "FlexKomSID" SG_ 288 ECM_LHOM 455;
BA_ "FlexKomSigStartValue" SG_ 288 ECM_LHOM "1FFFFF1FFF00FFh";
BA_ "GenSigCycleTime" SG_ 288 ECM_LHOM 20;
BA_ "GenSigSNA" SG_ 288 CRUISE_OVERRIDE "0h";
BA_ "FlexKomIsMotorola" SG_ 288 CRUISE_OVERRIDE 1;
BA_ "FlexKomComment" SG_ 288 CRUISE_OVERRIDE "ECM_A2 Packet";
BA_ "FlexKomSigName" SG_ 288 CRUISE_OVERRIDE "ECM_A2_PKT";
BA_ "FlexKomSigLaenge" SG_ 288 CRUISE_OVERRIDE 56;
BA_ "FlexKomSigStartPos" SG_ 288 CRUISE_OVERRIDE 7;
BA_ "FlexKomSID" SG_ 288 CRUISE_OVERRIDE 455;
BA_ "GenSigTimeout_IC" SG_ 288 CRUISE_OVERRIDE 210;
BA_ "FlexKomSigStartValue" SG_ 288 CRUISE_OVERRIDE "1FFFFF1FFF00FFh";
BA_ "GenSigCycleTime" SG_ 288 CRUISE_OVERRIDE 20;
BA_ "GenSigSNA" SG_ 288 CRC_ECM_A2 "FFh";
BA_ "FlexKomIsMotorola" SG_ 288 CRC_ECM_A2 1;
BA_ "FlexKomComment" SG_ 288 CRC_ECM_A2 "ECM_A2 Packet";
BA_ "FlexKomSigName" SG_ 288 CRC_ECM_A2 "ECM_A2_PKT";
BA_ "FlexKomSigLaenge" SG_ 288 CRC_ECM_A2 56;
BA_ "FlexKomSigStartPos" SG_ 288 CRC_ECM_A2 7;
BA_ "FlexKomSID" SG_ 288 CRC_ECM_A2 455;
BA_ "GenSigStartValue" SG_ 288 CRC_ECM_A2 255;
BA_ "FlexKomSigStartValue" SG_ 288 CRC_ECM_A2 "1FFFFF1FFF00FFh";
BA_ "GenSigCycleTime" SG_ 288 CRC_ECM_A2 20;
BA_ "GenSigSNA" SG_ 288 AccelPdlPosnSens_Flt "0h";
BA_ "FlexKomIsMotorola" SG_ 288 AccelPdlPosnSens_Flt 1;
BA_ "FlexKomComment" SG_ 288 AccelPdlPosnSens_Flt "ECM_A2 Packet";
BA_ "FlexKomSigName" SG_ 288 AccelPdlPosnSens_Flt "ECM_A2_PKT";
BA_ "FlexKomSigLaenge" SG_ 288 AccelPdlPosnSens_Flt 56;
BA_ "FlexKomSigStartPos" SG_ 288 AccelPdlPosnSens_Flt 7;
BA_ "FlexKomSID" SG_ 288 AccelPdlPosnSens_Flt 455;
BA_ "FlexKomSigStartValue" SG_ 288 AccelPdlPosnSens_Flt "1FFFFF1FFF00FFh";
BA_ "GenSigCycleTime" SG_ 288 AccelPdlPosnSens_Flt 20;
BA_ "GenSigSNA" SG_ 288 AccelPdlPosn "FFh";
BA_ "FlexKomIsMotorola" SG_ 288 AccelPdlPosn 1;
BA_ "FlexKomComment" SG_ 288 AccelPdlPosn "ECM_A2 Packet";
BA_ "FlexKomSigName" SG_ 288 AccelPdlPosn "ECM_A2_PKT";
BA_ "FlexKomSigLaenge" SG_ 288 AccelPdlPosn 56;
BA_ "FlexKomSigStartPos" SG_ 288 AccelPdlPosn 7;
BA_ "FlexKomSID" SG_ 288 AccelPdlPosn 455;
BA_ "GenSigTimeout_ETM" SG_ 288 AccelPdlPosn 210;
BA_ "GenSigStartValue" SG_ 288 AccelPdlPosn 255;
BA_ "FlexKomSigStartValue" SG_ 288 AccelPdlPosn "1FFFFF1FFF00FFh";
BA_ "GenSigCycleTime" SG_ 288 AccelPdlPosn 20;
BA_ "GenMsgStartValue" BO_ 284 "0FFF0FFFFFFF00FFh";
BA_ "GenMsgNrOfRepetitions" BO_ 284 2;
BA_ "GenMsgDelayTime" BO_ 284 20;
BA_ "GenMsgCycleTime" BO_ 284 20;
BA_ "GenSigSNA" SG_ 284 VehSpSts "0h";
BA_ "FlexKomIsMotorola" SG_ 284 VehSpSts 1;
BA_ "FlexKomComment" SG_ 284 VehSpSts "Vehicle Speed Packet";
BA_ "FlexKomSigName" SG_ 284 VehSpSts "VEH_SPEED_PKT";
BA_ "FlexKomSigLaenge" SG_ 284 VehSpSts 64;
BA_ "FlexKomSigStartPos" SG_ 284 VehSpSts 7;
BA_ "FlexKomSID" SG_ 284 VehSpSts 11;
BA_ "FlexKomSigStartValue" SG_ 284 VehSpSts "0FFF0FFFFFFF00FFh";
BA_ "GenSigCycleTime" SG_ 284 VehSpSts 20;
BA_ "GenSigSNA" SG_ 284 VEH_SPEED "FFFFh";
BA_ "FlexKomIsMotorola" SG_ 284 VEH_SPEED 1;
BA_ "FlexKomComment" SG_ 284 VEH_SPEED "Vehicle Speed Packet";
BA_ "FlexKomSigName" SG_ 284 VEH_SPEED "VEH_SPEED_PKT";
BA_ "FlexKomSigLaenge" SG_ 284 VEH_SPEED 64;
BA_ "FlexKomSigStartPos" SG_ 284 VEH_SPEED 7;
BA_ "FlexKomSID" SG_ 284 VEH_SPEED 11;
BA_ "GenSigTimeout_ORC" SG_ 284 VEH_SPEED 70;
BA_ "GenSigTimeout_ESM" SG_ 284 VEH_SPEED 210;
BA_ "GenSigTimeout_EPS" SG_ 284 VEH_SPEED 210;
BA_ "GenSigTimeout_IC" SG_ 284 VEH_SPEED 210;
BA_ "GenSigTimeout_CBC" SG_ 284 VEH_SPEED 110;
BA_ "GenSigTimeout_RF_HUB" SG_ 284 VEH_SPEED 210;
BA_ "GenSigStartValue" SG_ 284 VEH_SPEED 65535;
BA_ "FlexKomSigStartValue" SG_ 284 VEH_SPEED "0FFF0FFFFFFF00FFh";
BA_ "GenSigCycleTime" SG_ 284 VEH_SPEED 20;
BA_ "GenSigSNA" SG_ 284 MC_VEH_SPEED "0h";
BA_ "FlexKomIsMotorola" SG_ 284 MC_VEH_SPEED 1;
BA_ "FlexKomComment" SG_ 284 MC_VEH_SPEED "Vehicle Speed Packet";
BA_ "FlexKomSigName" SG_ 284 MC_VEH_SPEED "VEH_SPEED_PKT";
BA_ "FlexKomSigLaenge" SG_ 284 MC_VEH_SPEED 64;
BA_ "FlexKomSigStartPos" SG_ 284 MC_VEH_SPEED 7;
BA_ "FlexKomSID" SG_ 284 MC_VEH_SPEED 11;
BA_ "GenSigTimeout_ORC" SG_ 284 MC_VEH_SPEED 70;
BA_ "GenSigTimeout_ESM" SG_ 284 MC_VEH_SPEED 210;
BA_ "GenSigTimeout_EPS" SG_ 284 MC_VEH_SPEED 210;
BA_ "GenSigTimeout_IC" SG_ 284 MC_VEH_SPEED 210;
BA_ "GenSigTimeout_CBC" SG_ 284 MC_VEH_SPEED 110;
BA_ "FlexKomSigStartValue" SG_ 284 MC_VEH_SPEED "0FFF0FFFFFFF00FFh";
BA_ "GenSigCycleTime" SG_ 284 MC_VEH_SPEED 20;
BA_ "GenSigSNA" SG_ 284 CRC_VEH_SPEED "FFh";
BA_ "FlexKomIsMotorola" SG_ 284 CRC_VEH_SPEED 1;
BA_ "FlexKomComment" SG_ 284 CRC_VEH_SPEED "Vehicle Speed Packet";
BA_ "FlexKomSigName" SG_ 284 CRC_VEH_SPEED "VEH_SPEED_PKT";
BA_ "FlexKomSigLaenge" SG_ 284 CRC_VEH_SPEED 64;
BA_ "FlexKomSigStartPos" SG_ 284 CRC_VEH_SPEED 7;
BA_ "FlexKomSID" SG_ 284 CRC_VEH_SPEED 11;
BA_ "GenSigTimeout_ORC" SG_ 284 CRC_VEH_SPEED 70;
BA_ "GenSigTimeout_ESM" SG_ 284 CRC_VEH_SPEED 210;
BA_ "GenSigTimeout_EPS" SG_ 284 CRC_VEH_SPEED 210;
BA_ "GenSigTimeout_IC" SG_ 284 CRC_VEH_SPEED 210;
BA_ "GenSigTimeout_CBC" SG_ 284 CRC_VEH_SPEED 110;
BA_ "GenSigStartValue" SG_ 284 CRC_VEH_SPEED 255;
BA_ "FlexKomSigStartValue" SG_ 284 CRC_VEH_SPEED "0FFF0FFFFFFF00FFh";
BA_ "GenSigCycleTime" SG_ 284 CRC_VEH_SPEED 20;
BA_ "GenSigSNA" SG_ 284 BrkTrq_D "FFFh";
BA_ "FlexKomIsMotorola" SG_ 284 BrkTrq_D 1;
BA_ "FlexKomComment" SG_ 284 BrkTrq_D "Vehicle Speed Packet";
BA_ "FlexKomSigName" SG_ 284 BrkTrq_D "VEH_SPEED_PKT";
BA_ "FlexKomSigLaenge" SG_ 284 BrkTrq_D 64;
BA_ "FlexKomSigStartPos" SG_ 284 BrkTrq_D 7;
BA_ "FlexKomSID" SG_ 284 BrkTrq_D 11;
BA_ "GenSigStartValue" SG_ 284 BrkTrq_D 4095;
BA_ "FlexKomSigStartValue" SG_ 284 BrkTrq_D "0FFF0FFFFFFF00FFh";
BA_ "GenSigCycleTime" SG_ 284 BrkTrq_D 20;
BA_ "GenSigSNA" SG_ 284 BrkTrq "FFFh";
BA_ "FlexKomIsMotorola" SG_ 284 BrkTrq 1;
BA_ "FlexKomComment" SG_ 284 BrkTrq "Vehicle Speed Packet";
BA_ "FlexKomSigName" SG_ 284 BrkTrq "VEH_SPEED_PKT";
BA_ "FlexKomSigLaenge" SG_ 284 BrkTrq 64;
BA_ "FlexKomSigStartPos" SG_ 284 BrkTrq 7;
BA_ "FlexKomSID" SG_ 284 BrkTrq 11;
BA_ "GenSigTimeout_CBC" SG_ 284 BrkTrq 210;
BA_ "GenSigStartValue" SG_ 284 BrkTrq 4095;
BA_ "FlexKomSigStartValue" SG_ 284 BrkTrq "0FFF0FFFFFFF00FFh";
BA_ "GenSigCycleTime" SG_ 284 BrkTrq 20;
BA_ "GenMsgStartValue" BO_ 280 "9FFF1FFF1FFF00FFh";
BA_ "GenMsgNrOfRepetitions" BO_ 280 2;
BA_ "GenMsgDelayTime" BO_ 280 20;
BA_ "GenMsgCycleTime" BO_ 280 10;
BA_ "GenSigSNA" SG_ 280 StartRelayBCMCmd "0h";
BA_ "FlexKomIsMotorola" SG_ 280 StartRelayBCMCmd 1;
BA_ "FlexKomComment" SG_ 280 StartRelayBCMCmd "ECM_ENG_TRQ packet";
BA_ "FlexKomSigName" SG_ 280 StartRelayBCMCmd "ECM_ENG_TRQ_Pkt";
BA_ "FlexKomSigLaenge" SG_ 280 StartRelayBCMCmd 64;
BA_ "FlexKomSigStartPos" SG_ 280 StartRelayBCMCmd 7;
BA_ "FlexKomSID" SG_ 280 StartRelayBCMCmd 1853;
BA_ "FlexKomSigStartValue" SG_ 280 StartRelayBCMCmd "9FFF1FFF1FFF00FFh";
BA_ "GenSigCycleTime" SG_ 280 StartRelayBCMCmd 10;
BA_ "GenSigSNA" SG_ 280 MC_ECM_ENG_TRQ "0h";
BA_ "FlexKomIsMotorola" SG_ 280 MC_ECM_ENG_TRQ 1;
BA_ "FlexKomComment" SG_ 280 MC_ECM_ENG_TRQ "ECM_ENG_TRQ packet";
BA_ "FlexKomSigName" SG_ 280 MC_ECM_ENG_TRQ "ECM_ENG_TRQ_Pkt";
BA_ "FlexKomSigLaenge" SG_ 280 MC_ECM_ENG_TRQ 64;
BA_ "FlexKomSigStartPos" SG_ 280 MC_ECM_ENG_TRQ 7;
BA_ "FlexKomSID" SG_ 280 MC_ECM_ENG_TRQ 1853;
BA_ "FlexKomSigStartValue" SG_ 280 MC_ECM_ENG_TRQ "9FFF1FFF1FFF00FFh";
BA_ "GenSigCycleTime" SG_ 280 MC_ECM_ENG_TRQ 10;
BA_ "GenSigSNA" SG_ 280 CRC_ECM_ENG_TRQ "FFh";
BA_ "FlexKomIsMotorola" SG_ 280 CRC_ECM_ENG_TRQ 1;
BA_ "FlexKomComment" SG_ 280 CRC_ECM_ENG_TRQ "ECM_ENG_TRQ packet";
BA_ "FlexKomSigName" SG_ 280 CRC_ECM_ENG_TRQ "ECM_ENG_TRQ_Pkt";
BA_ "FlexKomSigLaenge" SG_ 280 CRC_ECM_ENG_TRQ 64;
BA_ "FlexKomSigStartPos" SG_ 280 CRC_ECM_ENG_TRQ 7;
BA_ "FlexKomSID" SG_ 280 CRC_ECM_ENG_TRQ 1853;
BA_ "GenSigStartValue" SG_ 280 CRC_ECM_ENG_TRQ 255;
BA_ "FlexKomSigStartValue" SG_ 280 CRC_ECM_ENG_TRQ "9FFF1FFF1FFF00FFh";
BA_ "GenSigCycleTime" SG_ 280 CRC_ECM_ENG_TRQ 10;
BA_ "GenSigSNA" SG_ 280 ANL_LFT "0h";
BA_ "FlexKomIsMotorola" SG_ 280 ANL_LFT 1;
BA_ "FlexKomComment" SG_ 280 ANL_LFT "ECM_ENG_TRQ packet";
BA_ "FlexKomSigName" SG_ 280 ANL_LFT "ECM_ENG_TRQ_Pkt";
BA_ "FlexKomSigLaenge" SG_ 280 ANL_LFT 64;
BA_ "FlexKomSigStartPos" SG_ 280 ANL_LFT 7;
BA_ "FlexKomSID" SG_ 280 ANL_LFT 1853;
BA_ "GenSigTimeout_CBC" SG_ 280 ANL_LFT 105;
BA_ "FlexKomSigStartValue" SG_ 280 ANL_LFT "9FFF1FFF1FFF00FFh";
BA_ "GenSigCycleTime" SG_ 280 ANL_LFT 10;
BA_ "GenMsgStartValue" BO_ 274 "0000h";
BA_ "GenMsgNrOfRepetitions" BO_ 274 2;
BA_ "GenMsgDelayTime" BO_ 274 20;
BA_ "GenMsgCycleTime" BO_ 274 20;
BA_ "GenSigSNA" SG_ 274 TeenKeyPrsnt "0h";
BA_ "FlexKomIsMotorola" SG_ 274 TeenKeyPrsnt 1;
BA_ "FlexKomComment" SG_ 274 TeenKeyPrsnt "Vehicle start packet";
BA_ "FlexKomSigName" SG_ 274 TeenKeyPrsnt "VehStart_PKT";
BA_ "FlexKomSigLaenge" SG_ 274 TeenKeyPrsnt 16;
BA_ "FlexKomSigStartPos" SG_ 274 TeenKeyPrsnt 7;
BA_ "FlexKomSID" SG_ 274 TeenKeyPrsnt 880;
BA_ "GenSigTimeout_ETM" SG_ 274 TeenKeyPrsnt 210;
BA_ "FlexKomSigStartValue" SG_ 274 TeenKeyPrsnt "0000h";
BA_ "GenSigCycleTime" SG_ 274 TeenKeyPrsnt 20;
BA_ "GenSigSNA" SG_ 274 StTyp "7h";
BA_ "FlexKomIsMotorola" SG_ 274 StTyp 1;
BA_ "FlexKomComment" SG_ 274 StTyp "Vehicle start packet";
BA_ "FlexKomSigName" SG_ 274 StTyp "VehStart_PKT";
BA_ "FlexKomSigLaenge" SG_ 274 StTyp 16;
BA_ "FlexKomSigStartPos" SG_ 274 StTyp 7;
BA_ "FlexKomSID" SG_ 274 StTyp 880;
BA_ "GenSigTimeout_ORC" SG_ 274 StTyp 70;
BA_ "GenSigTimeout_IC" SG_ 274 StTyp 210;
BA_ "FlexKomSigStartValue" SG_ 274 StTyp "0000h";
BA_ "GenSigCycleTime" SG_ 274 StTyp 20;
BA_ "GenSigSNA" SG_ 274 StartRelayBCMSts "0h";
BA_ "FlexKomIsMotorola" SG_ 274 StartRelayBCMSts 1;
BA_ "FlexKomComment" SG_ 274 StartRelayBCMSts "CBC starter relay status; [1] = ON";
BA_ "FlexKomSigName" SG_ 274 StartRelayBCMSts "StartRelayBCMSts";
BA_ "FlexKomSigLaenge" SG_ 274 StartRelayBCMSts 1;
BA_ "FlexKomSigStartPos" SG_ 274 StartRelayBCMSts 13;
BA_ "FlexKomSID" SG_ 274 StartRelayBCMSts 1526;
BA_ "FlexKomSigStartValue" SG_ 274 StartRelayBCMSts "00h";
BA_ "GenSigCycleTime" SG_ 274 StartRelayBCMSts 20;
BA_ "GenSigSNA" SG_ 274 StartRelayBCMFault "0h";
BA_ "FlexKomIsMotorola" SG_ 274 StartRelayBCMFault 1;
BA_ "FlexKomComment" SG_ 274 StartRelayBCMFault "CBC starter relay fault detected";
BA_ "FlexKomSigName" SG_ 274 StartRelayBCMFault "StartRelayBCMFault";
BA_ "FlexKomSigLaenge" SG_ 274 StartRelayBCMFault 1;
BA_ "FlexKomSigStartPos" SG_ 274 StartRelayBCMFault 14;
BA_ "FlexKomSID" SG_ 274 StartRelayBCMFault 1573;
BA_ "GenSigTimeout_ORC" SG_ 274 StartRelayBCMFault 70;
BA_ "FlexKomSigStartValue" SG_ 274 StartRelayBCMFault "00h";
BA_ "GenSigCycleTime" SG_ 274 StartRelayBCMFault 20;
BA_ "GenSigSNA" SG_ 274 RemStActv "0h";
BA_ "FlexKomIsMotorola" SG_ 274 RemStActv 1;
BA_ "FlexKomComment" SG_ 274 RemStActv "Vehicle start packet";
BA_ "FlexKomSigName" SG_ 274 RemStActv "VehStart_PKT";
BA_ "FlexKomSigLaenge" SG_ 274 RemStActv 16;
BA_ "FlexKomSigStartPos" SG_ 274 RemStActv 7;
BA_ "FlexKomSID" SG_ 274 RemStActv 880;
BA_ "GenSigTimeout_ORC" SG_ 274 RemStActv 70;
BA_ "GenSigTimeout_ESM" SG_ 274 RemStActv 310;
BA_ "GenSigTimeout_IC" SG_ 274 RemStActv 210;
BA_ "FlexKomSigStartValue" SG_ 274 RemStActv "0000h";
BA_ "GenSigCycleTime" SG_ 274 RemStActv 20;
BA_ "GenSigSNA" SG_ 274 KeyInIgn "3h";
BA_ "FlexKomIsMotorola" SG_ 274 KeyInIgn 1;
BA_ "FlexKomComment" SG_ 274 KeyInIgn "Vehicle start packet";
BA_ "FlexKomSigName" SG_ 274 KeyInIgn "VehStart_PKT";
BA_ "FlexKomSigLaenge" SG_ 274 KeyInIgn 16;
BA_ "FlexKomSigStartPos" SG_ 274 KeyInIgn 7;
BA_ "FlexKomSID" SG_ 274 KeyInIgn 880;
BA_ "GenSigTimeout_ORC" SG_ 274 KeyInIgn 70;
BA_ "GenSigTimeout_IC" SG_ 274 KeyInIgn 210;
BA_ "FlexKomSigStartValue" SG_ 274 KeyInIgn "0000h";
BA_ "GenSigCycleTime" SG_ 274 KeyInIgn 20;
BA_ "GenSigSNA" SG_ 274 CmdIgnStat "7h";
BA_ "FlexKomIsMotorola" SG_ 274 CmdIgnStat 1;
BA_ "FlexKomComment" SG_ 274 CmdIgnStat "Vehicle start packet";
BA_ "FlexKomSigName" SG_ 274 CmdIgnStat "VehStart_PKT";
BA_ "FlexKomSigLaenge" SG_ 274 CmdIgnStat 16;
BA_ "FlexKomSigStartPos" SG_ 274 CmdIgnStat 7;
BA_ "FlexKomSID" SG_ 274 CmdIgnStat 880;
BA_ "GenSigTimeout_ORC" SG_ 274 CmdIgnStat 70;
BA_ "GenSigTimeout_ESM" SG_ 274 CmdIgnStat 310;
BA_ "GenSigTimeout_SCCM" SG_ 274 CmdIgnStat 210;
BA_ "GenSigTimeout_EPS" SG_ 274 CmdIgnStat 210;
BA_ "GenSigTimeout_PTS" SG_ 274 CmdIgnStat 210;
BA_ "GenSigTimeout_IC" SG_ 274 CmdIgnStat 210;
BA_ "FlexKomSigStartValue" SG_ 274 CmdIgnStat "0000h";
BA_ "GenSigCycleTime" SG_ 274 CmdIgnStat 20;
BA_ "GenMsgStartValue" BO_ 268 "00000000FF0000FFh";
BA_ "GenMsgNrOfRepetitions" BO_ 268 2;
BA_ "GenMsgDelayTime" BO_ 268 20;
BA_ "GenMsgCycleTime" BO_ 268 20;
BA_ "GenSigSNA" SG_ 268 PrefillActive "0h";
BA_ "FlexKomIsMotorola" SG_ 268 PrefillActive 1;
BA_ "FlexKomComment" SG_ 268 PrefillActive "Engine torque request from ESC";
BA_ "FlexKomSigName" SG_ 268 PrefillActive "Eng_Trq_Rq";
BA_ "FlexKomSigLaenge" SG_ 268 PrefillActive 64;
BA_ "FlexKomSigStartPos" SG_ 268 PrefillActive 7;
BA_ "FlexKomSID" SG_ 268 PrefillActive 1;
BA_ "FlexKomSigStartValue" SG_ 268 PrefillActive "00000000FF0000FFh";
BA_ "GenSigCycleTime" SG_ 268 PrefillActive 20;
BA_ "GenSigSNA" SG_ 268 MC_ENG_RQ_ESC "0h";
BA_ "FlexKomIsMotorola" SG_ 268 MC_ENG_RQ_ESC 1;
BA_ "FlexKomComment" SG_ 268 MC_ENG_RQ_ESC "Engine torque request from ESC";
BA_ "FlexKomSigName" SG_ 268 MC_ENG_RQ_ESC "Eng_Trq_Rq";
BA_ "FlexKomSigLaenge" SG_ 268 MC_ENG_RQ_ESC 64;
BA_ "FlexKomSigStartPos" SG_ 268 MC_ENG_RQ_ESC 7;
BA_ "FlexKomSID" SG_ 268 MC_ENG_RQ_ESC 1;
BA_ "FlexKomSigStartValue" SG_ 268 MC_ENG_RQ_ESC "00000000FF0000FFh";
BA_ "GenSigCycleTime" SG_ 268 MC_ENG_RQ_ESC 20;
BA_ "GenSigSNA" SG_ 268 EngTrqMin_Rq_ESC "0h";
BA_ "FlexKomIsMotorola" SG_ 268 EngTrqMin_Rq_ESC 1;
BA_ "FlexKomComment" SG_ 268 EngTrqMin_Rq_ESC "Engine torque request from ESC";
BA_ "FlexKomSigName" SG_ 268 EngTrqMin_Rq_ESC "Eng_Trq_Rq";
BA_ "FlexKomSigLaenge" SG_ 268 EngTrqMin_Rq_ESC 64;
BA_ "FlexKomSigStartPos" SG_ 268 EngTrqMin_Rq_ESC 7;
BA_ "FlexKomSID" SG_ 268 EngTrqMin_Rq_ESC 1;
BA_ "FlexKomSigStartValue" SG_ 268 EngTrqMin_Rq_ESC "00000000FF0000FFh";
BA_ "GenSigCycleTime" SG_ 268 EngTrqMin_Rq_ESC 20;
BA_ "GenSigSNA" SG_ 268 EngTrqMax_Rq_ESC "0h";
BA_ "FlexKomIsMotorola" SG_ 268 EngTrqMax_Rq_ESC 1;
BA_ "FlexKomComment" SG_ 268 EngTrqMax_Rq_ESC "Engine torque request from ESC";
BA_ "FlexKomSigName" SG_ 268 EngTrqMax_Rq_ESC "Eng_Trq_Rq";
BA_ "FlexKomSigLaenge" SG_ 268 EngTrqMax_Rq_ESC 64;
BA_ "FlexKomSigStartPos" SG_ 268 EngTrqMax_Rq_ESC 7;
BA_ "FlexKomSID" SG_ 268 EngTrqMax_Rq_ESC 1;
BA_ "FlexKomSigStartValue" SG_ 268 EngTrqMax_Rq_ESC "00000000FF0000FFh";
BA_ "GenSigCycleTime" SG_ 268 EngTrqMax_Rq_ESC 20;
BA_ "GenSigSNA" SG_ 268 EngTrq_Rq_ESC "1FFFh";
BA_ "FlexKomIsMotorola" SG_ 268 EngTrq_Rq_ESC 1;
BA_ "FlexKomComment" SG_ 268 EngTrq_Rq_ESC "Engine torque request from ESC";
BA_ "FlexKomSigName" SG_ 268 EngTrq_Rq_ESC "Eng_Trq_Rq";
BA_ "FlexKomSigLaenge" SG_ 268 EngTrq_Rq_ESC 64;
BA_ "FlexKomSigStartPos" SG_ 268 EngTrq_Rq_ESC 7;
BA_ "FlexKomSID" SG_ 268 EngTrq_Rq_ESC 1;
BA_ "GenSigTimeout_ETM" SG_ 268 EngTrq_Rq_ESC 210;
BA_ "FlexKomSigStartValue" SG_ 268 EngTrq_Rq_ESC "00000000FF0000FFh";
BA_ "GenSigCycleTime" SG_ 268 EngTrq_Rq_ESC 20;
BA_ "GenSigSNA" SG_ 268 DAS_RqActv "7h";
BA_ "FlexKomIsMotorola" SG_ 268 DAS_RqActv 1;
BA_ "FlexKomComment" SG_ 268 DAS_RqActv "Engine torque request from ESC";
BA_ "FlexKomSigName" SG_ 268 DAS_RqActv "Eng_Trq_Rq";
BA_ "FlexKomSigLaenge" SG_ 268 DAS_RqActv 64;
BA_ "FlexKomSigStartPos" SG_ 268 DAS_RqActv 7;
BA_ "FlexKomSID" SG_ 268 DAS_RqActv 1;
BA_ "GenSigTimeout_ORC" SG_ 268 DAS_RqActv 70;
BA_ "FlexKomSigStartValue" SG_ 268 DAS_RqActv "00000000FF0000FFh";
BA_ "GenSigCycleTime" SG_ 268 DAS_RqActv 20;
BA_ "GenSigSNA" SG_ 268 DAS_Enbl_Rq "0h";
BA_ "FlexKomIsMotorola" SG_ 268 DAS_Enbl_Rq 1;
BA_ "FlexKomComment" SG_ 268 DAS_Enbl_Rq "Engine torque request from ESC";
BA_ "FlexKomSigName" SG_ 268 DAS_Enbl_Rq "Eng_Trq_Rq";
BA_ "FlexKomSigLaenge" SG_ 268 DAS_Enbl_Rq 64;
BA_ "FlexKomSigStartPos" SG_ 268 DAS_Enbl_Rq 7;
BA_ "FlexKomSID" SG_ 268 DAS_Enbl_Rq 1;
BA_ "GenSigTimeout_ORC" SG_ 268 DAS_Enbl_Rq 70;
BA_ "FlexKomSigStartValue" SG_ 268 DAS_Enbl_Rq "00000000FF0000FFh";
BA_ "GenSigCycleTime" SG_ 268 DAS_Enbl_Rq 20;
BA_ "GenSigSNA" SG_ 268 CRC_ENG_RQ_ESC "FFh";
BA_ "FlexKomIsMotorola" SG_ 268 CRC_ENG_RQ_ESC 1;
BA_ "FlexKomComment" SG_ 268 CRC_ENG_RQ_ESC "Engine torque request from ESC";
BA_ "FlexKomSigName" SG_ 268 CRC_ENG_RQ_ESC "Eng_Trq_Rq";
BA_ "FlexKomSigLaenge" SG_ 268 CRC_ENG_RQ_ESC 64;
BA_ "FlexKomSigStartPos" SG_ 268 CRC_ENG_RQ_ESC 7;
BA_ "FlexKomSID" SG_ 268 CRC_ENG_RQ_ESC 1;
BA_ "GenSigStartValue" SG_ 268 CRC_ENG_RQ_ESC 255;
BA_ "FlexKomSigStartValue" SG_ 268 CRC_ENG_RQ_ESC "00000000FF0000FFh";
BA_ "GenSigCycleTime" SG_ 268 CRC_ENG_RQ_ESC 20;
BA_ "GenSigSNA" SG_ 268 Brk_Jrk_Rsp "0h";
BA_ "FlexKomIsMotorola" SG_ 268 Brk_Jrk_Rsp 1;
BA_ "FlexKomComment" SG_ 268 Brk_Jrk_Rsp "Engine torque request from ESC";
BA_ "FlexKomSigName" SG_ 268 Brk_Jrk_Rsp "Eng_Trq_Rq";
BA_ "FlexKomSigLaenge" SG_ 268 Brk_Jrk_Rsp 64;
BA_ "FlexKomSigStartPos" SG_ 268 Brk_Jrk_Rsp 7;
BA_ "FlexKomSID" SG_ 268 Brk_Jrk_Rsp 1;
BA_ "GenSigTimeout_ORC" SG_ 268 Brk_Jrk_Rsp 70;
BA_ "FlexKomSigStartValue" SG_ 268 Brk_Jrk_Rsp "00000000FF0000FFh";
BA_ "GenSigCycleTime" SG_ 268 Brk_Jrk_Rsp 20;
BA_ "GenSigSNA" SG_ 268 ASRActive "0h";
BA_ "FlexKomIsMotorola" SG_ 268 ASRActive 1;
BA_ "FlexKomComment" SG_ 268 ASRActive "Engine torque request from ESC";
BA_ "FlexKomSigName" SG_ 268 ASRActive "Eng_Trq_Rq";
BA_ "FlexKomSigLaenge" SG_ 268 ASRActive 64;
BA_ "FlexKomSigStartPos" SG_ 268 ASRActive 7;
BA_ "FlexKomSID" SG_ 268 ASRActive 1;
BA_ "FlexKomSigStartValue" SG_ 268 ASRActive "00000000FF0000FFh";
BA_ "GenSigCycleTime" SG_ 268 ASRActive 20;
BA_ "GenMsgStartValue" BO_ 264 "FFFF1FFF1FFF00FFh";
BA_ "GenMsgNrOfRepetitions" BO_ 264 2;
BA_ "GenMsgDelayTime" BO_ 264 20;
BA_ "GenMsgCycleTime" BO_ 264 10;
BA_ "GenSigSNA" SG_ 264 MC_ECM_A1 "0h";
BA_ "FlexKomIsMotorola" SG_ 264 MC_ECM_A1 1;
BA_ "FlexKomComment" SG_ 264 MC_ECM_A1 "ECM_A1 Packet";
BA_ "FlexKomSigName" SG_ 264 MC_ECM_A1 "ECM_A1_PKT";
BA_ "FlexKomSigLaenge" SG_ 264 MC_ECM_A1 64;
BA_ "FlexKomSigStartPos" SG_ 264 MC_ECM_A1 7;
BA_ "FlexKomSID" SG_ 264 MC_ECM_A1 446;
BA_ "FlexKomSigStartValue" SG_ 264 MC_ECM_A1 "FFFF1FFF1FFF00FFh";
BA_ "GenSigCycleTime" SG_ 264 MC_ECM_A1 10;
BA_ "GenSigSNA" SG_ 264 EngRPM "FFFFh";
BA_ "FlexKomIsMotorola" SG_ 264 EngRPM 1;
BA_ "FlexKomComment" SG_ 264 EngRPM "ECM_A1 Packet";
BA_ "FlexKomSigName" SG_ 264 EngRPM "ECM_A1_PKT";
BA_ "FlexKomSigLaenge" SG_ 264 EngRPM 64;
BA_ "FlexKomSigStartPos" SG_ 264 EngRPM 7;
BA_ "FlexKomSID" SG_ 264 EngRPM 446;
BA_ "GenSigTimeout_ORC" SG_ 264 EngRPM 35;
BA_ "GenSigTimeout_EPS" SG_ 264 EngRPM 105;
BA_ "GenSigTimeout_IC" SG_ 264 EngRPM 105;
BA_ "GenSigTimeout_CBC" SG_ 264 EngRPM 105;
BA_ "GenSigStartValue" SG_ 264 EngRPM 65535;
BA_ "FlexKomSigStartValue" SG_ 264 EngRPM "FFFF1FFF1FFF00FFh";
BA_ "GenSigCycleTime" SG_ 264 EngRPM 10;
BA_ "GenSigSNA" SG_ 264 ECM_IMMO_STAT_CANC "3h";
BA_ "FlexKomIsMotorola" SG_ 264 ECM_IMMO_STAT_CANC 1;
BA_ "FlexKomComment" SG_ 264 ECM_IMMO_STAT_CANC "ECM_A1 Packet";
BA_ "FlexKomSigName" SG_ 264 ECM_IMMO_STAT_CANC "ECM_A1_PKT";
BA_ "FlexKomSigLaenge" SG_ 264 ECM_IMMO_STAT_CANC 64;
BA_ "FlexKomSigStartPos" SG_ 264 ECM_IMMO_STAT_CANC 7;
BA_ "FlexKomSID" SG_ 264 ECM_IMMO_STAT_CANC 446;
BA_ "GenSigTimeout_CBC" SG_ 264 ECM_IMMO_STAT_CANC 105;
BA_ "FlexKomSigStartValue" SG_ 264 ECM_IMMO_STAT_CANC "FFFF1FFF1FFF00FFh";
BA_ "GenSigCycleTime" SG_ 264 ECM_IMMO_STAT_CANC 10;
BA_ "GenSigSNA" SG_ 264 CRC_ECM_A1 "FFh";
BA_ "FlexKomIsMotorola" SG_ 264 CRC_ECM_A1 1;
BA_ "FlexKomComment" SG_ 264 CRC_ECM_A1 "ECM_A1 Packet";
BA_ "FlexKomSigName" SG_ 264 CRC_ECM_A1 "ECM_A1_PKT";
BA_ "FlexKomSigLaenge" SG_ 264 CRC_ECM_A1 64;
BA_ "FlexKomSigStartPos" SG_ 264 CRC_ECM_A1 7;
BA_ "FlexKomSID" SG_ 264 CRC_ECM_A1 446;
BA_ "GenSigStartValue" SG_ 264 CRC_ECM_A1 255;
BA_ "FlexKomSigStartValue" SG_ 264 CRC_ECM_A1 "FFFF1FFF1FFF00FFh";
BA_ "GenSigCycleTime" SG_ 264 CRC_ECM_A1 10;
BA_ "GenMsgStartValue" BO_ 258 "3FFF3FFF030000FFh";
BA_ "GenMsgNrOfRepetitions" BO_ 258 2;
BA_ "GenMsgDelayTime" BO_ 258 20;
BA_ "GenMsgCycleTime" BO_ 258 10;
BA_ "GenSigSNA" SG_ 258 VLRW "3FFFh";
BA_ "FlexKomIsMotorola" SG_ 258 VLRW 1;
BA_ "FlexKomComment" SG_ 258 VLRW "Steering wheel angle state";
BA_ "FlexKomSigName" SG_ 258 VLRW "LRW_ST";
BA_ "FlexKomSigLaenge" SG_ 258 VLRW 64;
BA_ "FlexKomSigStartPos" SG_ 258 VLRW 7;
BA_ "FlexKomSID" SG_ 258 VLRW 418;
BA_ "GenSigTimeout_ETM" SG_ 258 VLRW 105;
BA_ "GenSigTimeout_ORC" SG_ 258 VLRW 35;
BA_ "GenSigTimeout_EPS" SG_ 258 VLRW 105;
BA_ "GenSigStartValue" SG_ 258 VLRW 16383;
BA_ "FlexKomSigStartValue" SG_ 258 VLRW "3FFF3FFF030000FFh";
BA_ "GenSigCycleTime" SG_ 258 VLRW 10;
BA_ "GenSigSNA" SG_ 258 MC_STW_Angle_STAT "0h";
BA_ "FlexKomIsMotorola" SG_ 258 MC_STW_Angle_STAT 1;
BA_ "FlexKomComment" SG_ 258 MC_STW_Angle_STAT "Steering wheel angle state";
BA_ "FlexKomSigName" SG_ 258 MC_STW_Angle_STAT "LRW_ST";
BA_ "FlexKomSigLaenge" SG_ 258 MC_STW_Angle_STAT 64;
BA_ "FlexKomSigStartPos" SG_ 258 MC_STW_Angle_STAT 7;
BA_ "FlexKomSID" SG_ 258 MC_STW_Angle_STAT 418;
BA_ "GenSigTimeout_ETM" SG_ 258 MC_STW_Angle_STAT 105;
BA_ "GenSigTimeout_ORC" SG_ 258 MC_STW_Angle_STAT 35;
BA_ "FlexKomSigStartValue" SG_ 258 MC_STW_Angle_STAT "3FFF3FFF030000FFh";
BA_ "GenSigCycleTime" SG_ 258 MC_STW_Angle_STAT 10;
BA_ "GenSigSNA" SG_ 258 LRWS_ST "3h";
BA_ "FlexKomIsMotorola" SG_ 258 LRWS_ST 1;
BA_ "FlexKomComment" SG_ 258 LRWS_ST "Steering wheel angle state";
BA_ "FlexKomSigName" SG_ 258 LRWS_ST "LRW_ST";
BA_ "FlexKomSigLaenge" SG_ 258 LRWS_ST 64;
BA_ "FlexKomSigStartPos" SG_ 258 LRWS_ST 7;
BA_ "FlexKomSID" SG_ 258 LRWS_ST 418;
BA_ "GenSigTimeout_ETM" SG_ 258 LRWS_ST 105;
BA_ "GenSigTimeout_ORC" SG_ 258 LRWS_ST 35;
BA_ "GenSigStartValue" SG_ 258 LRWS_ST 3;
BA_ "FlexKomSigStartValue" SG_ 258 LRWS_ST "3FFF3FFF030000FFh";
BA_ "GenSigCycleTime" SG_ 258 LRWS_ST 10;
BA_ "GenSigSNA" SG_ 258 LRW_RHP "0h";
BA_ "FlexKomIsMotorola" SG_ 258 LRW_RHP 1;
BA_ "FlexKomComment" SG_ 258 LRW_RHP "Steering wheel angle state";
BA_ "FlexKomSigName" SG_ 258 LRW_RHP "LRW_ST";
BA_ "FlexKomSigLaenge" SG_ 258 LRW_RHP 64;
BA_ "FlexKomSigStartPos" SG_ 258 LRW_RHP 7;
BA_ "FlexKomSID" SG_ 258 LRW_RHP 418;
BA_ "GenSigTimeout_ETM" SG_ 258 LRW_RHP 105;
BA_ "GenSigTimeout_EPS" SG_ 258 LRW_RHP 105;
BA_ "FlexKomSigStartValue" SG_ 258 LRW_RHP "3FFF3FFF030000FFh";
BA_ "GenSigCycleTime" SG_ 258 LRW_RHP 10;
BA_ "GenSigSNA" SG_ 258 LRW_PLRTY "0h";
BA_ "FlexKomIsMotorola" SG_ 258 LRW_PLRTY 1;
BA_ "FlexKomComment" SG_ 258 LRW_PLRTY "Steering wheel angle state";
BA_ "FlexKomSigName" SG_ 258 LRW_PLRTY "LRW_ST";
BA_ "FlexKomSigLaenge" SG_ 258 LRW_PLRTY 64;
BA_ "FlexKomSigStartPos" SG_ 258 LRW_PLRTY 7;
BA_ "FlexKomSID" SG_ 258 LRW_PLRTY 418;
BA_ "GenSigTimeout_ETM" SG_ 258 LRW_PLRTY 105;
BA_ "GenSigTimeout_ORC" SG_ 258 LRW_PLRTY 35;
BA_ "FlexKomSigStartValue" SG_ 258 LRW_PLRTY "3FFF3FFF030000FFh";
BA_ "GenSigCycleTime" SG_ 258 LRW_PLRTY 10;
BA_ "GenSigSNA" SG_ 258 LRW "3FFFh";
BA_ "FlexKomIsMotorola" SG_ 258 LRW 1;
BA_ "FlexKomComment" SG_ 258 LRW "Steering wheel angle state";
BA_ "FlexKomSigName" SG_ 258 LRW "LRW_ST";
BA_ "FlexKomSigLaenge" SG_ 258 LRW 64;
BA_ "FlexKomSigStartPos" SG_ 258 LRW 7;
BA_ "FlexKomSID" SG_ 258 LRW 418;
BA_ "GenSigTimeout_ORC" SG_ 258 LRW 35;
BA_ "GenSigTimeout_EPS" SG_ 258 LRW 105;
BA_ "GenSigTimeout_CBC" SG_ 258 LRW 105;
BA_ "GenSigStartValue" SG_ 258 LRW 16383;
BA_ "FlexKomSigStartValue" SG_ 258 LRW "3FFF3FFF030000FFh";
BA_ "GenSigCycleTime" SG_ 258 LRW 10;
BA_ "GenSigSNA" SG_ 258 CRC_STW_Angle_STAT "FFh";
BA_ "FlexKomIsMotorola" SG_ 258 CRC_STW_Angle_STAT 1;
BA_ "FlexKomComment" SG_ 258 CRC_STW_Angle_STAT "Steering wheel angle state";
BA_ "FlexKomSigName" SG_ 258 CRC_STW_Angle_STAT "LRW_ST";
BA_ "FlexKomSigLaenge" SG_ 258 CRC_STW_Angle_STAT 64;
BA_ "FlexKomSigStartPos" SG_ 258 CRC_STW_Angle_STAT 7;
BA_ "FlexKomSID" SG_ 258 CRC_STW_Angle_STAT 418;
BA_ "GenSigTimeout_ETM" SG_ 258 CRC_STW_Angle_STAT 105;
BA_ "GenSigTimeout_ORC" SG_ 258 CRC_STW_Angle_STAT 35;
BA_ "GenSigStartValue" SG_ 258 CRC_STW_Angle_STAT 255;
BA_ "FlexKomSigStartValue" SG_ 258 CRC_STW_Angle_STAT "3FFF3FFF030000FFh";
BA_ "GenSigCycleTime" SG_ 258 CRC_STW_Angle_STAT 10;
BA_ "GenMsgStartValue" BO_ 257 "0000000000h";
BA_ "GenMsgNrOfRepetitions" BO_ 257 2;
BA_ "GenMsgDelayTime" BO_ 257 20;
BA_ "GenMsgCycleTime" BO_ 257 100;
BA_ "GenSigSNA" SG_ 257 RAD_FAN1_STAT "FFh";
BA_ "FlexKomIsMotorola" SG_ 257 RAD_FAN1_STAT 1;
BA_ "FlexKomComment" SG_ 257 RAD_FAN1_STAT "Low speed or single radiator fan requested duty cy";
BA_ "FlexKomSigName" SG_ 257 RAD_FAN1_STAT "RAD_FAN1_STAT";
BA_ "FlexKomSigLaenge" SG_ 257 RAD_FAN1_STAT 8;
BA_ "FlexKomSigStartPos" SG_ 257 RAD_FAN1_STAT 39;
BA_ "FlexKomSID" SG_ 257 RAD_FAN1_STAT 1091;
BA_ "GenSigTimeout_ETM" SG_ 257 RAD_FAN1_STAT 1050;
BA_ "FlexKomSigStartValue" SG_ 257 RAD_FAN1_STAT "00h";
BA_ "GenSigCycleTime" SG_ 257 RAD_FAN1_STAT 100;
BA_ "GenSigSNA" SG_ 257 OBD_GnrlDenCond_Stat "0h";
BA_ "FlexKomIsMotorola" SG_ 257 OBD_GnrlDenCond_Stat 1;
BA_ "FlexKomComment" SG_ 257 OBD_GnrlDenCond_Stat "General denominator conditions are met [1].";
BA_ "FlexKomSigName" SG_ 257 OBD_GnrlDenCond_Stat "OBD_GnrlDenCond_Stat";
BA_ "FlexKomSigLaenge" SG_ 257 OBD_GnrlDenCond_Stat 1;
BA_ "FlexKomSigStartPos" SG_ 257 OBD_GnrlDenCond_Stat 5;
BA_ "FlexKomSID" SG_ 257 OBD_GnrlDenCond_Stat 1256;
BA_ "FlexKomSigStartValue" SG_ 257 OBD_GnrlDenCond_Stat "00h";
BA_ "GenSigCycleTime" SG_ 257 OBD_GnrlDenCond_Stat 100;
BA_ "GenSigSNA" SG_ 257 InpICC_Fail "0h";
BA_ "FlexKomIsMotorola" SG_ 257 InpICC_Fail 1;
BA_ "FlexKomComment" SG_ 257 InpICC_Fail "Inputs to the Ign Cycle Cntr are in a Pend or MIL ";
BA_ "FlexKomSigName" SG_ 257 InpICC_Fail "InpICC_Fail";
BA_ "FlexKomSigLaenge" SG_ 257 InpICC_Fail 1;
BA_ "FlexKomSigStartPos" SG_ 257 InpICC_Fail 2;
BA_ "FlexKomSID" SG_ 257 InpICC_Fail 1259;
BA_ "FlexKomSigStartValue" SG_ 257 InpICC_Fail "00h";
BA_ "GenSigCycleTime" SG_ 257 InpICC_Fail 100;
BA_ "GenSigSNA" SG_ 257 Inp_GD_Fail "0h";
BA_ "FlexKomIsMotorola" SG_ 257 Inp_GD_Fail 1;
BA_ "FlexKomComment" SG_ 257 Inp_GD_Fail "Inputs to the general denominator are in a pend or";
BA_ "FlexKomSigName" SG_ 257 Inp_GD_Fail "Inp_GD_Fail";
BA_ "FlexKomSigLaenge" SG_ 257 Inp_GD_Fail 1;
BA_ "FlexKomSigStartPos" SG_ 257 Inp_GD_Fail 1;
BA_ "FlexKomSID" SG_ 257 Inp_GD_Fail 1260;
BA_ "FlexKomSigStartValue" SG_ 257 Inp_GD_Fail "00h";
BA_ "GenSigCycleTime" SG_ 257 Inp_GD_Fail 100;
BA_ "GenSigSNA" SG_ 257 IgnCntrTrue "0h";
BA_ "FlexKomIsMotorola" SG_ 257 IgnCntrTrue 1;
BA_ "FlexKomComment" SG_ 257 IgnCntrTrue "Ignition cycle counter is true [1]";
BA_ "FlexKomSigName" SG_ 257 IgnCntrTrue "IgnCntrTrue";
BA_ "FlexKomSigLaenge" SG_ 257 IgnCntrTrue 1;
BA_ "FlexKomSigStartPos" SG_ 257 IgnCntrTrue 6;
BA_ "FlexKomSID" SG_ 257 IgnCntrTrue 1255;
BA_ "FlexKomSigStartValue" SG_ 257 IgnCntrTrue "00h";
BA_ "GenSigCycleTime" SG_ 257 IgnCntrTrue 100;
BA_ "GenSigSNA" SG_ 257 EngLoad_OBD "0h";
BA_ "FlexKomIsMotorola" SG_ 257 EngLoad_OBD 1;
BA_ "FlexKomComment" SG_ 257 EngLoad_OBD "Load value for OBD (ISO 15031-5.4 PID 4)";
BA_ "FlexKomSigName" SG_ 257 EngLoad_OBD "EngLoad_OBD";
BA_ "FlexKomSigLaenge" SG_ 257 EngLoad_OBD 8;
BA_ "FlexKomSigStartPos" SG_ 257 EngLoad_OBD 23;
BA_ "FlexKomSID" SG_ 257 EngLoad_OBD 1088;
BA_ "FlexKomSigStartValue" SG_ 257 EngLoad_OBD "00h";
BA_ "GenSigCycleTime" SG_ 257 EngLoad_OBD 100;
BA_ "GenSigSNA" SG_ 257 ENGINE_RESET "0h";
BA_ "FlexKomIsMotorola" SG_ 257 ENGINE_RESET 1;
BA_ "FlexKomComment" SG_ 257 ENGINE_RESET "ECM Immobilizer Status Packet";
BA_ "FlexKomSigName" SG_ 257 ENGINE_RESET "ECM_SKIM_STAT_PKT";
BA_ "FlexKomSigLaenge" SG_ 257 ENGINE_RESET 3;
BA_ "FlexKomSigStartPos" SG_ 257 ENGINE_RESET 10;
BA_ "FlexKomSID" SG_ 257 ENGINE_RESET 429;
BA_ "FlexKomSigStartValue" SG_ 257 ENGINE_RESET "00h";
BA_ "GenSigCycleTime" SG_ 257 ENGINE_RESET 100;
BA_ "GenSigSNA" SG_ 257 ECM_SKIM_STAT "3h";
BA_ "FlexKomIsMotorola" SG_ 257 ECM_SKIM_STAT 1;
BA_ "FlexKomComment" SG_ 257 ECM_SKIM_STAT "ECM Immobilizer Status Packet";
BA_ "FlexKomSigName" SG_ 257 ECM_SKIM_STAT "ECM_SKIM_STAT_PKT";
BA_ "FlexKomSigLaenge" SG_ 257 ECM_SKIM_STAT 3;
BA_ "FlexKomSigStartPos" SG_ 257 ECM_SKIM_STAT 10;
BA_ "FlexKomSID" SG_ 257 ECM_SKIM_STAT 429;
BA_ "FlexKomSigStartValue" SG_ 257 ECM_SKIM_STAT "00h";
BA_ "GenSigCycleTime" SG_ 257 ECM_SKIM_STAT 100;
BA_ "GenSigSNA" SG_ 257 CARB_Temp "0h";
BA_ "FlexKomIsMotorola" SG_ 257 CARB_Temp 1;
BA_ "FlexKomComment" SG_ 257 CARB_Temp "CARB warmup criteria is true [1]";
BA_ "FlexKomSigName" SG_ 257 CARB_Temp "CARB_Temp";
BA_ "FlexKomSigLaenge" SG_ 257 CARB_Temp 1;
BA_ "FlexKomSID" SG_ 257 CARB_Temp 1261;
BA_ "FlexKomSigStartValue" SG_ 257 CARB_Temp "00h";
BA_ "GenSigCycleTime" SG_ 257 CARB_Temp 100;
BA_ "GenSigSNA" SG_ 257 CARB_PERM "0h";
BA_ "FlexKomIsMotorola" SG_ 257 CARB_PERM 1;
BA_ "FlexKomComment" SG_ 257 CARB_PERM "CARB permanent fault code drive cycle";
BA_ "FlexKomSigName" SG_ 257 CARB_PERM "CARB_PERM";
BA_ "FlexKomSigLaenge" SG_ 257 CARB_PERM 1;
BA_ "FlexKomSigStartPos" SG_ 257 CARB_PERM 3;
BA_ "FlexKomSID" SG_ 257 CARB_PERM 1258;
BA_ "FlexKomSigStartValue" SG_ 257 CARB_PERM "00h";
BA_ "GenSigCycleTime" SG_ 257 CARB_PERM 100;
BA_ "GenSigSNA" SG_ 257 AccelPdlPosn_OBD "0h";
BA_ "FlexKomIsMotorola" SG_ 257 AccelPdlPosn_OBD 1;
BA_ "FlexKomComment" SG_ 257 AccelPdlPosn_OBD "Pedal value for OBD (ISO 15031-5.4 PID 49)";
BA_ "FlexKomSigName" SG_ 257 AccelPdlPosn_OBD "AccelPdlPosn_OBD";
BA_ "FlexKomSigLaenge" SG_ 257 AccelPdlPosn_OBD 8;
BA_ "FlexKomSigStartPos" SG_ 257 AccelPdlPosn_OBD 31;
BA_ "FlexKomSID" SG_ 257 AccelPdlPosn_OBD 1089;
BA_ "FlexKomSigStartValue" SG_ 257 AccelPdlPosn_OBD "00h";
BA_ "GenSigCycleTime" SG_ 257 AccelPdlPosn_OBD 100;
BA_ "GenMsgStartValue" BO_ 168 "0B830B830B8300FFh";
BA_ "GenMsgNrOfRepetitions" BO_ 168 2;
BA_ "GenMsgDelayTime" BO_ 168 20;
BA_ "GenMsgCycleTime" BO_ 168 10;
BA_ "GenSigSNA" SG_ 168 MC_0A8h "0h";
BA_ "FlexKomIsMotorola" SG_ 168 MC_0A8h 1;
BA_ "FlexKomComment" SG_ 168 MC_0A8h ".";
BA_ "FlexKomSigName" SG_ 168 MC_0A8h "Axle_Torque_Information";
BA_ "FlexKomSigLaenge" SG_ 168 MC_0A8h 64;
BA_ "FlexKomSigStartPos" SG_ 168 MC_0A8h 7;
BA_ "FlexKomSID" SG_ 168 MC_0A8h 2291;
BA_ "FlexKomSigStartValue" SG_ 168 MC_0A8h "0B830B830B8300FFh";
BA_ "GenSigCycleTime" SG_ 168 MC_0A8h 10;
BA_ "GenSigSNA" SG_ 168 DrvrIntndedAxleTorq "3FFFh";
BA_ "FlexKomIsMotorola" SG_ 168 DrvrIntndedAxleTorq 1;
BA_ "FlexKomComment" SG_ 168 DrvrIntndedAxleTorq ".";
BA_ "FlexKomSigName" SG_ 168 DrvrIntndedAxleTorq "Axle_Torque_Information";
BA_ "FlexKomSigLaenge" SG_ 168 DrvrIntndedAxleTorq 64;
BA_ "FlexKomSigStartPos" SG_ 168 DrvrIntndedAxleTorq 7;
BA_ "FlexKomSID" SG_ 168 DrvrIntndedAxleTorq 2291;
BA_ "GenSigStartValue" SG_ 168 DrvrIntndedAxleTorq 2947;
BA_ "FlexKomSigStartValue" SG_ 168 DrvrIntndedAxleTorq "0B830B830B8300FFh";
BA_ "GenSigCycleTime" SG_ 168 DrvrIntndedAxleTorq 10;
BA_ "GenSigSNA" SG_ 168 CRC_0A8h "FFh";
BA_ "FlexKomIsMotorola" SG_ 168 CRC_0A8h 1;
BA_ "FlexKomComment" SG_ 168 CRC_0A8h ".";
BA_ "FlexKomSigName" SG_ 168 CRC_0A8h "Axle_Torque_Information";
BA_ "FlexKomSigLaenge" SG_ 168 CRC_0A8h 64;
BA_ "FlexKomSigStartPos" SG_ 168 CRC_0A8h 7;
BA_ "FlexKomSID" SG_ 168 CRC_0A8h 2291;
BA_ "GenSigStartValue" SG_ 168 CRC_0A8h 255;
BA_ "FlexKomSigStartValue" SG_ 168 CRC_0A8h "0B830B830B8300FFh";
BA_ "GenSigCycleTime" SG_ 168 CRC_0A8h 10;
BA_ "GenMsgStartValue" BO_ 1083 "FFFFFFFF000000FFh";
BA_ "GenMsgNrOfRepetitions" BO_ 1083 2;
BA_ "GenMsgDelayTime" BO_ 1083 20;
BA_ "NWM-Botschaft" BO_ 1083 1;
BA_ "GenSigSNA" SG_ 1083 WakeupRsn_EBCM "FFh";
BA_ "RID" SG_ 1083 WakeupRsn_EBCM "(default)";
BA_ "FlexKomIsMotorola" SG_ 1083 WakeupRsn_EBCM 1;
BA_ "FlexKomSigLaenge" SG_ 1083 WakeupRsn_EBCM 24;
BA_ "FlexKomSigStartPos" SG_ 1083 WakeupRsn_EBCM 39;
BA_ "FlexKomComment" SG_ 1083 WakeupRsn_EBCM "Mode 2 of NM_Ud_Srv";
BA_ "FlexKomSigName" SG_ 1083 WakeupRsn_EBCM "Wakeup_EBCM";
BA_ "FlexKomSID" SG_ 1083 WakeupRsn_EBCM 2197;
BA_ "GenSigStartValue" SG_ 1083 WakeupRsn_EBCM 255;
BA_ "FlexKomSigStartValue" SG_ 1083 WakeupRsn_EBCM "FFFF00h";
BA_ "GenSigSNA" SG_ 1083 WakeupCnt_EBCM "FFh";
BA_ "FlexKomIsMotorola" SG_ 1083 WakeupCnt_EBCM 1;
BA_ "FlexKomSigLaenge" SG_ 1083 WakeupCnt_EBCM 24;
BA_ "FlexKomSigStartPos" SG_ 1083 WakeupCnt_EBCM 39;
BA_ "FlexKomComment" SG_ 1083 WakeupCnt_EBCM "Mode 2 of NM_Ud_Srv";
BA_ "FlexKomSigName" SG_ 1083 WakeupCnt_EBCM "Wakeup_EBCM";
BA_ "FlexKomSID" SG_ 1083 WakeupCnt_EBCM 2197;
BA_ "GenSigStartValue" SG_ 1083 WakeupCnt_EBCM 255;
BA_ "FlexKomSigStartValue" SG_ 1083 WakeupCnt_EBCM "FFFF00h";
BA_ "GenSigSNA" SG_ 1083 Nw_Id_EBCM "FFh";
BA_ "FlexKomIsMotorola" SG_ 1083 Nw_Id_EBCM 1;
BA_ "FlexKomSigLaenge" SG_ 1083 Nw_Id_EBCM 8;
BA_ "FlexKomSigStartPos" SG_ 1083 Nw_Id_EBCM 63;
BA_ "FlexKomComment" SG_ 1083 Nw_Id_EBCM "Network identification no.";
BA_ "FlexKomSigName" SG_ 1083 Nw_Id_EBCM "Nw_Id";
BA_ "FlexKomSID" SG_ 1083 Nw_Id_EBCM 535;
BA_ "GenSigStartValue" SG_ 1083 Nw_Id_EBCM 255;
BA_ "FlexKomSigStartValue" SG_ 1083 Nw_Id_EBCM "FFh";
BA_ "GenSigSNA" SG_ 1083 NM_Ud_Srv_EBCM "FFh";
BA_ "FlexKomIsMotorola" SG_ 1083 NM_Ud_Srv_EBCM 1;
BA_ "FlexKomSigLaenge" SG_ 1083 NM_Ud_Srv_EBCM 32;
BA_ "FlexKomSigStartPos" SG_ 1083 NM_Ud_Srv_EBCM 7;
BA_ "FlexKomComment" SG_ 1083 NM_Ud_Srv_EBCM "Network management state";
BA_ "FlexKomSigName" SG_ 1083 NM_Ud_Srv_EBCM "NM";
BA_ "FlexKomSID" SG_ 1083 NM_Ud_Srv_EBCM 472;
BA_ "GenSigStartValue" SG_ 1083 NM_Ud_Srv_EBCM 255;
BA_ "FlexKomSigStartValue" SG_ 1083 NM_Ud_Srv_EBCM "FFFFFFFFh";
BA_ "GenSigSNA" SG_ 1083 NM_Ud_Launch_EBCM "3Fh";
BA_ "FlexKomIsMotorola" SG_ 1083 NM_Ud_Launch_EBCM 1;
BA_ "FlexKomSigLaenge" SG_ 1083 NM_Ud_Launch_EBCM 32;
BA_ "FlexKomSigStartPos" SG_ 1083 NM_Ud_Launch_EBCM 7;
BA_ "FlexKomComment" SG_ 1083 NM_Ud_Launch_EBCM "Network management state";
BA_ "FlexKomSigName" SG_ 1083 NM_Ud_Launch_EBCM "NM";
BA_ "FlexKomSID" SG_ 1083 NM_Ud_Launch_EBCM 472;
BA_ "GenSigStartValue" SG_ 1083 NM_Ud_Launch_EBCM 63;
BA_ "FlexKomSigStartValue" SG_ 1083 NM_Ud_Launch_EBCM "FFFFFFFFh";
BA_ "GenSigSNA" SG_ 1083 NM_Successor_EBCM "FFh";
BA_ "FlexKomIsMotorola" SG_ 1083 NM_Successor_EBCM 1;
BA_ "FlexKomSigLaenge" SG_ 1083 NM_Successor_EBCM 32;
BA_ "FlexKomSigStartPos" SG_ 1083 NM_Successor_EBCM 7;
BA_ "FlexKomComment" SG_ 1083 NM_Successor_EBCM "Network management state";
BA_ "FlexKomSigName" SG_ 1083 NM_Successor_EBCM "NM";
BA_ "FlexKomSID" SG_ 1083 NM_Successor_EBCM 472;
BA_ "GenSigStartValue" SG_ 1083 NM_Successor_EBCM 255;
BA_ "FlexKomSigStartValue" SG_ 1083 NM_Successor_EBCM "FFFFFFFFh";
BA_ "GenSigSNA" SG_ 1083 NM_Sleep_Ind_EBCM "1h";
BA_ "FlexKomIsMotorola" SG_ 1083 NM_Sleep_Ind_EBCM 1;
BA_ "FlexKomSigLaenge" SG_ 1083 NM_Sleep_Ind_EBCM 32;
BA_ "FlexKomSigStartPos" SG_ 1083 NM_Sleep_Ind_EBCM 7;
BA_ "FlexKomComment" SG_ 1083 NM_Sleep_Ind_EBCM "Network management state";
BA_ "FlexKomSigName" SG_ 1083 NM_Sleep_Ind_EBCM "NM";
BA_ "FlexKomSID" SG_ 1083 NM_Sleep_Ind_EBCM 472;
BA_ "GenSigStartValue" SG_ 1083 NM_Sleep_Ind_EBCM 1;
BA_ "FlexKomSigStartValue" SG_ 1083 NM_Sleep_Ind_EBCM "FFFFFFFFh";
BA_ "GenSigSNA" SG_ 1083 NM_Sleep_Ack_EBCM "1h";
BA_ "FlexKomIsMotorola" SG_ 1083 NM_Sleep_Ack_EBCM 1;
BA_ "FlexKomSigLaenge" SG_ 1083 NM_Sleep_Ack_EBCM 32;
BA_ "FlexKomSigStartPos" SG_ 1083 NM_Sleep_Ack_EBCM 7;
BA_ "FlexKomComment" SG_ 1083 NM_Sleep_Ack_EBCM "Network management state";
BA_ "FlexKomSigName" SG_ 1083 NM_Sleep_Ack_EBCM "NM";
BA_ "FlexKomSID" SG_ 1083 NM_Sleep_Ack_EBCM 472;
BA_ "GenSigStartValue" SG_ 1083 NM_Sleep_Ack_EBCM 1;
BA_ "FlexKomSigStartValue" SG_ 1083 NM_Sleep_Ack_EBCM "FFFFFFFFh";
BA_ "GenSigSNA" SG_ 1083 NM_Mode_EBCM "FFh";
BA_ "FlexKomIsMotorola" SG_ 1083 NM_Mode_EBCM 1;
BA_ "FlexKomSigLaenge" SG_ 1083 NM_Mode_EBCM 32;
BA_ "FlexKomSigStartPos" SG_ 1083 NM_Mode_EBCM 7;
BA_ "FlexKomComment" SG_ 1083 NM_Mode_EBCM "Network management state";
BA_ "FlexKomSigName" SG_ 1083 NM_Mode_EBCM "NM";
BA_ "FlexKomSID" SG_ 1083 NM_Mode_EBCM 472;
BA_ "GenSigStartValue" SG_ 1083 NM_Mode_EBCM 255;
BA_ "FlexKomSigStartValue" SG_ 1083 NM_Mode_EBCM "FFFFFFFFh";
BA_ "GenSigSNA" SG_ 1083 Awake_NwSt_EBCM "0h";
BA_ "FlexKomIsMotorola" SG_ 1083 Awake_NwSt_EBCM 1;
BA_ "FlexKomSigLaenge" SG_ 1083 Awake_NwSt_EBCM 24;
BA_ "FlexKomSigStartPos" SG_ 1083 Awake_NwSt_EBCM 39;
BA_ "FlexKomComment" SG_ 1083 Awake_NwSt_EBCM "Mode 15 of NM_Ud_Srv";
BA_ "FlexKomSigName" SG_ 1083 Awake_NwSt_EBCM "Awake_EBCM";
BA_ "FlexKomSID" SG_ 1083 Awake_NwSt_EBCM 2196;
BA_ "FlexKomSigStartValue" SG_ 1083 Awake_NwSt_EBCM "000000h";
BA_ "GenSigSNA" SG_ 1083 Awake_Diag_Actv_EBCM "0h";
BA_ "FlexKomIsMotorola" SG_ 1083 Awake_Diag_Actv_EBCM 1;
BA_ "FlexKomSigLaenge" SG_ 1083 Awake_Diag_Actv_EBCM 24;
BA_ "FlexKomSigStartPos" SG_ 1083 Awake_Diag_Actv_EBCM 39;
BA_ "FlexKomComment" SG_ 1083 Awake_Diag_Actv_EBCM "Mode 15 of NM_Ud_Srv";
BA_ "FlexKomSigName" SG_ 1083 Awake_Diag_Actv_EBCM "Awake_EBCM";
BA_ "FlexKomSID" SG_ 1083 Awake_Diag_Actv_EBCM 2196;
BA_ "FlexKomSigStartValue" SG_ 1083 Awake_Diag_Actv_EBCM "000000h";
VAL_ 464 SRS_IndLmp_Rq 3 "SNA" 2 "BLINK" 1 "CONT" 0 "OFF" ;
VAL_ 464 PSG_SEATBELT 3 "SNA" 2 "SEATBELT_FAIL" 1 "PSG_SEATBELT_NOK" 0 "PSG_SEATBELT_OK" ;
VAL_ 464 PSG_ODS_STAT 3 "SNA" 2 "ODS_FAULT" 1 "ODS_STAT_OCC" 0 "ODS_STAT_NOCC" ;
VAL_ 464 DrvSbltUnFltr 7 "SNA" 3 "HIGH" 2 "LOW" 1 "UNBUCKLED" 0 "BUCKLED" ;
VAL_ 464 DRV_SEATBELT 3 "SNA" 2 "SEATBELT_FAIL" 1 "DRV_SEATBELT_NOK" 0 "DRV_SEATBELT_OK" ;
VAL_ 456 VTA_STAT 7 "SNA" 6 "VTA_ITM_Alarm" 5 "VTA_TAMP" 4 "VTA_LGT_HORN" 3 "VTA_LGT" 2 "VTA_ARM" 1 "VTA_PREARM" 0 "VTA_DISARM" ;
VAL_ 448 RFReq 7 "SNA" 5 "REQUESTOR_PE_HANDSFREE" 4 "REQUESTOR_UCONNECT" 3 "REQUESTOR_REMOTESTART" 2 "REQUESTOR_PE" 1 "REQUESTOR_RKE" 0 "REQUESTOR_DEFAULT" ;
VAL_ 448 RFFuncReq 31 "SNA" 26 "VTA_RQ" 25 "TRUNK_PLG_CLOSE_REQUEST" 24 "TRUNK_PLG_OPEN_REQUEST" 23 "TRUNK_PLG_STOP_REQUEST" 22 "TRUNK_PLG_BTN_PRESSED" 21 "CAR_FINDER_REQUEST" 20 "GLBL_WIN_UP_RQ" 19 "AirSuspCancel" 18 "AirSuspReq" 17 "ExtLightReq" 16 "PASSENGER_TOGGLE_REQUEST" 15 "DRIVER_TOGGLE_REQUEST" 14 "PANIC_TOGGLE_REQUEST" 13 "CLOSE_CONVERTIBLE_TOP" 12 "OPEN_CONVERTIBLE_TOP" 11 "GLOBAL_WINDOW_DOWN_REQUEST" 10 "REMOTE_START_OFF" 9 "REMOTE_START_ON" 8 "FLIPPER_GLASS_REQUEST" 7 "RIGHT_SLIDER_TOGGLE_REQUEST" 6 "LEFT_SLIDER_TOGGLE_REQUEST" 5 "TRUNK_PLG_TOGGLE_REQUEST" 4 "ALL_UNLOCK_REQUEST" 3 "DRIVER_UNLOCK_REQUEST" 2 "RELOCK_REQUEST" 1 "LOCK_REQUEST" 0 "NO_BASIC_REQUEST" ;
VAL_ 448 RFFobNum 15 "SNA" 8 "FOB_8" 7 "FOB_7" 6 "FOB_6" 5 "FOB_5" 4 "FOB_4" 3 "FOB_3" 2 "FOB_2" 1 "FOB_1" 0 "FOB_DEFAULT" ;
VAL_ 448 RFCfgReq 7 "SNA" 3 "DRIVER_UNLOCK_FIRST_TOGGLE" 2 "OPTICAL_CHIRP_TOGGLE" 1 "HORN_CHIRP_TOGGLE" 0 "DEFAULT" ;
VAL_ 448 KeyProgramSts 15 "SNA" 12 "KEY_NOT_PROG" 11 "BTN_DLY_INACT" 10 "BTN_DLY_ACT" 9 "SRV_SKREEM" 8 "RKE_BATT_LO" 7 "EXCD_KEY" 6 "INV_KEY" 5 "DMG_KEY" 4 "KEY_PROG" 3 "EX_KEY_PROG" 2 "PROG_ACT" 1 "EN_KEY_PROG" 0 "RKE_NORM_STAT" ;
VAL_ 388 ValImmKey 3 "SNA" 1 "CUST_IMMOB_KEY_VALID" 0 "CUST_IMMOB_KEY_DEFAULT" ;
VAL_ 388 IgnPos 7 "SNA" 5 "IGN_START" 4 "IGN_RUN" 3 "IGN_OFF_ACC" 0 "IGN_LK" ;
VAL_ 388 CustKeyInIgn 3 "SNA" 2 "CUST_KEY_IN_IGNITION" 1 "CUST_KEY_NOT_IN_IGNITION" 0 "CUST_KEY_DEFAULT" ;
VAL_ 384 SysVolt 255 "SNA" ;
VAL_ 384 IntkAirTemp 255 "SNA" ;
VAL_ 384 EngCoolTemp 255 "SNA" ;
VAL_ 384 CHRG_FAIL 1 "SNA" ;
VAL_ 384 AM_ECM_Prsnt 3 "SNA" 2 "AM_ECM_PRSNT" 0 "DEFAULT" ;
VAL_ 384 AirPress_Outsd 255 "SNA" ;
VAL_ 376 TX_WARN 0 "None" 1 "WARN_1_none" 2 "WARN_ServiceTransmissionSetParkBrakeToPreventRolling" 3 "WARN_3_none" 4 "WARN_PressBrakeAndPushButtonToShiftIntoGear" 5 "WARN_ServiceShifterStopSafelyShutoffEngine" 6 "WARN_ServiceShifter" 7 "WARN_7" 8 "WARN_8" 9 "WARN_9" 10 "WARN_10" 11 "WARN_ManualShiftTemporarilyUnavailable" 12 "WARN_ServiceTransPressBrakeWhenStoppedToKeyOffEngine" 13 "WARN_13" 14 "WARN_14" 15 "SNA" ;
VAL_ 376 TX_TEMP 255 "SNA" ;
VAL_ 376 TX_FAULT 3 "SNA" 1 "TPF" 0 "OK" ;
VAL_ 368 SHFT_PROG 255 "SNA" 254 "TX_TOW" 253 "OD_OFF" 252 "TX_NORM" 251 "TX_SPORT" 250 "Sport_Plus" 87 "W" 83 "S" 77 "M" 65 "A" 64 "E_MODE" 32 "BLANK" 24 "UPSHIFT_IND_RQ" 16 "SKIP_SHFT" 12 "SAND" 11 "MUD" 7 "SNOW" 5 "VALET" 4 "TRACK" 3 "HDC" 2 "SSC" 1 "LOW" ;
VAL_ 368 PRNDL_DISP 255 "SNA" 254 "NOT_N" 135 "SNOW" 133 "D5" 132 "D4" 131 "D3" 130 "D2" 128 "DS" 83 "S" 82 "R" 80 "P" 78 "N" 77 "M" 76 "L" 70 "F" 68 "D" 65 "A" 57 "NINE" 56 "EIGHT" 55 "SEVEN" 54 "SIX" 53 "FIVE" 52 "FOUR" 51 "THREE" 50 "TWO" 49 "ONE" 32 "BLANK" ;
VAL_ 368 PRNDL_Blink 7 "M_TIP" 6 "S" 5 "L" 4 "D" 3 "N" 2 "R" 1 "P" 0 "NONE" ;
VAL_ 368 PRND_STAT 7 "SNA" 5 "NOT_R" 4 "LVR_D" 2 "LVR_N" 1 "LVR_R" 0 "LVR_P" ;
VAL_ 368 APCM_Rq 3 "SNA" 2 "PENDING" 1 "ON" 0 "OFF" ;
VAL_ 344 WhlRPM_RR 16383 "SNA" ;
VAL_ 344 WhlRPM_RL 16383 "SNA" ;
VAL_ 344 WhlRPM_FR 16383 "SNA" ;
VAL_ 344 WhlRPM_FL 16383 "SNA" ;
VAL_ 344 WhlDir_RR_Stat 3 "SNA" 2 "BACKWARD" 1 "FORWARD" 0 "VOID" ;
VAL_ 344 WhlDir_RL_Stat 3 "SNA" 2 "BACKWARD" 1 "FORWARD" 0 "VOID" ;
VAL_ 344 WhlDir_FR_Stat 3 "SNA" 2 "BACKWARD" 1 "FORWARD" 0 "VOID" ;
VAL_ 344 WhlDir_FL_Stat 3 "SNA" 2 "BACKWARD" 1 "FORWARD" 0 "VOID" ;
VAL_ 332 VehYawRate_Raw 65535 "SNA" ;
VAL_ 332 VehYawRate_Offset 255 "SNA" ;
VAL_ 332 VehAccel_Y_Offset 255 "SNA" ;
VAL_ 332 VehAccel_Y 255 "SNA" ;
VAL_ 332 VehAccel_X_Offset 255 "SNA" ;
VAL_ 332 VehAccel_X 255 "SNA" ;
VAL_ 331 PTS_Brk_Rq_RspSts 3 "SNA" 2 "FAULTED" 1 "ACTIVE" 0 "OFF" ;
VAL_ 331 HSA_BrkPrss 63 "SNA" ;
VAL_ 331 BrkPrss_TMC 2047 "SNA" ;
VAL_ 324 OUTPUT_SPEED 65535 "SNA" ;
VAL_ 324 Gr_Target 15 "SNA" 14 "ABBRUCH" 13 "P" 12 "R2" 11 "R" 10 "D9" 9 "D2P" 8 "D8" 7 "D7" 6 "D6" 5 "D5" 4 "D4" 3 "D3" 2 "D2" 1 "D1" 0 "N" ;
VAL_ 324 Gr 15 "SNA" 14 "KRAFTFREI" 13 "P" 12 "R2" 11 "R" 10 "D9" 9 "D2P" 8 "D8" 7 "D7" 6 "D6" 5 "D5" 4 "D4" 3 "D3" 2 "D2" 1 "D1" 0 "N" ;
VAL_ 320 SPCR_AS_Off_Rq 3 "SPCR_NA" 2 "AS_CNTS_OFF" 1 "AS_TMP_OFF" 0 "IDLE" ;
VAL_ 320 RollTestMd_Actv 3 "SNA" 2 "NDEF2" 1 "ON" 0 "OFF" ;
VAL_ 320 REF_VEH_SPEED 1023 "SNA" ;
VAL_ 320 ESP_Sys_Stat 3 "ABGAS" 2 "HALF" 1 "NORM" 0 "ABSERR" ;
VAL_ 320 DTR_CC_Engaged 0 "SNA" ;
VAL_ 320 DTR_CC_Enabled 0 "SNA" ;
VAL_ 320 BrkPdl_Stat 3 "SNA" 2 "NDEF2" 1 "PSD" 0 "UPSTOP" ;
VAL_ 320 Brk_Stat 3 "SNA" 2 "NDEF2" 1 "BRAKING" 0 "IDLE" ;
VAL_ 308 V_MAX_TM 255 "SNA" ;
VAL_ 308 Rel_Thrt_ENG 255 "SNA" ;
VAL_ 308 Rel_Pdl_ENG 255 "SNA" ;
VAL_ 308 MAP_ENG 255 "SNA" ;
VAL_ 308 CRUISE_ON 0 "SNA" ;
VAL_ 308 CRUISE_EGD 0 "SNA" ;
VAL_ 308 BARO_ENG 255 "SNA" ;
VAL_ 300 EPS_Warn_Disp_Rq 7 "SNA" 3 "SERV_HI" 2 "ERR2" 1 "ERR" 0 "OK" ;
VAL_ 300 EPS_MODE_STAT 7 "SNA" 3 "LAST" 2 "MODE_3" 1 "MODE_2" 0 "MODE_1" ;
VAL_ 300 EPS_Curr 255 "SNA" ;
VAL_ 300 EPS_AsstStat 7 "SNA" 2 "AST_RT" 1 "AST_OFF" 0 "AST_ACT" ;
VAL_ 292 WhlPlsCnt_RR 255 "SNA" ;
VAL_ 292 WhlPlsCnt_RL 255 "SNA" ;
VAL_ 292 WhlPlsCnt_FR 255 "SNA" ;
VAL_ 292 WhlPlsCnt_FL 255 "SNA" ;
VAL_ 290 NMOTS 65535 "SNA" ;
VAL_ 290 GrMax_Rq_ECM 7 "G7" 6 "G6" 5 "G5" 4 "G4" 3 "G3" 2 "G2" 1 "G1" 0 "PASSIVE" ;
VAL_ 288 AccelPdlPosn 255 "SNA" ;
VAL_ 284 VEH_SPEED 65535 "SNA" ;
VAL_ 284 BrkTrq_D 4095 "SNA" ;
VAL_ 284 BrkTrq 4095 "SNA" ;
VAL_ 280 StartRelayBCMCmd 0 "SNA" ;
VAL_ 274 StTyp 7 "SNA" 3 "REM_ST" 2 "TIP_ST" 1 "NOR_ST" 0 "ST_NOT_ACT" ;
VAL_ 274 KeyInIgn 3 "SNA" 2 "KEY_IN_IGN" 1 "KEY_NOT_IN_IGN" 0 "KEY_DEF" ;
VAL_ 274 CmdIgnStat 7 "SNA" 5 "IGN_START" 4 "IGN_RUN" 3 "IGN_OFF_ACC" 0 "IGN_LK" ;
VAL_ 268 EngTrq_Rq_ESC 8191 "SNA" ;
VAL_ 268 DAS_RqActv 7 "SNA" 4 "LSCM" 3 "ABA" 2 "CMS" 1 "ACC" 0 "IDLE" ;
VAL_ 264 EngRPM 65535 "SNA" ;
VAL_ 264 ECM_IMMO_STAT_CANC 3 "SNA" 2 "RUN" 1 "KILL" 0 "IS" ;
VAL_ 258 VLRW 16383 "SNA" ;
VAL_ 258 LRWS_ST 3 "ERR_INI" 2 "ERR" 1 "INI" 0 "OK" ;
VAL_ 258 LRW 16383 "SNA" ;
VAL_ 257 RAD_FAN1_STAT 255 "SNA" ;
VAL_ 257 ECM_SKIM_STAT 3 "SNA" 2 "RUN" 1 "KILL" 0 "OK" ;
VAL_ 168 DrvrIntndedAxleTorq 16383 "SNA" ;
VAL_ 1083 WakeupRsn_EBCM 0 "NETWORK" 1 "BP" 255 "SNA" ;
VAL_ 1083 WakeupCnt_EBCM 255 "SNA" ;
VAL_ 1083 Nw_Id_EBCM 0 "POWERTRAIN" 1 "BODY" 2 "AUDIO_TELE" 255 "SNA" ;
VAL_ 1083 NM_Ud_Srv_EBCM 2 "WAKEUP_SA" 15 "AWAKE_BC" 255 "NO_USER_DATA" ;
VAL_ 1083 NM_Ud_Launch_EBCM 4 "BROADCAST" 63 "SNA" ;
VAL_ 1083 NM_Successor_EBCM 255 "SNA" ;
VAL_ 1083 NM_Mode_EBCM 252 "LHOM" 253 "RING" 254 "ALIVE" 255 "SNA" ;
